CM_ "IMPORT _hyundai_canfd_ccnc_common.dbc";

BO_ 53 ACCELERATOR: 32 XXX
 SG_ CHECKSUM : 0|16@1+ (1,0) [0|65535] "" XXX
 SG_ COUNTER : 16|8@1+ (1,0) [0|255] "" XXX
 SG_ ACCELERATOR_PEDAL : 40|8@1+ (1,0) [0|255] "" XXX
 SG_ GEAR : 192|3@1+ (1,0) [0|7] "" XXX

BO_ 64 GEAR_ALT: 32 XXX
 SG_ CHECKSUM : 0|16@1+ (1,0) [0|65535] "" XXX
 SG_ COUNTER : 16|8@1+ (1,0) [0|255] "" XXX
 SG_ GEAR : 32|3@1+ (1,0) [0|7] "" XXX

BO_ 69 GEAR: 24 XXX
 SG_ CHECKSUM : 0|16@1+ (1,0) [0|65535] "" XXX
 SG_ COUNTER : 16|8@1+ (1,0) [0|255] "" XXX
 SG_ GEAR : 44|3@1+ (1,0) [0|7] "" XXX

BO_ 74 IMU_01_10ms: 32 CGW_CCU
 SG_ IMU_Crc1Val : 0|16@1+ (1,0) [0|0] ""  ECS,ESC,FCU_C,GW_RGW,ICSC,MDPS,RCU,RWS,SFA,VPC_C
 SG_ IMU_AlvCnt1Val : 16|8@1+ (1,0) [0|0] ""  ECS,ESC,FCU_C,GW_RGW,ICSC,MDPS,RCU,RWS,SFA,VPC_C
 SG_ IMU_YawSigSta : 24|4@1+ (1,0) [0|15] ""  CLU,ADAS_PRK,FR_CMR,RR_C_RDR
 SG_ IMU_LatAccelSigSta : 28|4@1+ (1,0) [0|15] ""  CLU,ADAS_PRK,FR_CMR,RR_C_RDR
 SG_ IMU_LongAccelSigSta : 32|4@1+ (1,0) [0|15] ""  CLU,ADAS_PRK,FR_CMR,RR_C_RDR
 SG_ IMU_VerAccelSigSta : 36|4@1+ (1,0) [0|15] "" XXX
 SG_ IMU_McuVoltSta : 40|4@1+ (1,0) [0|15] "" XXX
 SG_ IMU_AcuRstSta : 44|4@1+ (1,0) [0|15] "" XXX
 SG_ IMU_SnsrTyp : 48|8@1+ (1,0) [0|255] "" XXX
 SG_ IMU_RollSigSta : 56|8@1+ (1,0) [0|255] "" XXX
 SG_ IMU_YawRtVal : 64|16@1+ (0.005,-163.84) [-163.84|163.835] "Deg/s"  CLU,ADAS_PRK,FR_CMR,RR_C_RDR
 SG_ IMU_LatAccelVal : 80|16@1+ (0.000127465,-4.17677312) [-4.17677312|4.176645655] "g"  CLU,ADAS_PRK,FR_CMR,RR_C_RDR
 SG_ IMU_LongAccelVal : 96|16@1+ (0.000127465,-4.17677312) [-4.17677312|4.176645655] "g"  CLU,ADAS_PRK,FR_CMR,RR_C_RDR
 SG_ IMU_SnsrTempVal : 112|16@1+ (1,0) [0|65535] "" XXX
 SG_ IMU_SeralNumVal : 128|64@1+ (1,0) [0|1.84467440737096e+19] "" XXX
 SG_ IMU_RollRtVal : 192|16@1+ (0.005,-163.84) [0|0] "º/s" XXX
 SG_ IMU_VerAccelVal : 208|8@1+ (1,0) [0|255] "" XXX

BO_ 96 ESP_STATUS: 32 XXX
 SG_ CHECKSUM : 0|16@1+ (1,0) [0|65535] "" XXX
 SG_ COUNTER : 16|8@1+ (1,0) [0|255] "" XXX
 SG_ TRACTION_AND_STABILITY_CONTROL : 42|3@1+ (1,0) [0|63] "" XXX
 SG_ BRAKE_PRESSURE : 128|10@1+ (1,0) [0|65535] "" XXX
 SG_ BRAKE_PRESSED : 148|1@1+ (1,0) [0|3] "" XXX

BO_ 101 BRAKE: 32 XXX
 SG_ CHECKSUM : 0|16@1+ (1,0) [0|65535] "" XXX
 SG_ COUNTER : 16|8@1+ (1,0) [0|255] "" XXX
 SG_ BRAKE_POSITION : 40|16@1- (1,0) [0|65535] "" XXX
 SG_ BRAKE_PRESSED : 57|1@1+ (1,0) [0|3] "" XXX

BO_ 112 GEAR_ALT_2: 32 XXX
 SG_ CHECKSUM : 0|16@1+ (1,0) [0|65535] "" XXX
 SG_ COUNTER : 16|8@1+ (1,0) [0|255] "" XXX
 SG_ GEAR : 60|3@1+ (1,0) [0|7] "" XXX

BO_ 160 WHEEL_SPEEDS: 24 XXX
 SG_ CHECKSUM : 0|16@1+ (1,0) [0|65535] "" XXX
 SG_ COUNTER : 16|8@1+ (1,0) [0|255] "" XXX
 SG_ MOVING_FORWARD : 56|1@0+ (1,0) [0|1] "" XXX
 SG_ MOVING_BACKWARD : 57|1@0+ (1,0) [0|1] "" XXX
 SG_ MOVING_FORWARD2 : 58|1@0+ (1,0) [0|1] "" XXX
 SG_ MOVING_BACKWARD2 : 59|1@0+ (1,0) [0|1] "" XXX
 SG_ WHL_SpdFLVal : 64|14@1+ (0.03125,0) [0|0] "km^h" XXX
 SG_ WHL_SpdFRVal : 80|14@1+ (0.03125,0) [0|0] "km^h" XXX
 SG_ WHL_SpdRLVal : 96|14@1+ (0.03125,0) [0|0] "km^h" XXX
 SG_ WHL_SpdRRVal : 112|14@1+ (0.03125,0) [0|0] "km^h" XXX

BO_ 203 LFA_ALT: 24 CGW_CCU
 SG_ CHECKSUM : 0|16@1+ (1,0) [0|0] "0" FCU_C,GW_RGW,MDPS,SFA
 SG_ COUNTER : 16|8@1+ (1,0) [0|0] "0" FCU_C,GW_RGW,MDPS,SFA
 SG_ ADAS_ActvACISta : 24|4@1+ (1,0) [0|0] "" GW_RGW,MDPS,SFA
 SG_ ADAS_ActvACILvl2Sta : 28|4@1+ (1,0) [0|0] "" ESC,FCU_C,GW_RGW,MDPS,SFA,VPC_C
 SG_ ADAS_StrAnglReqVal : 32|14@1- (0.1,0) [0|119.9] "Deg" GW_RGW,MDPS,SFA
 SG_ ADAS_ACIAnglTqRedcGainVal : 48|8@1+ (0.004,0) [0|1] "" GW_RGW,MDPS,SFA
 SG_ FCA_ESA_ActvSta : 56|2@1+ (1,0) [0|0] "" GW_RGW,MDPS,SFA
 SG_ FCA_ESA_TqBstGainVal : 64|8@1+ (0.004,0) [0|0] "" GW_RGW,MDPS,SFA

BO_ 229 ESC_02_10ms: 32 CGW
 SG_ ESC_YawSigSta : 24|4@1+ (1,0) [0|15] ""  CLU,ADAS_PRK,FR_CMR,RR_C_RDR
 SG_ ESC_LatAccelSigSta : 28|4@1+ (1,0) [0|15] ""  CLU,ADAS_PRK,FR_CMR,RR_C_RDR
 SG_ ESC_LongAccelSigSta : 32|4@1+ (1,0) [0|15] ""  CLU,ADAS_PRK,FR_CMR,RR_C_RDR
 SG_ ESC_YawRtVal : 64|16@1+ (0.005,-163.84) [-163.84|163.835] "Deg/s"  CLU,ADAS_PRK,FR_CMR,RR_C_RDR
 SG_ ESC_LatAccelVal : 80|16@1+ (0.000127465,-4.17677312) [-4.17677312|4.176645655] "g"  CLU,ADAS_PRK,FR_CMR,RR_C_RDR
 SG_ ESC_LongAccelVal : 96|16@1+ (0.000127465,-4.17677312) [-4.17677312|4.176645655] "g"  CLU,ADAS_PRK,FR_CMR,RR_C_RDR

BO_ 234 MDPS: 24 SFA
 SG_ CHECKSUM : 0|16@1+ (1,0) [0|0] "" CGW_CCU,ESC,ICSC,RCU,RWA,RWS,VPC_C
 SG_ COUNTER : 16|8@1+ (1,0) [0|0] "" CGW_CCU,ESC,ICSC,RCU,RWA,RWS,VPC_C
 SG_ MDPS_WrngLmpSta : 24|3@1+ (1,0) [0|0] "" CGW_CCU,ESC,ICSC,RCU,RWA,RWS
 SG_ MDPS_Typ : 27|3@1+ (1,0) [0|0] "" CGW_CCU,ICSC,RWA
 SG_ MDPS_EngIdleRpmReq : 30|2@1+ (1,0) [0|0] "" CGW_CCU,RWA
 SG_ MDPS_VsmPlgInSta : 32|2@1+ (1,0) [0|0] "flag" ESC,ICSC,RCU,RWA
 SG_ MDPS_VsmDfctvSta : 34|2@1+ (1,0) [0|0] "" ESC,ICSC,RCU,RWA
 SG_ MDPS_VsmSigErrSta : 36|2@1+ (1,0) [0|0] "" ESC,RCU,RWA
 SG_ MDPS_PaPlugInSta : 38|2@1+ (1,0) [0|0] "" CGW_CCU,ESC,RCU,RWA
 SG_ MDPS_PaModeSta : 40|4@1+ (1,0) [0|0] "" CGW_CCU,RWA
 SG_ MDPS_PaCanfltSta : 44|2@1+ (1,0) [0|0] "" CGW_CCU,RWA
 SG_ MDPS_LkaPlgInSta : 46|2@1+ (1,0) [0|0] "" CGW_CCU,ICSC,RWA
 SG_ MDPS_LkaToiActvSta : 48|2@1+ (1,0) [0|0] "" CGW_CCU,RWA
 SG_ MDPS_LkaToiUnblSta : 50|2@1+ (1,0) [0|0] "" CGW_CCU,RWA
 SG_ MDPS_LkaToiFltSta : 52|2@1+ (1,0) [0|0] "" CGW_CCU,RWA
 SG_ MDPS_LkaFailSta : 54|2@1+ (1,0) [0|0] "" CGW_CCU,RWA
 SG_ MDPS_ResetOpSta : 59|2@1+ (1,0) [0|0] "" Vector__XXX
 SG_ MDPS_CurrModVal : 61|3@1+ (1,0) [0|0] "" CGW_CCU,RWA
 SG_ MDPS_OutTqVal : 64|12@1+ (0.1,-204.8) [0|0] "Nm" CGW_CCU,ESC,ICSC,RCU,RWA
 SG_ MDPS_VsmActResp : 76|2@1+ (1,0) [0|0] "" ESC,RCU,RWA
 SG_ Reprogram_State_MDPS : 78|2@1+ (1,0) [0|0] "" CGW_CCU
 SG_ MDPS_StrTqSnsrVal : 80|13@1+ (1,-4095) [0|4095] "" CGW_CCU,ESC,ICSC,RCU,RWA,VPC_C
 SG_ MDPS_PaStrAnglVal : 96|16@1- (0.1,0) [0|0] "Deg" CGW_CCU,RWA
 SG_ MDPS_LoamModSta : 112|2@1+ (1,0) [0|0] "" CGW_CCU,RWA
 SG_ MDPS_HDPSpprtSWVer : 114|5@1+ (1,0) [0|0] "" CGW_CCU,RWA
 SG_ MDPS_ADASAciActvSta : 120|4@1+ (1,0) [0|0] "" CGW_CCU,ESC,RWA,RWS
 SG_ MDPS_ADASAciPluginSta : 124|2@1+ (1,0) [0|0] "" RWA
 SG_ MDPS_ADAS_AciFltSig : 126|2@1+ (1,0) [0|0] "" CGW_CCU,ESC,RWA
 SG_ MDPS_EstStrAnglVal : 128|16@1- (0.1,0) [0|0] "Deg" CGW_CCU,RWA,RWS
 SG_ MDPS_ADASAciActvSta_Lv2 : 144|4@1+ (1,0) [0|0] "" CGW_CCU,RWA
 SG_ MDPS_ADAS_AciFltSig_Lv2 : 148|3@1+ (1,0) [0|0] "" CGW_CCU,RWA
 SG_ MDPS_TpaPlugInSta : 152|2@1+ (1,0) [0|0] "" RWA,VPC_C
 SG_ MDPS_TpaCanfltSta : 154|2@1+ (1,0) [0|0] "" RWA,VPC_C
 SG_ MDPS_TpaModeSta : 156|4@1+ (1,0) [0|0] "" RWA,VPC_C
 SG_ MDPS_TpaStrAnglVal : 160|16@1- (0.1,0) [0|0] "Deg" RWA,VPC_C

BO_ 256 ACCELERATOR_BRAKE_ALT: 32 XXX
 SG_ CHECKSUM : 0|16@1+ (1,0) [0|65535] "" XXX
 SG_ COUNTER : 16|8@1+ (1,0) [0|255] "" XXX
 SG_ BRAKE_PRESSED : 32|1@1+ (1,0) [0|1] "" XXX
 SG_ ACCELERATOR_PEDAL_PRESSED : 176|1@1+ (1,0) [0|1] "" XXX

BO_ 261 ACCELERATOR_ALT: 32 XXX
 SG_ CHECKSUM : 0|16@1+ (1,0) [0|65535] "" XXX
 SG_ COUNTER : 16|8@1+ (1,0) [0|255] "" XXX
 SG_ ACCELERATOR_PEDAL : 103|10@1+ (0.25,0) [0|1022] "" XXX

BO_ 272 LKAS_ALT: 32 XXX
 SG_ CHECKSUM : 0|16@1+ (1,0) [0|65535] "" XXX
 SG_ COUNTER : 16|8@1+ (1,0) [0|255] "" XXX
 SG_ LKA_OptUsmSta : 24|3@1+ (1,0) [0|7] "" ADAS_DRV
 SG_ LKA_RcgSta : 27|3@1+ (1,0) [0|7] "" ADAS_DRV
 SG_ LKA_LHLnWrnSta : 30|2@1+ (1,0) [0|3] "" ADAS_DRV
 SG_ LKA_RHLnWrnSta : 32|2@1+ (1,0) [0|3] "" ADAS_DRV
 SG_ LKA_HndsoffSnd : 34|2@1+ (1,0) [0|3] "" ADAS_DRV
 SG_ LKA_StrSnd : 36|2@1+ (1,0) [0|3] "" ADAS_DRV
 SG_ LKA_SysIndReq : 38|3@1+ (1,0) [0|7] "" ADAS_DRV
 SG_ StrTqReqVal : 41|11@1+ (1,-1024) [0|4095] "" XXX
 SG_ ActToiSta : 52|2@1+ (1,0) [0|3] "" ADAS_DRV
 SG_ ToiFltSta : 54|2@1+ (1,0) [0|3] "" ADAS_DRV
 SG_ LFA_BUTTON : 56|1@1+ (1,0) [0|255] "" XXX
 SG_ LKA_SysWrn : 60|4@1+ (1,0) [0|15] "" ADAS_DRV
 SG_ Damping_Gain : 64|8@1+ (1,0) [0|255] "" CGW
 SG_ LKAS_ANGLE_ACTIVE : 77|2@0+ (1,0) [0|3] "" XXX
 SG_ LKA_UsmMod : 80|2@1+ (1,0) [0|3] "" ADAS_DRV
 SG_ ADAS_StrAnglReqVal : 82|14@1- (0.1,0) [0|176.7] "Deg" GW_RGW,MDPS,SFA
 SG_ ADAS_ACIAnglTqRedcGainVal : 96|8@1+ (0.004,0) [0|1] "" GW_RGW,MDPS,SFA
 SG_ FCA_ESA_CtrlSta : 107|1@0+ (1,0) [0|1] "" XXX
 SG_ NEW_SIGNAL_1 : 72|2@1+ (1,0) [0|3] "" XXX
 SG_ NEW_SIGNAL_2 : 74|2@1+ (1,0) [0|3] "" XXX
 SG_ NEW_SIGNAL_3 : 104|1@1+ (1,0) [0|1] "" XXX
 SG_ NEW_SIGNAL_4 : 105|1@1+ (1,0) [0|1] "" XXX
 SG_ NEW_SIGNAL_5 : 106|1@1+ (1,0) [0|1] "" XXX
 SG_ NEW_SIGNAL_6 : 109|1@1+ (1,0) [0|1] "" XXX
 SG_ NEW_SIGNAL_7 : 225|1@1+ (1,0) [0|1] "" XXX
 SG_ NEW_SIGNAL_8 : 228|1@1+ (1,0) [0|1] "" XXX
 SG_ NEW_SIGNAL_9 : 231|1@1+ (1,0) [0|1] "" XXX
 SG_ NEW_SIGNAL_10 : 232|1@1+ (1,0) [0|1] "" XXX
 SG_ NEW_SIGNAL_11 : 240|16@1+ (1,0) [0|65535] "" XXX

BO_ 282 FR_CMR_01_10ms: 16 FR_CMR
 SG_ FR_CMR_Crc1Val : 0|16@1+ (1,0) [0|0] "" Dummy,IBU_HS,vBDM
 SG_ FR_CMR_AlvCnt1Val : 16|8@1+ (1,0) [0|0] "" CLU,IBU_HS,vBDM
 SG_ HBA_SysOptSta : 24|2@1+ (1,0) [0|3] "" CLU,IBU_HS,vBDM
 SG_ HBA_SysSta : 26|3@1+ (1,0) [0|7] "" CLU,IBU_HS,vBDM
 SG_ HBA_IndLmpReq : 29|2@1+ (1,0) [0|3] "" CLU,vBDM
 SG_ iHBAref_VehLftSta : 31|2@1+ (1,0) [0|3] "" IBU_HS,ICU,vBDM
 SG_ iHBAref_VehCtrSta : 33|2@1+ (1,0) [0|3] "" IBU_HS,ICU,vBDM
 SG_ iHBAref_VehRtSta : 35|2@1+ (1,0) [0|3] "" IBU_HS,ICU,vBDM
 SG_ iHBAref_ILLAmbtSta : 37|2@1+ (1,0) [0|3] "" IBU_HS,ICU,vBDM
 SG_ FCA_Equip_MFC : 39|3@1+ (1,0) [0|0] "" ADAS_DRV,RR_C_RDR,vBDM
 SG_ HBA_OptUsmSta : 42|2@1+ (1,0) [0|3] "" CLU,H_U_MM
 SG_ FCAref_FusSta : 45|3@1+ (1,0) [0|0] "" vBDM
 SG_ DAW_LVDA_PUDis : 48|2@1+ (1,0) [0|0] "" CLU,vBDM
 SG_ DAW_LVDA_OptUsmSta : 50|2@1+ (1,0) [0|3] "" CLU,H_U_MM,vBDM
 SG_ DAW_OptUsmSta : 52|3@1+ (1,0) [0|0] "" CLU,H_U_MM
 SG_ DAW_SysSta : 55|4@1+ (1,0) [0|0] "" CLU
 SG_ DAW_WrnMsgSta : 59|3@1+ (1,0) [0|0] "" CLU
 SG_ DAW_TimeRstReq : 62|2@1+ (1,0) [0|0] "" CLU
 SG_ DAW_SnstvtyModRetVal : 64|3@1+ (1,0) [0|0] "" CLU,H_U_MMz
 SG_ FR_CMR_SCCEquipSta : 85|2@1+ (1,0) [0|3] "" CGW
 SG_ FR_CMR_ReqADASMapMsgVal : 96|16@1+ (1,0) [0|65535] "" CGW
 SG_ FR_CMR_SwVer1Val : 112|4@1+ (1,0) [0|15] "" CGW
 SG_ FR_CMR_SwVer2Val : 120|8@1+ (1,0) [0|255] "" CGW
 SG_ NEW_SIGNAL_1 : 69|2@1+ (1,0) [0|3] "" XXX
 SG_ NEW_SIGNAL_2 : 72|1@1+ (1,0) [0|1] "" XXX
 SG_ NEW_SIGNAL_3 : 74|1@1+ (1,0) [0|1] "" XXX

BO_ 293 STEERING_SENSORS: 16 XXX
 SG_ CHECKSUM : 0|16@1+ (1,0) [0|65535] "" XXX
 SG_ COUNTER : 16|8@1+ (1,0) [0|255] "" XXX
 SG_ STEERING_ANGLE : 24|16@1- (0.1,0) [0|255] "deg" XXX
 SG_ STEERING_RATE : 40|8@1+ (4,0) [0|1016] "deg/s" XXX

BO_ 298 LFA: 16 ADRV
 SG_ CHECKSUM : 0|16@1+ (1,0) [0|65535] "" CLU,CGW
 SG_ COUNTER : 16|8@1+ (1,0) [0|255] "" CLU,CGW
 SG_ LKA_OptUsmSta : 24|3@1+ (1,0) [0|7] "" CLU,CGW
 SG_ LKA_RcgSta : 27|3@1+ (1,0) [0|7] "" CLU,CGW
 SG_ LKA_LHLnWrnSta : 30|2@1+ (1,0) [0|3] "" CLU,CGW
 SG_ LKA_RHLnWrnSta : 32|2@1+ (1,0) [0|3] "" CLU,CGW
 SG_ LKA_HndsoffSnd : 34|2@1+ (1,0) [0|3] "" CLU,CGW
 SG_ LKA_StrSnd : 36|2@1+ (1,0) [0|3] "" CLU,CGW
 SG_ LKA_SysIndReq : 38|3@1+ (1,0) [0|7] "" CLU,RR_C_RDR,CGW
 SG_ StrTqReqVal : 41|11@1+ (1,-1024) [0|4095] "" XXX
 SG_ ActToiSta : 52|2@1+ (1,0) [0|3] "" CLU,CGW
 SG_ ToiFltSta : 54|2@1+ (1,0) [0|3] "" CGW
 SG_ LFA_BUTTON : 56|1@0+ (1,0) [0|255] "" XXX
 SG_ BCA_Rear_WrnSta : 57|3@1+ (1,0) [0|255] "" ADRV
 SG_ LKA_SysWrn : 60|4@1+ (1,0) [0|15] "" CLU,CGW
 SG_ FCA_LO_WrnSta : 64|1@1+ (1,0) [0|1] "" ADRV
 SG_ FCA_LS_WrnSta : 68|1@1+ (1,0) [0|1] "" ADRV
 SG_ LKA_OnOffEquip2Sta : 72|2@1+ (1,0) [0|255] "" ADRV
 SG_ LKA_UsmMod : 80|2@1+ (1,0) [0|3] "" CLU,CGW
 SG_ Info_PedtrnDst : 84|3@0+ (1,0) [0|7] "" ADAS_DRV
 SG_ ELK_SysFlrSta : 85|5@1+ (1,0) [0|31] "" ADRV
 SG_ ELK_SymbDisp : 90|3@1+ (1,0) [0|7] "" ADRV
 SG_ FCA_ESA_WrnSta : 93|1@1+ (1,0) [0|7] "" ADRV
 SG_ FCA_ESA_CtrlSta : 101|1@1+ (1,0) [0|7] "" ADRV
 SG_ Damping_Gain : 104|8@1+ (1,0) [0|255] "" CGW
 SG_ NEW_SIGNAL_1 : 74|2@1+ (1,0) [0|3] "" XXX
 SG_ NEW_SIGNAL_2 : 78|2@1+ (1,0) [0|3] "" XXX
 SG_ NEW_SIGNAL_3 : 98|3@1+ (1,0) [0|7] "" XXX

BO_ 304 GEAR_SHIFTER: 16 XXX
 SG_ CHECKSUM : 0|16@1+ (1,0) [0|65535] "" XXX
 SG_ COUNTER : 16|8@1+ (1,0) [0|255] "" XXX
 SG_ PARK_BUTTON : 32|2@1+ (1,0) [0|3] "" XXX
 SG_ KNOB_POSITION : 40|3@1+ (1,0) [0|3] "" XXX
 SG_ GEAR : 64|3@1+ (1,0) [0|7] "" XXX

BO_ 352 ADRV_0x160: 16 ADRV
 SG_ CHECKSUM : 0|16@1+ (1,0) [0|65535] "" XXX
 SG_ COUNTER : 16|8@1+ (1,0) [0|255] "" XXX
 SG_ AEB_SETTING : 24|2@1+ (1,0) [0|255] "" XXX
 SG_ SET_ME_2 : 56|8@1+ (1,0) [0|1] "" XXX
 SG_ SET_ME_FF : 64|8@1+ (1,0) [0|255] "" XXX
 SG_ SET_ME_FC : 72|8@1+ (1,0) [0|255] "" XXX
 SG_ SET_ME_9 : 80|8@1+ (1,0) [0|255] "" XXX
 SG_ NEW_SIGNAL_1 : 30|1@1+ (1,0) [0|1] "" XXX
 SG_ NEW_SIGNAL_2 : 48|1@1+ (1,0) [0|1] "" XXX
 SG_ NEW_SIGNAL_3 : 55|1@1+ (1,0) [0|1] "" XXX
 SG_ NEW_SIGNAL_4 : 88|1@1+ (1,0) [0|1] "" XXX
 SG_ NEW_SIGNAL_5 : 90|1@1+ (1,0) [0|1] "" XXX
 SG_ NEW_SIGNAL_6 : 99|1@1+ (1,0) [0|1] "" XXX
 SG_ NEW_SIGNAL_7 : 115|2@1+ (1,0) [0|3] "" XXX

BO_ 353 CCNC_0x161: 32 CCNC
 SG_ CHECKSUM : 0|16@1+ (1,0) [0|65535] "" XXX
 SG_ COUNTER : 16|8@1+ (1,0) [0|255] "" XXX
 SG_ FCA_ICON : 24|3@1+ (1,0) [0|7] "" XXX
 SG_ FCA_ALT_ICON : 27|3@1+ (1,0) [0|7] "" XXX
 SG_ LKA_ICON : 30|3@1+ (1,0) [0|3] "" XXX
 SG_ HBA_ICON : 33|3@1+ (1,0) [0|7] "" XXX
 SG_ ZEROS_1 : 36|4@1+ (1,0) [0|15] "" XXX
 SG_ ZEROS_2 : 40|2@1+ (1,0) [0|3] "" XXX
 SG_ FCA_IMAGE : 42|3@1+ (1,0) [0|7] "" XXX
 SG_ ZEROS_3 : 45|3@1+ (1,0) [0|7] "" XXX
 SG_ ZEROS_4 : 48|3@1+ (1,0) [0|7] "" XXX
 SG_ BCA_LEFT : 51|3@1+ (1,0) [0|7] "" XXX
 SG_ BCA_RIGHT : 54|3@1+ (1,0) [0|7] "" XXX
 SG_ LCA_LEFT_ARROW : 57|3@1+ (1,0) [0|7] "" XXX
 SG_ LCA_RIGHT_ARROW : 60|3@1+ (1,0) [0|7] "" XXX
 SG_ ZEROS_5 : 63|1@0+ (1,0) [0|1] "" XXX
 SG_ CENTERLINE : 64|2@1+ (1,0) [0|3] "" XXX
 SG_ TARGET : 66|3@1+ (1,0) [0|7] "" XXX
 SG_ TARGET_DISTANCE : 69|11@1+ (0.1,0) [0|204.7] "m" XXX
 SG_ LANELINE_LEFT : 80|4@1+ (1,0) [0|15] "" XXX
 SG_ LANELINE_LEFT_POSITION : 84|6@1+ (1,0) [0|15] "" XXX
 SG_ LANELINE_RIGHT : 90|4@1+ (1,0) [0|15] "" XXX
 SG_ LANELINE_RIGHT_POSITION : 94|6@1+ (1,0) [0|3] "" XXX
 SG_ LANELINE_CURVATURE : 100|5@1- (1,15) [0|31] "" XXX
 SG_ LANE_HIGHLIGHT : 105|4@1+ (1,0) [0|15] "" XXX
 SG_ LANE_HIGHLIGHT_DISTANCE : 109|11@1+ (0.1,0) [0|204.7] "m" XXX
 SG_ LANE_LEFT : 120|3@1+ (1,0) [0|7] "" XXX
 SG_ LANE_RIGHT : 123|3@1+ (1,0) [0|7] "" XXX
 SG_ LANE_ZOOM : 126|2@1+ (1,0) [0|3] "" XXX
 SG_ ALERTS_1 : 128|6@1+ (1,0) [0|63] "" XXX
 SG_ ALERTS_2 : 134|5@1+ (1,0) [0|3] "" XXX
 SG_ ALERTS_3 : 139|5@1+ (1,0) [0|15] "" XXX
 SG_ ALERTS_4 : 144|8@1+ (1,0) [0|511] "" XXX
 SG_ ALERTS_5 : 152|5@1+ (1,0) [0|7] "" XXX
 SG_ MUTE : 157|3@1+ (1,0) [0|7] "" XXX
 SG_ SOUNDS_1 : 160|4@1+ (1,0) [0|3] "" XXX
 SG_ SOUNDS_2 : 164|4@1+ (1,0) [0|3] "" XXX
 SG_ SOUNDS_3 : 168|4@1+ (1,0) [0|15] "" XXX
 SG_ SOUNDS_4 : 172|3@1+ (1,0) [0|7] "" XXX
 SG_ ZEROS_6 : 175|1@0+ (1,0) [0|1] "" XXX
 SG_ ZEROS_7 : 176|5@1+ (1,0) [0|31] "" XXX
 SG_ SETSPEED_HUD : 181|3@1+ (1,0) [0|3] "" XXX
 SG_ DISTANCE_LEAD : 184|5@1+ (1,0) [0|31] "" XXX
 SG_ DISTANCE_CAR : 189|3@1+ (1,0) [0|7] "" XXX
 SG_ DISTANCE_SPACING : 192|4@1+ (1,0) [0|15] "" XXX
 SG_ DISTANCE : 196|4@1+ (1,0) [0|7] "" XXX
 SG_ SETSPEED_SPEED : 200|8@1+ (1,0) [0|255] "" XXX
 SG_ SETSPEED : 208|4@1+ (1,0) [0|3] "" XXX
 SG_ HDA_ICON : 212|4@1+ (1,0) [0|3] "" XXX
 SG_ SLA_ICON : 216|4@1+ (1,0) [0|15] "" XXX
 SG_ NAV_ICON : 220|4@1+ (1,0) [0|3] "" XXX
 SG_ LFA_ICON : 224|4@1+ (1,0) [0|3] "" XXX
 SG_ LCA_LEFT_ICON : 228|4@1+ (1,0) [0|15] "" XXX
 SG_ LCA_RIGHT_ICON : 232|4@1+ (1,0) [0|15] "" XXX
 SG_ BACKGROUND : 236|4@1+ (1,0) [0|15] "" XXX
 SG_ DAW_ICON : 240|3@1+ (1,0) [0|7] "" XXX
 SG_ CAR_CIRCLE : 243|3@1+ (1,0) [0|7] "" XXX
 SG_ ZEROS_8 : 246|2@1+ (1,0) [0|3] "" XXX
 SG_ ZEROS_9 : 248|8@1+ (1,0) [0|255] "" XXX

BO_ 354 CCNC_0x162: 32 CCNC
 SG_ CHECKSUM : 0|16@1+ (1,0) [0|65535] "" XXX
 SG_ COUNTER : 16|8@1+ (1,0) [0|255] "" XXX
 SG_ COUNTRY : 24|4@1+ (1,0) [0|7] "" XXX
 SG_ SPEEDLIMIT_FLASH : 28|4@1+ (1,0) [0|15] "" XXX
 SG_ SPEEDLIMIT : 32|8@1+ (1,0) [0|255] "" XXX
 SG_ SIGNS : 40|8@1+ (1,0) [0|15] "" XXX
 SG_ SPEEDLIMIT_WEATHER : 48|4@1+ (1,0) [0|15] "" XXX
 SG_ VIBRATE : 52|3@1+ (1,0) [0|7] "" XXX
 SG_ ZEROS_1 : 55|1@0+ (1,0) [0|1] "" XXX
 SG_ ZEROS_2 : 56|8@1+ (1,0) [0|255] "" XXX
 SG_ LEAD : 64|5@1+ (1,0) [0|31] "" XXX
 SG_ LEAD_DISTANCE : 69|11@1+ (0.1,0) [0|204.7] "m" XXX
 SG_ LEAD_LATERAL : 80|7@1+ (0.1,0) [0|127] "m" XXX
 SG_ ZEROS_3 : 87|1@0+ (1,0) [0|1] "" XXX
 SG_ LEAD_ALT : 88|5@1+ (1,0) [0|31] "" XXX
 SG_ LEAD_ALT_DISTANCE : 93|11@1+ (0.1,0) [0|204.7] "m" XXX
 SG_ LEAD_ALT_LATERAL : 104|7@1+ (0.1,0) [0|127] "m" XXX
 SG_ ZEROS_4 : 111|1@0+ (1,0) [0|1] "" XXX
 SG_ LEAD_LEFT : 112|5@1+ (1,0) [0|31] "" XXX
 SG_ LEAD_LEFT_DISTANCE : 117|11@1+ (0.1,0) [0|204.7] "m" XXX
 SG_ LEAD_LEFT_LATERAL : 128|7@1+ (0.1,0) [0|127] "m" XXX
 SG_ ZEROS_5 : 135|1@0+ (1,0) [0|1] "" XXX
 SG_ LEAD_RIGHT : 136|5@1+ (1,0) [0|31] "" XXX
 SG_ LEAD_RIGHT_DISTANCE : 141|11@1+ (0.1,0) [0|204.7] "m" XXX
 SG_ LEAD_RIGHT_LATERAL : 152|7@1+ (0.1,0) [0|127] "m" XXX
 SG_ ZEROS_6 : 159|1@0+ (1,0) [0|1] "" XXX
 SG_ ZEROS_7 : 162|3@0+ (1,0) [0|7] "" XXX
 SG_ LEAD_LEFT_REAR_STATUS : 167|5@0+ (1,0) [0|31] "" XXX
 SG_ LEAD_LEFT_REAR_DISTANCE : 175|8@0+ (0.1,0) [0|255] "m" XXX
 SG_ LEAD_LEFT_REAR_LATERAL : 182|7@0+ (0.1,0) [0|127] "m" XXX
 SG_ ZEROS_8 : 183|1@0+ (1,0) [0|1] "" XXX
 SG_ ZEROS_9 : 191|8@0+ (1,0) [0|255] "" XXX
 SG_ LEAD_RIGHT_REAR_STATUS : 196|5@0+ (1,0) [0|31] "" XXX
 SG_ LEAD_RIGHT_REAR_DISTANCE : 197|8@1+ (0.1,0) [0|255] "m" XXX
 SG_ LEAD_RIGHT_REAR_LATERAL : 205|7@1+ (0.1,0) [0|127] "m" XXX
 SG_ ZEROS_10 : 212|1@0+ (1,0) [0|1] "" XXX
 SG_ FAULT_FSS : 213|3@1+ (1,0) [0|7] "" XXX
 SG_ FAULT_FCA : 216|3@1+ (1,0) [0|7] "" XXX
 SG_ FAULT_LSS : 219|3@1+ (1,0) [0|7] "" XXX
 SG_ FAULT_SLA : 222|3@1+ (1,0) [0|7] "" XXX
 SG_ FAULT_DAW : 225|3@1+ (1,0) [0|7] "" XXX
 SG_ FAULT_HBA : 228|3@1+ (1,0) [0|7] "" XXX
 SG_ FAULT_SCC : 231|3@1+ (1,0) [0|7] "" XXX
 SG_ FAULT_LFA : 234|3@1+ (1,0) [0|7] "" XXX
 SG_ FAULT_HDA : 237|3@1+ (1,0) [0|7] "" XXX
 SG_ FAULT_LCA : 240|3@1+ (1,0) [0|7] "" XXX
 SG_ FAULT_HDP : 243|3@1+ (1,0) [0|7] "" XXX
 SG_ FAULT_DAS : 246|3@1+ (1,0) [0|7] "" XXX
 SG_ FAULT_ESS : 249|3@1+ (1,0) [0|7] "" XXX
 SG_ ZEROS_11 : 252|4@1+ (1,0) [0|15] "" XXX

BO_ 357 SPAS1: 24 APRK
 SG_ CHECKSUM : 0|16@1+ (1,0) [0|65535] "" XXX
 SG_ COUNTER : 16|8@1+ (1,0) [0|0] "" XXX
 SG_ NEW_SIGNAL_2 : 90|3@1+ (1,0) [0|0] "" XXX
 SG_ NEW_SIGNAL_1 : 96|16@1- (0.1,0) [0|0] "" XXX

BO_ 362 SPAS2: 32 APRK
 SG_ CHECKSUM : 0|16@1+ (1,0) [0|65535] "" XXX
 SG_ COUNTER : 16|8@1+ (1,0) [0|0] "" XXX
 SG_ BLINKER_CONTROL : 133|3@1+ (1,0) [0|0] "" XXX

BO_ 373 TCS: 24 XXX
 SG_ CHECKSUM : 0|16@1+ (1,0) [0|65535] "" XXX
 SG_ COUNTER : 16|8@1+ (1,0) [0|255] "" XXX
 SG_ NEW_SIGNAL_4 : 24|7@1+ (1,0) [0|127] "" XXX
 SG_ aBasis : 32|11@1+ (0.01,-10.23) [0|7] "m/s^2" XXX
 SG_ ACCEL_REF_ACC : 48|11@1- (1,0) [0|1023] "" XXX
 SG_ EQUIP_MAYBE : 64|1@0+ (1,0) [0|1] "" XXX
 SG_ ACCEnable : 67|2@0+ (1,0) [0|3] "" XXX
 SG_ ACC_REQ : 68|1@0+ (1,0) [0|1] "" XXX
 SG_ NEW_SIGNAL_5 : 72|1@0+ (1,0) [0|1] "" XXX
 SG_ NEW_SIGNAL_2 : 74|1@0+ (1,0) [0|1] "" XXX
 SG_ NEW_SIGNAL_3 : 76|1@0+ (1,0) [0|1] "" XXX
 SG_ NEW_SIGNAL_1 : 80|1@0+ (1,0) [0|1] "" XXX
 SG_ DriverBraking : 81|1@0+ (1,0) [0|1] "" XXX
 SG_ DriverBrakingLowSens : 84|1@1+ (1,0) [0|1] "" XXX
 SG_ AEB_EQUIP_MAYBE : 96|1@0+ (1,0) [0|1] "" XXX
 SG_ NEW_SIGNAL_6 : 128|4@1+ (1,0) [0|15] "" XXX
 SG_ NEW_SIGNAL_7 : 135|2@0+ (1,0) [0|3] "" XXX
 SG_ PROBABLY_EQUIP : 136|2@1+ (1,0) [0|3] "" XXX

BO_ 416 SCC_CONTROL: 32 ADRV
 SG_ CHECKSUM : 0|16@1+ (1,0) [0|65535] "" XXX
 SG_ COUNTER : 16|8@1+ (1,0) [0|255] "" XXX
 SG_ ACC_ObjDist : 24|11@1+ (0.1,0) [0|204.7] "m" XXX
 SG_ ACC_ObjRelSpd : 35|9@1+ (0.1,-16.4) [-16.4|34.7] "m/s" XXX
 SG_ SET_ME_3 : 45|2@0+ (1,0) [0|3] "" XXX
 SG_ ObjValid : 46|1@0+ (1,0) [0|3] "" XXX
 SG_ SET_ME_TMP_64 : 55|8@0+ (1,0) [0|63] "" XXX
 SG_ ZEROS_7 : 63|8@0+ (1,0) [0|255] "" XXX
 SG_ NEW_SIGNAL_1 : 64|2@1+ (1,0) [0|3] "" XXX
 SG_ MainMode_ACC : 66|1@1+ (1,0) [0|1] "" XXX
 SG_ ACCMode : 68|3@1+ (1,0) [0|7] "" XXX
 SG_ ZEROS_9 : 71|5@1+ (1,0) [0|15] "" XXX
 SG_ CRUISE_STANDSTILL : 76|1@1+ (1,0) [0|1] "" XXX
 SG_ ZEROS_5 : 77|11@1+ (1,0) [0|2047] "" XXX
 SG_ DISTANCE_SETTING : 88|3@1+ (1,0) [0|3] "" XXX
 SG_ ZEROS_8 : 95|5@0+ (1,0) [0|31] "" XXX
 SG_ VSetDis : 103|8@0+ (1,0) [0|255] "km/h or mph" XXX
 SG_ NEW_SIGNAL_6 : 104|1@0+ (1,0) [0|1] "" XXX
 SG_ SET_ME_2 : 105|3@1+ (1,0) [0|7] "" XXX
 SG_ SCC_ObjSta : 108|3@1+ (1,0) [0|7] ""  CLU,CGW
 SG_ ZEROS_10 : 111|1@0+ (1,0) [0|1] "" XXX
 SG_ ZEROS_6 : 119|16@0+ (1,0) [0|65535] "" XXX
 SG_ aReqValue : 128|11@1+ (0.01,-10.23) [-10.23|10.24] "m/s^2" XXX
 SG_ aReqRaw : 140|11@1+ (0.01,-10.23) [-10.23|10.24] "m/s^2" XXX
 SG_ JerkUpperLimit : 158|7@0+ (0.1,0) [0|0] "" XXX
 SG_ JerkLowerLimit : 166|7@0+ (0.1,0) [0|12.7] "m/s^3" XXX
 SG_ NEW_SIGNAL_2 : 168|2@1+ (1,0) [0|3] "" XXX
 SG_ NEW_SIGNAL_8 : 170|4@1+ (1,0) [0|15] "" XXX
 SG_ OBJ_STATUS : 176|3@1+ (1,0) [0|7] "" XXX
 SG_ ZEROS_4 : 183|4@0+ (1,0) [0|63] "" XXX
 SG_ StopReq : 184|1@0+ (1,0) [0|1] "" XXX
 SG_ ZEROS_3 : 191|7@0+ (1,0) [0|127] "" XXX
 SG_ NEW_SIGNAL_15 : 192|11@1+ (0.1,0) [0|204.7] "m" XXX
 SG_ ZEROS_2 : 207|5@0+ (1,0) [0|63] "" XXX
 SG_ ZEROS : 215|48@0+ (1,0) [0|281474976710655] "" XXX

BO_ 426 CRUISE_BUTTONS_ALT: 16 XXX
 SG_ CHECKSUM : 0|16@1+ (1,0) [0|65535] "" XXX
 SG_ COUNTER : 16|8@1+ (1,0) [0|255] "" XXX
 SG_ NEW_SIGNAL_1 : 24|4@1+ (1,0) [0|15] "" XXX
 SG_ SET_ME_1 : 28|2@1+ (1,0) [0|3] "" XXX
 SG_ DISTANCE_UNIT : 30|1@1+ (1,0) [0|1] "" XXX
 SG_ NEW_SIGNAL_2 : 31|3@1+ (1,0) [0|7] "" XXX
 SG_ ADAPTIVE_CRUISE_MAIN_BTN : 34|1@1+ (1,0) [0|1] "" XXX
 SG_ NEW_SIGNAL_3 : 35|1@1+ (1,0) [0|1] "" XXX
 SG_ CRUISE_BUTTONS : 36|3@1+ (1,0) [0|4] "" XXX
 SG_ LDA_BTN : 39|1@1+ (1,0) [0|1] "" XXX
 SG_ NEW_SIGNAL_4 : 40|1@1+ (1,0) [0|1] "" XXX
 SG_ NORMAL_CRUISE_MAIN_BTN : 41|1@1+ (1,0) [0|1] "" XXX
 SG_ NEW_SIGNAL_5 : 42|2@1+ (1,0) [0|3] "" XXX
 SG_ SET_ME_2 : 44|3@1+ (1,0) [0|7] "" XXX
 SG_ NEW_SIGNAL_6 : 47|1@1+ (1,0) [0|1] "" XXX
 SG_ BYTE6 : 48|8@1+ (1,0) [0|255] "" XXX
 SG_ BYTE7 : 56|8@1+ (1,0) [0|255] "" XXX
 SG_ BYTE8 : 64|8@1+ (1,0) [0|255] "" XXX
 SG_ BYTE9 : 72|8@1+ (1,0) [0|255] "" XXX
 SG_ BYTE10 : 80|8@1+ (1,0) [0|255] "" XXX
 SG_ BYTE11 : 88|8@1+ (1,0) [0|255] "" XXX
 SG_ BYTE12 : 96|8@1+ (1,0) [0|255] "" XXX
 SG_ BYTE13 : 104|8@1+ (1,0) [0|255] "" XXX
 SG_ BYTE14 : 112|8@1+ (1,0) [0|255] "" XXX
 SG_ BYTE15 : 120|8@1+ (1,0) [0|255] "" XXX

BO_ 437 FR_CMR_03_50ms: 32 FR_CMR
 SG_ FR_CMR_Crc3Val : 0|16@1+ (1,0) [0|65535] "" RR_C_RDR,CGW
 SG_ FR_CMR_AlvCnt3Val : 16|8@1+ (1,0) [0|255] "" RR_C_RDR,CGW
 SG_ Info_LftLnQualSta : 24|3@1+ (1,0) [0|7] "" RR_C_RDR,CGW
 SG_ Info_LftLnDptSta : 27|2@1+ (1,0) [0|3] "" RR_C_RDR,CGW
 SG_ Info_LftLnPosVal : 29|14@1- (0.0039625,0) [-32.4608|32.4568375] "m" RR_C_RDR,CGW
 SG_ Info_LftLnHdingAnglVal : 43|10@1- (0.000976563,0) [-0.500000256|0.499023693] "rad" RR_C_RDR,CGW
 SG_ Info_LftLnCvtrVal : 64|16@1- (1e-06,0) [-0.032768|0.032767] "1/m" CGW
 SG_ Info_LftLnCrvtrDrvtvVal : 80|16@1- (4e-09,0) [-0.000131072|0.000131068] "1/m2" CGW
 SG_ Info_RtLnQualSta : 96|3@1+ (1,0) [0|7] "" RR_C_RDR,CGW
 SG_ Info_RtLnDptSta : 99|2@1+ (1,0) [0|3] "" RR_C_RDR,CGW
 SG_ Info_RtLnPosVal : 101|14@1- (0.0039625,0) [-32.4608|32.4568375] "m" RR_C_RDR,CGW
 SG_ Info_RtLnHdingAnglVal : 115|10@1- (0.000976563,0) [-0.500000256|0.499023693] "rad" RR_C_RDR,CGW
 SG_ Info_RtLnCvtrVal : 128|16@1- (1e-06,0) [-0.032768|0.032767] "1/m" CGW
 SG_ Info_RtLnCrvtrDrvtvVal : 144|16@1- (4e-09,0) [-0.000131072|0.000131068] "1/m2" CGW
 SG_ ID_CIPV : 192|8@1+ (1,0) [0|255] "" XXX
 SG_ Relative_Velocity : 200|12@1+ (0.05,-100) [-100|104.75] "m/s" XXX
 SG_ Longitudinal_Distance : 212|12@1+ (0.05,0) [0|204.75] "m" XXX

BO_ 442 ADAS_CMD_50_50ms: 24 XXX
 SG_ ADAS_CMD_Crc50Val : 0|16@1+ (1,0) [0|65535] "" XXX
 SG_ ADAS_CMD_AlvCnt50Val : 16|8@1+ (1,0) [0|255] "" XXX
 SG_ BCW_Sta : 24|1@0+ (1,0) [0|1] "" XXX
 SG_ BCW_OnOffEquipSta : 28|2@1+ (1,0) [0|3] "" XXX
 SG_ BCW_LtIndSta : 31|2@0+ (1,0) [0|3] "" XXX
 SG_ BCW_RtIndSta : 32|2@1+ (1,0) [0|3] "" XXX
 SG_ BCW_LtSndWrngSta : 34|2@1+ (1,0) [0|3] "" XXX
 SG_ BCW_RtSndWrngSta : 36|10@1+ (1,0) [0|1023] "" XXX
 SG_ BCW_SnstvtyModRetVal : 56|3@1+ (1,0) [0|7] "" XXX
 SG_ BCW_IndSta : 59|3@1+ (1,0) [0|7] "" XXX
 SG_ BCA_OnOffEquip2Sta : 62|2@1+ (1,0) [0|3] "" XXX
 SG_ BCA_Sta : 64|1@0+ (1,0) [0|1] "" XXX
 SG_ BCA_OnOffEquipSta : 68|1@0+ (1,0) [0|1] "" XXX
 SG_ BCA_DRV_WarnSta : 76|4@1+ (1,0) [0|15] "" XXX
 SG_ BCA_Plus_Deccel_Req : 80|4@1+ (1,0) [0|15] "" XXX
 SG_ BCA_Plus_BrkCmdSta : 84|2@1+ (1,0) [0|3] "" XXX
 SG_ BCA_Plus_LtWrngSta : 86|2@1+ (1,0) [0|3] "" XXX
 SG_ BCA_Plus_RtWrngSta : 88|5@1+ (1,0) [0|31] "" XXX
 SG_ BCA_Plus_FuncStat : 93|3@1+ (1,0) [0|7] "" XXX
 SG_ BCA_Plus_Sta : 96|1@0+ (1,0) [0|1] "" XXX
 SG_ Brake_Control_RL : 110|2@1+ (1,0) [0|3] "" XXX
 SG_ Brake_Control_RR : 118|2@1+ (1,0) [0|3] "" XXX
 SG_ OSMrrLamp_LtIndSta : 128|2@1+ (1,0) [0|3] "" XXX
 SG_ OSMrrLamp_RtIndSta : 130|6@1+ (1,0) [0|63] "" XXX

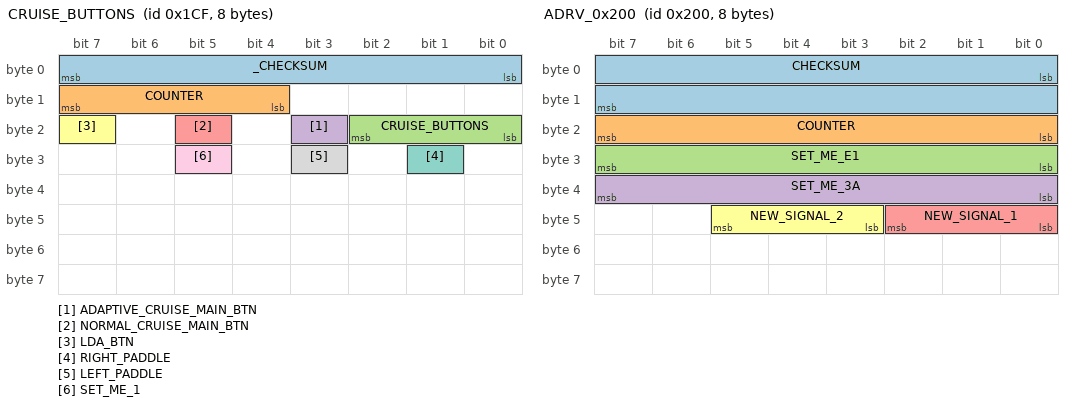
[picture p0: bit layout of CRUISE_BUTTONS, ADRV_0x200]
BO_ 463 CRUISE_BUTTONS: 8 XXX
 SG_ _CHECKSUM : 0|8@1+ (1,0) [0|65535] "" XXX
 SG_ COUNTER : 12|4@1+ (1,0) [0|255] "" XXX
 SG_ CRUISE_BUTTONS : 16|3@1+ (1,0) [0|3] "" XXX
 SG_ ADAPTIVE_CRUISE_MAIN_BTN : 19|1@1+ (1,0) [0|1] "" XXX
 SG_ NORMAL_CRUISE_MAIN_BTN : 21|1@1+ (1,0) [0|1] "" XXX
 SG_ LDA_BTN : 23|1@1+ (1,0) [0|1] "" XXX
 SG_ RIGHT_PADDLE : 25|1@1+ (1,0) [0|1] "" XXX
 SG_ LEFT_PADDLE : 27|1@1+ (1,0) [0|1] "" XXX
 SG_ SET_ME_1 : 29|1@1+ (1,0) [0|1] "" XXX

BO_ 474 ADRV_0x1da: 32 ADRV
 SG_ CHECKSUM : 0|16@1+ (1,0) [0|65535] "" XXX
 SG_ COUNTER : 16|8@1+ (1,0) [0|255] "" XXX
 SG_ SET_ME_22 : 31|8@0+ (1,0) [0|255] "" XXX
 SG_ SET_ME_41 : 47|8@0+ (1,0) [0|255] "" XXX

BO_ 480 LFAHDA_CLUSTER: 16 ADRV
 SG_ CHECKSUM : 0|16@1+ (1,0) [0|65535] "" XXX
 SG_ COUNTER : 16|8@1+ (1,0) [0|255] "" XXX
 SG_ NEW_SIGNAL_4 : 24|1@0+ (1,0) [0|1] "" XXX
 SG_ NEW_SIGNAL_5 : 25|1@0+ (1,0) [0|1] "" XXX
 SG_ NEW_SIGNAL_2 : 30|1@0+ (1,0) [0|1] "" XXX
 SG_ HDA_ICON : 31|1@1+ (1,0) [0|1] "" XXX
 SG_ NEW_SIGNAL_1 : 32|3@1+ (1,0) [0|7] "" XXX
 SG_ LFA_ICON : 47|2@1+ (1,0) [0|3] "" XXX
 SG_ NEW_SIGNAL_3 : 49|1@0+ (1,0) [0|1] "" XXX
 SG_ CAM_FAULT : 26|1@1+ (1,0) [0|1] "" XXX
 SG_ LFA_HANDSOFF_CANCEL : 51|1@1+ (1,0) [0|1] "" XXX

BO_ 485 BLINDSPOTS_FRONT_CORNER_1: 16 XXX
 SG_ CHECKSUM : 0|16@1+ (1,0) [0|65535] "" XXX
 SG_ COUNTER : 16|8@1+ (1,0) [0|255] "" XXX
 SG_ REVERSING : 24|1@0+ (1,0) [0|1] "" XXX
 SG_ NEW_SIGNAL_5 : 31|2@0+ (1,0) [0|3] "" XXX
 SG_ NEW_SIGNAL_7 : 32|2@1+ (1,0) [0|3] "" XXX
 SG_ NEW_SIGNAL_8 : 47|8@0+ (1,0) [0|255] "" XXX
 SG_ NEW_SIGNAL_9 : 55|8@0+ (1,0) [0|255] "" XXX
 SG_ NEW_SIGNAL_4 : 80|1@0+ (1,0) [0|1] "" XXX
 SG_ NEW_SIGNAL_3 : 88|1@0+ (1,0) [0|1] "" XXX
 SG_ NEW_SIGNAL_2 : 96|1@0+ (1,0) [0|1] "" XXX
 SG_ NEW_SIGNAL_1 : 108|2@0+ (1,0) [0|3] "" XXX

BO_ 490 ADRV_0x1ea: 32 ADRV
 SG_ CHECKSUM : 0|16@1+ (1,0) [0|65535] "" XXX
 SG_ COUNTER : 16|8@1+ (1,0) [0|255] "" XXX
 SG_ SET_ME_1C : 31|8@0+ (1,0) [0|255] "" XXX
 SG_ NEW_SIGNAL_1 : 32|2@1+ (1,0) [0|3] "" XXX
 SG_ NEW_SIGNAL_2 : 47|2@0+ (1,0) [0|3] "" XXX
 SG_ NEW_SIGNAL_3 : 55|8@0+ (1,0) [0|255] "" XXX
 SG_ NEW_SIGNAL_4 : 64|6@1+ (1,0) [0|31] "" XXX
 SG_ NEW_SIGNAL_5 : 72|2@1+ (1,0) [0|3] "" XXX
 SG_ NEW_SIGNAL_6 : 75|5@1+ (1,0) [0|31] "" XXX
 SG_ NEW_SIGNAL_7 : 80|5@1+ (1,0) [0|31] "" XXX
 SG_ NEW_SIGNAL_8 : 88|7@1+ (1,0) [0|127] "" XXX
 SG_ NEW_SIGNAL_9 : 96|1@0+ (1,0) [0|1] "" XXX
 SG_ SET_ME_FF : 120|8@1+ (1,0) [0|255] "" XXX
 SG_ NEW_SIGNAL_10 : 143|5@0+ (1,0) [0|31] "" XXX
 SG_ NEW_SIGNAL_11 : 144|3@1+ (1,0) [0|7] "" XXX
 SG_ NEW_SIGNAL_12 : 152|6@1+ (1,0) [0|63] "" XXX
 SG_ NEW_SIGNAL_13 : 160|1@0+ (1,0) [0|1] "" XXX
 SG_ NEW_SIGNAL_14 : 163|5@1+ (1,0) [0|31] "" XXX
 SG_ NEW_SIGNAL_16 : 168|3@1+ (1,0) [0|7] "" XXX
 SG_ NEW_SIGNAL_15 : 175|4@0+ (1,0) [0|63] "" XXX
 SG_ NEW_SIGNAL_17 : 176|2@1+ (1,0) [0|3] "" XXX
 SG_ NEW_SIGNAL_18 : 184|1@0+ (1,0) [0|1] "" XXX
 SG_ NEW_SIGNAL_19 : 208|3@1+ (1,0) [0|7] "" XXX
 SG_ NEW_SIGNAL_20 : 212|1@0+ (1,0) [0|1] "" XXX
 SG_ SET_ME_TMP_F : 232|5@1+ (1,0) [0|31] "" XXX
 SG_ SET_ME_TMP_F_2 : 240|5@1+ (1,0) [0|31] "" XXX

BO_ 506 FR_CMR_02_100ms: 32 FR_CMR
 SG_ FR_CMR_Crc2Val : 0|16@1+ (1,0) [0|65535] "" CGW
 SG_ FR_CMR_AlvCnt2Val : 16|8@1+ (1,0) [0|255] "" CGW
 SG_ ISLW_OptUsmSta : 24|2@1+ (1,0) [0|3] "" CLU,CGW
 SG_ ISLW_SysSta : 26|2@1+ (1,0) [0|3] "" CLU,CGW
 SG_ ISLW_NoPassingInfoDis : 28|3@1+ (1,0) [0|7] "" CLU,CGW
 SG_ ISLW_OvrlpSignDis : 31|2@1+ (1,0) [0|3] "" CLU,CGW
 SG_ ISLW_SpdCluMainDis : 33|8@1+ (1,0) [0|255] "" CLU,CGW
 SG_ ISLW_SpdNaviMainDis : 41|8@1+ (1,0) [0|255] "" CGW
 SG_ ISLW_SubCondinfoSta1 : 49|4@1+ (1,0) [0|15] "" CLU,CGW
 SG_ ISLW_SubCondinfoSta2 : 53|4@1+ (1,0) [0|15] "" CLU,CGW
 SG_ ISLW_SpdCluSubMainDis : 64|8@1+ (1,0) [0|255] "" CLU
 SG_ ISLW_SpdCluDisSubCond1 : 72|8@1+ (1,0) [0|255] "" CLU,CGW
 SG_ ISLW_SpdCluDisSubCond2 : 80|8@1+ (1,0) [0|255] "" CLU,CGW
 SG_ ISLW_SpdNaviSubMainDis : 88|8@1+ (1,0) [0|255] "" CLU
 SG_ ISLW_SpdNaviDisSubCond1 : 96|8@1+ (1,0) [0|255] "" CLU,CGW
 SG_ ISLW_SpdNaviDisSubCond2 : 104|8@1+ (1,0) [0|255] "" CLU,CGW
 SG_ ISLA_SpdwOffst : 112|8@1+ (1,0) [0|255] "" CLU,CGW
 SG_ ISLA_SwIgnoreReq : 120|2@1+ (1,0) [0|3] "" CGW
 SG_ ISLA_SpdChgReq : 122|2@1+ (1,0) [0|3] "" CGW
 SG_ ISLA_SpdWrn : 124|2@1+ (1,0) [0|3] "" CLU,CGW
 SG_ ISLA_IcyWrn : 126|2@1+ (1,0) [0|3] "" CLU,CGW
 SG_ ISLA_SymFlashMod : 128|3@1+ (1,0) [0|7] "" CLU,CGW
 SG_ ISLA_Popup : 131|3@1+ (1,0) [0|7] "" CLU
 SG_ ISLA_OptUsmSta : 136|3@1+ (1,0) [0|7] "" CLU,CGW
 SG_ ISLA_OffstUsmSta : 139|3@1+ (1,0) [0|7] "" CLU,CGW
 SG_ ISLA_AutoUsmSta : 142|2@1+ (1,0) [0|3] "" CLU,CGW
 SG_ ISLA_Cntry : 144|4@1+ (1,0) [0|15] "" CLU,CGW
 SG_ ISLA_AddtnlSign : 149|5@1+ (1,0) [0|31] "" CLU,CGW
 SG_ ISLA_SchoolZone : 154|2@1+ (1,0) [0|3] "" CLU,CGW
 SG_ NEW_SIGNAL_1 : 156|1@1+ (1,0) [0|1] "" XXX
 SG_ NEW_SIGNAL_2 : 164|4@1+ (1,0) [0|15] "" XXX
 SG_ NEW_SIGNAL_3 : 168|1@1+ (1,0) [0|1] "" XXX
 SG_ NEW_SIGNAL_4 : 169|1@1+ (1,0) [0|1] "" XXX
 SG_ NEW_SIGNAL_5 : 171|2@1+ (1,0) [0|3] "" XXX
 SG_ NEW_SIGNAL_6 : 173|1@1+ (1,0) [0|1] "" XXX
 SG_ NEW_SIGNAL_7 : 196|2@1+ (1,0) [0|3] "" XXX
 SG_ NEW_SIGNAL_8 : 204|1@1+ (1,0) [0|1] "" XXX
 SG_ NEW_SIGNAL_9 : 209|5@1+ (1,0) [0|31] "" XXX
 SG_ NEW_SIGNAL_10 : 214|1@1+ (1,0) [0|1] "" XXX
 SG_ NEW_SIGNAL_11 : 216|1@1+ (1,0) [0|1] "" XXX
 SG_ NEW_SIGNAL_12 : 218|2@1+ (1,0) [0|3] "" XXX

BO_ 507 CAM_0x1fb: 32 CAMERA
 SG_ CHECKSUM : 0|16@1+ (1,0) [0|65535] "" XXX
 SG_ COUNTER : 16|8@1+ (1,0) [0|255] "" XXX

BO_ 512 ADRV_0x200: 8 ADRV
 SG_ CHECKSUM : 0|16@1+ (1,0) [0|65535] "" XXX
 SG_ COUNTER : 16|8@1+ (1,0) [0|255] "" XXX
 SG_ SET_ME_E1 : 24|8@1+ (1,0) [0|255] "" XXX
 SG_ SET_ME_3A : 32|8@1+ (1,0) [0|255] "" XXX
 SG_ NEW_SIGNAL_1 : 40|3@1+ (1,0) [0|7] "" XXX
 SG_ NEW_SIGNAL_2 : 43|3@1+ (1,0) [0|7] "" XXX

BO_ 593 RADAR_0x251: 16 FRONT_RADAR
 SG_ CHECKSUM : 0|16@1+ (1,0) [0|65535] "" XXX
 SG_ COUNTER : 16|8@1+ (1,0) [0|255] "" XXX

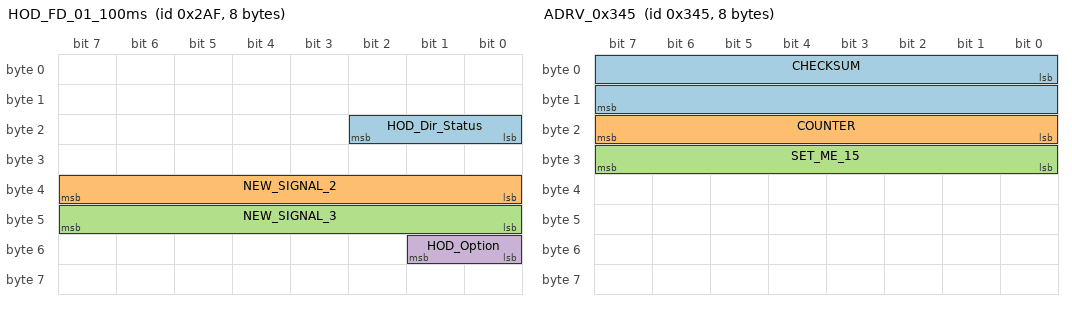
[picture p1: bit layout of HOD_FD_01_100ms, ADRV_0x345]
BO_ 687 HOD_FD_01_100ms: 8 XXX
 SG_ HOD_Dir_Status : 18|3@0+ (1,0) [0|7] "" XXX
 SG_ NEW_SIGNAL_2 : 32|8@1+ (1,0) [0|255] "" XXX
 SG_ NEW_SIGNAL_3 : 40|8@1+ (1,0) [0|255] "" XXX
 SG_ HOD_Option : 48|2@1+ (1,0) [0|255] "" XXX

BO_ 698 FR_CMR_04_40ms: 32 FR_CMR
 SG_ FR_CMR_Crc4Val : 0|16@1+ (1,0) [0|65535] "" Dummy
 SG_ FR_CMR_AlvCnt4Val : 16|8@1+ (1,0) [0|255] "" Dummy
 SG_ IFSref_FR_CMR_Sta : 24|2@1+ (1,0) [0|3] "" CGW
 SG_ IFSref_VehNumVal : 26|4@1+ (1,0) [0|15] "" CGW
 SG_ IFSref_ILLAmbtSta : 30|2@1+ (0.1,0) [0|0.3] "" CGW
 SG_ IFSref_VehLftAngl1Val : 32|9@1+ (0.1,-25) [-25|26.1] "Deg" CGW
 SG_ IFSref_VehRtAngl1Val : 41|9@1+ (0.1,-25) [-25|26.1] "Deg" CGW
 SG_ IFSref_VehLftAngl2Val : 50|9@1+ (0.1,-25) [-25|26.1] "Deg" CGW
 SG_ IFSref_VehDst1Val : 59|4@1+ (1,0) [0|15] "" CGW
 SG_ IFSref_VehRtAngl2Val : 64|9@1+ (0.1,-25) [-25|26.1] "Deg" CGW
 SG_ IFSref_VehLftAngl3Val : 73|9@1+ (0.1,-25) [-25|26.1] "Deg" CGW
 SG_ IFSref_VehRtAngl3Val : 82|9@1+ (0.1,-25) [-25|26.1] "Deg" CGW
 SG_ IFSref_VehLftAngl4Val : 91|9@1+ (0.1,-25) [-25|26.1] "Deg" CGW
 SG_ IFSref_VehRtAngl4Val : 100|9@1+ (0.1,-25) [-25|26.1] "Deg" CGW
 SG_ IFSref_VehLftAngl5Val : 109|9@1+ (0.1,-25) [-25|26.1] "Deg" CGW
 SG_ IFSref_VehRtAngl5Val : 118|9@1+ (0.1,-25) [-25|26.1] "Deg" CGW
 SG_ IFSref_VehLftAngl6Val : 128|9@1+ (0.1,-25) [-25|26.1] "Deg" CGW
 SG_ IFSref_VehRtAngl6Val : 137|9@1+ (0.1,-25) [-25|26.1] "Deg" CGW
 SG_ IFSref_VehLftAngl7Val : 146|9@1+ (0.1,-25) [-25|26.1] "Deg" CGW
 SG_ IFSref_VehRtAngl7Val : 155|9@1+ (0.1,-25) [-25|26.1] "Deg" CGW
 SG_ IFSref_VehLftAngl8Val : 164|9@1+ (0.1,-25) [-25|26.1] "Deg" CGW
 SG_ IFSref_VehRtAngl8Val : 173|9@1+ (0.1,-25) [-25|26.1] "Deg" CGW
 SG_ IFSref_VehLftAngl9Val : 182|9@1+ (0.1,-25) [-25|26.1] "Deg" CGW
 SG_ IFSref_VehRtAngl9Val : 192|9@1+ (0.1,-25) [-25|26.1] "Deg" CGW
 SG_ IFSref_VehLftAngl10Val : 201|9@1+ (0.1,-25) [-25|26.1] "Deg" CGW
 SG_ IFSref_VehRtAngl10Val : 210|9@1+ (0.1,-25) [-25|26.1] "Deg" CGW
 SG_ IFSref_VehDst2Val : 219|4@1+ (1,0) [0|15] "" CGW
 SG_ IFSref_VehDst3Val : 223|4@1+ (1,0) [0|15] "" CGW
 SG_ IFSref_VehDst4Val : 227|4@1+ (1,0) [0|15] "" CGW
 SG_ IFSref_VehDst5Val : 231|4@1+ (1,0) [0|15] "" CGW
 SG_ IFSref_VehDst6Val : 235|4@1+ (1,0) [0|15] "" CGW
 SG_ IFSref_VehDst7Val : 239|4@1+ (1,0) [0|15] "" CGW
 SG_ IFSref_VehDst8Val : 243|4@1+ (1,0) [0|15] "" CGW
 SG_ IFSref_VehDst9Val : 247|4@1+ (1,0) [0|15] "" CGW
 SG_ IFSref_VehDst10Val : 251|4@1+ (1,0) [0|15] "" CGW

BO_ 736 MANUAL_SPEED_LIMIT_ASSIST: 32 XXX
 SG_ CHECKSUM : 0|16@1+ (1,0) [0|65535] "" XXX
 SG_ COUNTER : 16|8@1+ (1,0) [0|255] "" XXX
 SG_ MSLA_STATUS : 26|2@1+ (1,0) [0|3] "" XXX
 SG_ MSLA_ENABLED : 38|1@1+ (1,0) [0|1] "" XXX
 SG_ MAX_SPEED : 55|8@0+ (1,0) [0|255] "" XXX
 SG_ MAX_SPEED_COPY : 144|8@1+ (1,0) [0|255] "" XXX

BO_ 837 ADRV_0x345: 8 ADRV
 SG_ CHECKSUM : 0|16@1+ (1,0) [0|65535] "" XXX
 SG_ COUNTER : 16|8@1+ (1,0) [0|255] "" XXX
 SG_ SET_ME_15 : 24|8@1+ (1,0) [0|255] "" XXX

BO_ 866 CAM_0x362: 32 CAMERA
 SG_ CHECKSUM : 0|16@1+ (1,0) [0|65535] "" XXX
 SG_ COUNTER : 16|8@1+ (1,0) [0|255] "" XXX
 SG_ BYTE3 : 24|8@1+ (1,0) [0|255] "" XXX
 SG_ BYTE4 : 32|8@1+ (1,0) [0|255] "" XXX
 SG_ BYTE5 : 40|8@1+ (1,0) [0|255] "" XXX
 SG_ BYTE6 : 48|8@1+ (1,0) [0|255] "" XXX
 SG_ LEFT_LANE_LINE : 56|2@1+ (1,0) [0|3] "" XXX
 SG_ SET_ME_0 : 58|2@1+ (1,0) [0|3] "" XXX
 SG_ RIGHT_LANE_LINE : 60|2@1+ (1,0) [0|3] "" XXX
 SG_ SET_ME_0_2 : 62|2@1+ (1,0) [0|3] "" XXX
 SG_ BYTE8 : 64|8@1+ (1,0) [0|255] "" XXX
 SG_ BYTE9 : 72|8@1+ (1,0) [0|255] "" XXX
 SG_ BYTE10 : 80|8@1+ (1,0) [0|255] "" XXX
 SG_ BYTE11 : 88|8@1+ (1,0) [0|255] "" XXX
 SG_ BYTE12 : 96|8@1+ (1,0) [0|255] "" XXX
 SG_ BYTE13 : 104|8@1+ (1,0) [0|255] "" XXX
 SG_ BYTE14 : 112|8@1+ (1,0) [0|255] "" XXX
 SG_ BYTE15 : 120|8@1+ (1,0) [0|255] "" XXX
 SG_ BYTE16 : 128|8@1+ (1,0) [0|255] "" XXX
 SG_ BYTE17 : 136|8@1+ (1,0) [0|255] "" XXX
 SG_ BYTE18 : 144|8@1+ (1,0) [0|255] "" XXX
 SG_ BYTE19 : 152|8@1+ (1,0) [0|255] "" XXX
 SG_ BYTE20 : 160|8@1+ (1,0) [0|255] "" XXX
 SG_ BYTE21 : 168|8@1+ (1,0) [0|255] "" XXX
 SG_ BYTE22 : 176|8@1+ (1,0) [0|255] "" XXX
 SG_ BYTE23 : 184|8@1+ (1,0) [0|255] "" XXX
 SG_ BYTE24 : 192|8@1+ (1,0) [0|255] "" XXX
 SG_ BYTE25 : 200|8@1+ (1,0) [0|255] "" XXX
 SG_ BYTE26 : 208|8@1+ (1,0) [0|255] "" XXX
 SG_ BYTE27 : 216|8@1+ (1,0) [0|255] "" XXX
 SG_ BYTE28 : 224|8@1+ (1,0) [0|255] "" XXX
 SG_ BYTE29 : 232|8@1+ (1,0) [0|255] "" XXX
 SG_ BYTE30 : 240|8@1+ (1,0) [0|255] "" XXX
 SG_ BYTE31 : 248|8@1+ (1,0) [0|255] "" XXX

BO_ 874 BLINDSPOTS_FRONT_CORNER_2: 16 XXX
 SG_ CHECKSUM : 0|16@1+ (1,0) [0|65535] "" XXX
 SG_ COUNTER : 16|8@1+ (1,0) [0|255] "" XXX

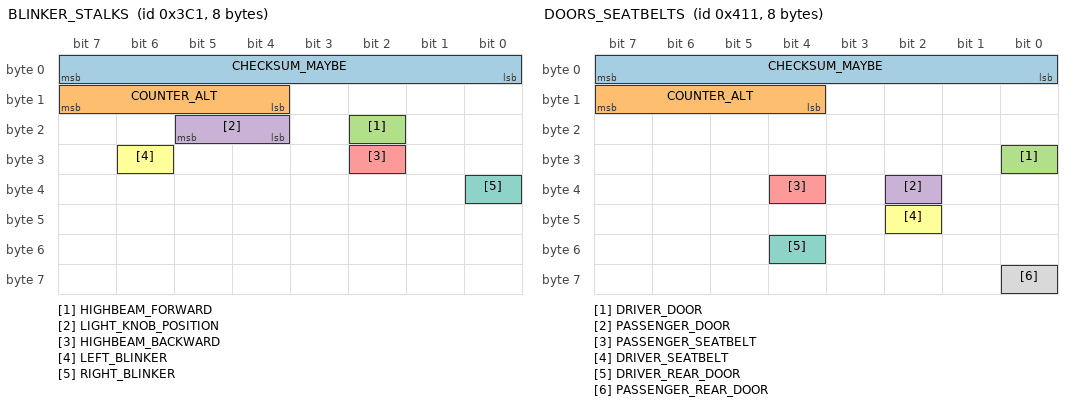
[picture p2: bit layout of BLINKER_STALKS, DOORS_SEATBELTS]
BO_ 961 BLINKER_STALKS: 8 XXX
 SG_ CHECKSUM_MAYBE : 7|8@0+ (1,0) [0|255] "" XXX
 SG_ COUNTER_ALT : 15|4@0+ (1,0) [0|15] "" XXX
 SG_ HIGHBEAM_FORWARD : 18|1@0+ (1,0) [0|1] "" XXX
 SG_ LIGHT_KNOB_POSITION : 21|2@0+ (1,0) [0|3] "" XXX
 SG_ HIGHBEAM_BACKWARD : 26|1@0+ (1,0) [0|1] "" XXX
 SG_ LEFT_BLINKER : 30|1@0+ (1,0) [0|1] "" XXX
 SG_ RIGHT_BLINKER : 32|1@0+ (1,0) [0|1] "" XXX

BO_ 1041 DOORS_SEATBELTS: 8 XXX
 SG_ CHECKSUM_MAYBE : 7|8@0+ (1,0) [0|65535] "" XXX
 SG_ COUNTER_ALT : 15|4@0+ (1,0) [0|15] "" XXX
 SG_ DRIVER_DOOR : 24|1@1+ (1,0) [0|1] "" XXX
 SG_ PASSENGER_DOOR : 34|1@0+ (1,0) [0|1] "" XXX
 SG_ PASSENGER_SEATBELT : 36|1@0+ (1,0) [0|1] "" XXX
 SG_ DRIVER_SEATBELT : 42|1@0+ (1,0) [0|1] "" XXX
 SG_ DRIVER_REAR_DOOR : 52|1@0+ (1,0) [0|1] "" XXX
 SG_ PASSENGER_REAR_DOOR : 56|1@0+ (1,0) [0|1] "" XXX

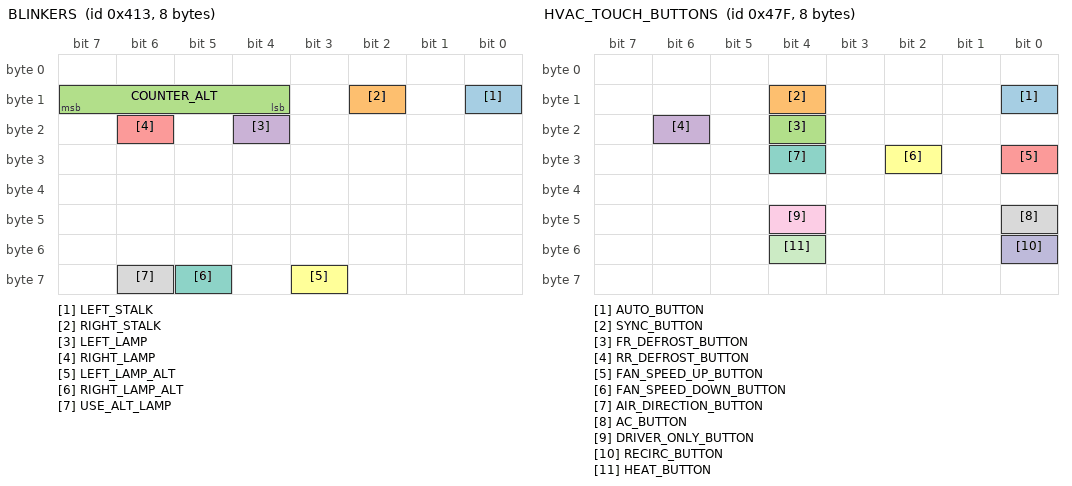
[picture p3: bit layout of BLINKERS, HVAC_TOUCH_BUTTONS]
BO_ 1043 BLINKERS: 8 XXX
 SG_ LEFT_STALK : 8|1@0+ (1,0) [0|1] "" XXX
 SG_ RIGHT_STALK : 10|1@0+ (1,0) [0|1] "" XXX
 SG_ COUNTER_ALT : 15|4@0+ (1,0) [0|15] "" XXX
 SG_ LEFT_LAMP : 20|1@0+ (1,0) [0|1] "" XXX
 SG_ RIGHT_LAMP : 22|1@0+ (1,0) [0|1] "" XXX
 SG_ LEFT_LAMP_ALT : 59|1@0+ (1,0) [0|1] "" XXX
 SG_ RIGHT_LAMP_ALT : 61|1@0+ (1,0) [0|1] "" XXX
 SG_ USE_ALT_LAMP : 62|1@0+ (1,0) [0|1] "" XXX

BO_ 1144 DRIVE_MODE: 8 XXX
 SG_ DRIVE_MODE : 0|16@1+ (1,-61611) [0|61611] "" XXX
 SG_ DRIVE_MODE2 : 28|3@1+ (1,0) [1|3] "" XXX

BO_ 1151 HVAC_TOUCH_BUTTONS: 8 XXX
 SG_ AUTO_BUTTON : 8|1@0+ (1,0) [0|1] "" XXX
 SG_ SYNC_BUTTON : 12|1@0+ (1,0) [0|1] "" XXX
 SG_ FR_DEFROST_BUTTON : 20|1@0+ (1,0) [0|1] "" XXX
 SG_ RR_DEFROST_BUTTON : 22|1@0+ (1,0) [0|1] "" XXX
 SG_ FAN_SPEED_UP_BUTTON : 24|1@0+ (1,0) [0|1] "" XXX
 SG_ FAN_SPEED_DOWN_BUTTON : 26|1@0+ (1,0) [0|1] "" XXX
 SG_ AIR_DIRECTION_BUTTON : 28|1@0+ (1,0) [0|1] "" XXX
 SG_ AC_BUTTON : 40|1@0+ (1,0) [0|1] "" XXX
 SG_ DRIVER_ONLY_BUTTON : 44|1@0+ (1,0) [0|1] "" XXX
 SG_ RECIRC_BUTTON : 48|1@0+ (1,0) [0|1] "" XXX
 SG_ HEAT_BUTTON : 52|1@0+ (1,0) [0|1] "" XXX

BO_ 1240 CLUSTER_INFO: 8 XXX
 SG_ DISTANCE_UNIT : 0|1@1+ (1,0) [0|1] "" XXX

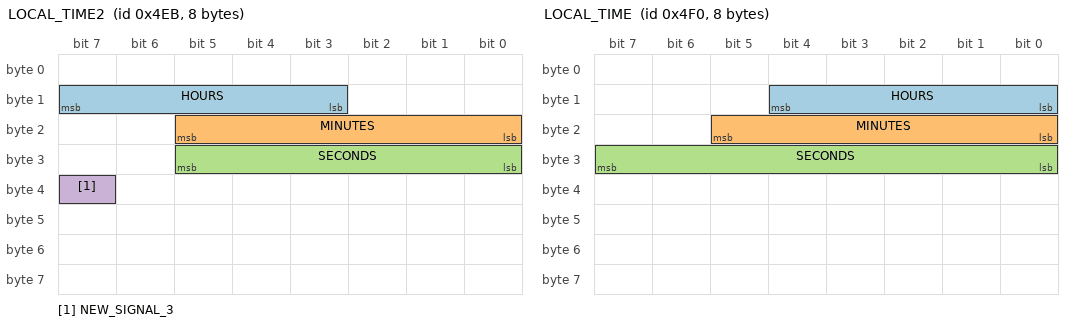
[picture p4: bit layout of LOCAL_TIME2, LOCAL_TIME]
BO_ 1259 LOCAL_TIME2: 8 XXX
 SG_ HOURS : 15|5@0+ (1,0) [0|31] "" XXX
 SG_ MINUTES : 21|6@0+ (1,0) [0|63] "" XXX
 SG_ SECONDS : 24|6@1+ (1,0) [0|63] "" XXX
 SG_ NEW_SIGNAL_3 : 39|1@0+ (1,0) [0|1] "" XXX

BO_ 1264 LOCAL_TIME: 8 XXX
 SG_ HOURS : 12|5@0+ (1,0) [0|31] "" XXX
 SG_ MINUTES : 21|6@0+ (1,0) [0|63] "" XXX
 SG_ SECONDS : 31|8@0+ (1,0) [0|59] "" XXX

BO_ 908 CAM_0x38c: 32 FR_CMR
 SG_ CHECKSUM : 0|16@1+ (1,0) [0|65535] "" XXX
 SG_ COUNTER : 16|8@1+ (1,0) [0|255] "" XXX
 SG_ NEW_SIGNAL_1 : 24|8@1+ (1,0) [0|255] "" XXX
 SG_ NEW_SIGNAL_2 : 32|8@1+ (1,0) [0|255] "" XXX

BO_ 560 CAM_0x230: 16 FR_CMR
 SG_ CHECKSUM : 0|16@1+ (1,0) [0|65535] "" XXX
 SG_ COUNTER : 16|8@1+ (1,0) [0|255] "" XXX
 SG_ NEW_SIGNAL_1 : 24|5@1+ (1,0) [0|31] "" XXX
 SG_ NEW_SIGNAL_2 : 32|3@1+ (1,0) [0|7] "" XXX
 SG_ NEW_SIGNAL_3 : 41|1@1+ (1,0) [0|1] "" XXX
 SG_ NEW_SIGNAL_4 : 45|1@1+ (1,0) [0|1] "" XXX
 SG_ NEW_SIGNAL_5 : 48|4@1+ (1,0) [0|15] "" XXX
 SG_ NEW_SIGNAL_6 : 55|1@1+ (1,0) [0|1] "" XXX
 SG_ NEW_SIGNAL_7 : 56|1@1+ (1,0) [0|1] "" XXX
 SG_ NEW_SIGNAL_8 : 112|2@1+ (1,0) [0|3] "" XXX
 SG_ NEW_SIGNAL_9 : 123|1@1+ (1,0) [0|1] "" XXX

BO_ 565 CAM_0x235: 32 FR_CMR
 SG_ CHECKSUM : 0|16@1+ (1,0) [0|65535] "" XXX
 SG_ COUNTER : 16|8@1+ (1,0) [0|255] "" XXX
 SG_ NEW_SIGNAL_1 : 24|5@1+ (1,0) [0|31] "" XXX
 SG_ NEW_SIGNAL_2 : 29|1@1+ (1,0) [0|1] "" XXX
 SG_ NEW_SIGNAL_3 : 32|19@1+ (1,0) [0|524287] "" XXX
 SG_ NEW_SIGNAL_4 : 52|2@1+ (1,0) [0|3] "" XXX
 SG_ NEW_SIGNAL_5 : 54|1@1+ (1,0) [0|1] "" XXX
 SG_ NEW_SIGNAL_6 : 56|6@1+ (1,0) [0|63] "" XXX
 SG_ NEW_SIGNAL_7 : 62|13@1+ (1,0) [0|8191] "" XXX
 SG_ NEW_SIGNAL_8 : 75|1@1+ (1,0) [0|1] "" XXX
 SG_ NEW_SIGNAL_9 : 76|1@1+ (1,0) [0|1] "" XXX
 SG_ NEW_SIGNAL_10 : 78|12@1+ (1,0) [0|4095] "" XXX
 SG_ NEW_SIGNAL_11 : 91|12@1+ (1,0) [0|4095] "" XXX
 SG_ NEW_SIGNAL_12 : 104|9@1+ (1,0) [0|511] "" XXX
 SG_ NEW_SIGNAL_13 : 113|1@1+ (1,0) [0|1] "" XXX
 SG_ NEW_SIGNAL_14 : 115|9@1+ (1,0) [0|511] "" XXX
 SG_ NEW_SIGNAL_15 : 125|12@1+ (1,0) [0|4095] "" XXX
 SG_ NEW_SIGNAL_16 : 138|12@1+ (1,0) [0|4095] "" XXX
 SG_ NEW_SIGNAL_17 : 151|8@1+ (1,0) [0|255] "" XXX
 SG_ NEW_SIGNAL_18 : 159|9@1+ (1,0) [0|511] "" XXX
 SG_ NEW_SIGNAL_19 : 168|8@1+ (1,0) [0|255] "" XXX
 SG_ NEW_SIGNAL_20 : 176|14@1+ (1,0) [0|16383] "" XXX

BO_ 566 CAM_0x236: 32 FR_CMR
 SG_ CHECKSUM : 0|16@1+ (1,0) [0|65535] "" XXX
 SG_ COUNTER : 16|8@1+ (1,0) [0|255] "" XXX
 SG_ NEW_SIGNAL_1 : 24|5@1+ (1,0) [0|31] "" XXX
 SG_ NEW_SIGNAL_2 : 29|1@1+ (1,0) [0|1] "" XXX
 SG_ NEW_SIGNAL_3 : 32|19@1+ (1,0) [0|524287] "" XXX
 SG_ NEW_SIGNAL_4 : 52|2@1+ (1,0) [0|3] "" XXX
 SG_ NEW_SIGNAL_5 : 54|1@1+ (1,0) [0|1] "" XXX
 SG_ NEW_SIGNAL_6 : 56|6@1+ (1,0) [0|63] "" XXX
 SG_ NEW_SIGNAL_7 : 62|13@1+ (1,0) [0|8191] "" XXX
 SG_ NEW_SIGNAL_8 : 75|1@1+ (1,0) [0|1] "" XXX
 SG_ NEW_SIGNAL_9 : 76|1@1+ (1,0) [0|1] "" XXX
 SG_ NEW_SIGNAL_10 : 78|12@1+ (1,0) [0|4095] "" XXX
 SG_ NEW_SIGNAL_11 : 91|12@1+ (1,0) [0|4095] "" XXX
 SG_ NEW_SIGNAL_12 : 104|9@1+ (1,0) [0|511] "" XXX
 SG_ NEW_SIGNAL_13 : 113|1@1+ (1,0) [0|1] "" XXX
 SG_ NEW_SIGNAL_14 : 115|9@1+ (1,0) [0|511] "" XXX
 SG_ NEW_SIGNAL_15 : 125|12@1+ (1,0) [0|4095] "" XXX
 SG_ NEW_SIGNAL_16 : 138|12@1+ (1,0) [0|4095] "" XXX
 SG_ NEW_SIGNAL_17 : 151|8@1+ (1,0) [0|255] "" XXX
 SG_ NEW_SIGNAL_18 : 159|9@1+ (1,0) [0|511] "" XXX
 SG_ NEW_SIGNAL_19 : 168|8@1+ (1,0) [0|255] "" XXX
 SG_ NEW_SIGNAL_20 : 176|14@1+ (1,0) [0|16383] "" XXX

BO_ 567 CAM_0x237: 32 FR_CMR
 SG_ CHECKSUM : 0|16@1+ (1,0) [0|65535] "" XXX
 SG_ COUNTER : 16|8@1+ (1,0) [0|255] "" XXX
 SG_ NEW_SIGNAL_1 : 24|5@1+ (1,0) [0|31] "" XXX
 SG_ NEW_SIGNAL_2 : 29|1@1+ (1,0) [0|1] "" XXX
 SG_ NEW_SIGNAL_3 : 32|19@1+ (1,0) [0|524287] "" XXX
 SG_ NEW_SIGNAL_4 : 52|2@1+ (1,0) [0|3] "" XXX
 SG_ NEW_SIGNAL_5 : 54|1@1+ (1,0) [0|1] "" XXX
 SG_ NEW_SIGNAL_6 : 56|6@1+ (1,0) [0|63] "" XXX
 SG_ NEW_SIGNAL_7 : 62|13@1+ (1,0) [0|8191] "" XXX
 SG_ NEW_SIGNAL_8 : 75|1@1+ (1,0) [0|1] "" XXX
 SG_ NEW_SIGNAL_9 : 76|1@1+ (1,0) [0|1] "" XXX
 SG_ NEW_SIGNAL_10 : 78|12@1+ (1,0) [0|4095] "" XXX
 SG_ NEW_SIGNAL_11 : 91|12@1+ (1,0) [0|4095] "" XXX
 SG_ NEW_SIGNAL_12 : 104|9@1+ (1,0) [0|511] "" XXX
 SG_ NEW_SIGNAL_13 : 113|1@1+ (1,0) [0|1] "" XXX
 SG_ NEW_SIGNAL_14 : 115|9@1+ (1,0) [0|511] "" XXX
 SG_ NEW_SIGNAL_15 : 125|12@1+ (1,0) [0|4095] "" XXX
 SG_ NEW_SIGNAL_16 : 138|12@1+ (1,0) [0|4095] "" XXX
 SG_ NEW_SIGNAL_17 : 151|8@1+ (1,0) [0|255] "" XXX
 SG_ NEW_SIGNAL_18 : 159|9@1+ (1,0) [0|511] "" XXX
 SG_ NEW_SIGNAL_19 : 168|8@1+ (1,0) [0|255] "" XXX
 SG_ NEW_SIGNAL_20 : 176|14@1+ (1,0) [0|16383] "" XXX

BO_ 568 CAM_0x238: 32 FR_CMR
 SG_ CHECKSUM : 0|16@1+ (1,0) [0|65535] "" XXX
 SG_ COUNTER : 16|8@1+ (1,0) [0|255] "" XXX
 SG_ NEW_SIGNAL_1 : 24|5@1+ (1,0) [0|31] "" XXX
 SG_ NEW_SIGNAL_2 : 29|1@1+ (1,0) [0|1] "" XXX
 SG_ NEW_SIGNAL_3 : 32|19@1+ (1,0) [0|524287] "" XXX
 SG_ NEW_SIGNAL_4 : 52|2@1+ (1,0) [0|3] "" XXX
 SG_ NEW_SIGNAL_5 : 54|1@1+ (1,0) [0|1] "" XXX
 SG_ NEW_SIGNAL_6 : 56|6@1+ (1,0) [0|63] "" XXX
 SG_ NEW_SIGNAL_7 : 62|13@1+ (1,0) [0|8191] "" XXX
 SG_ NEW_SIGNAL_8 : 75|1@1+ (1,0) [0|1] "" XXX
 SG_ NEW_SIGNAL_9 : 76|1@1+ (1,0) [0|1] "" XXX
 SG_ NEW_SIGNAL_10 : 78|12@1+ (1,0) [0|4095] "" XXX
 SG_ NEW_SIGNAL_11 : 91|12@1+ (1,0) [0|4095] "" XXX
 SG_ NEW_SIGNAL_12 : 104|9@1+ (1,0) [0|511] "" XXX
 SG_ NEW_SIGNAL_13 : 113|1@1+ (1,0) [0|1] "" XXX
 SG_ NEW_SIGNAL_14 : 115|9@1+ (1,0) [0|511] "" XXX
 SG_ NEW_SIGNAL_15 : 125|12@1+ (1,0) [0|4095] "" XXX
 SG_ NEW_SIGNAL_16 : 138|12@1+ (1,0) [0|4095] "" XXX
 SG_ NEW_SIGNAL_17 : 151|8@1+ (1,0) [0|255] "" XXX
 SG_ NEW_SIGNAL_18 : 159|9@1+ (1,0) [0|511] "" XXX
 SG_ NEW_SIGNAL_19 : 168|8@1+ (1,0) [0|255] "" XXX
 SG_ NEW_SIGNAL_20 : 176|14@1+ (1,0) [0|16383] "" XXX

BO_ 569 CAM_0x239: 32 FR_CMR
 SG_ CHECKSUM : 0|16@1+ (1,0) [0|65535] "" XXX
 SG_ COUNTER : 16|8@1+ (1,0) [0|255] "" XXX
 SG_ NEW_SIGNAL_1 : 24|5@1+ (1,0) [0|31] "" XXX
 SG_ NEW_SIGNAL_2 : 29|1@1+ (1,0) [0|1] "" XXX
 SG_ NEW_SIGNAL_3 : 32|19@1+ (1,0) [0|524287] "" XXX
 SG_ NEW_SIGNAL_4 : 52|2@1+ (1,0) [0|3] "" XXX
 SG_ NEW_SIGNAL_5 : 54|1@1+ (1,0) [0|1] "" XXX
 SG_ NEW_SIGNAL_6 : 56|6@1+ (1,0) [0|63] "" XXX
 SG_ NEW_SIGNAL_7 : 62|13@1+ (1,0) [0|8191] "" XXX
 SG_ NEW_SIGNAL_8 : 75|1@1+ (1,0) [0|1] "" XXX
 SG_ NEW_SIGNAL_9 : 76|1@1+ (1,0) [0|1] "" XXX
 SG_ NEW_SIGNAL_10 : 78|12@1+ (1,0) [0|4095] "" XXX
 SG_ NEW_SIGNAL_11 : 91|12@1+ (1,0) [0|4095] "" XXX
 SG_ NEW_SIGNAL_12 : 104|9@1+ (1,0) [0|511] "" XXX
 SG_ NEW_SIGNAL_13 : 113|1@1+ (1,0) [0|1] "" XXX
 SG_ NEW_SIGNAL_14 : 115|9@1+ (1,0) [0|511] "" XXX
 SG_ NEW_SIGNAL_15 : 125|12@1+ (1,0) [0|4095] "" XXX
 SG_ NEW_SIGNAL_16 : 138|12@1+ (1,0) [0|4095] "" XXX
 SG_ NEW_SIGNAL_17 : 151|8@1+ (1,0) [0|255] "" XXX
 SG_ NEW_SIGNAL_18 : 159|9@1+ (1,0) [0|511] "" XXX
 SG_ NEW_SIGNAL_19 : 168|8@1+ (1,0) [0|255] "" XXX
 SG_ NEW_SIGNAL_20 : 176|14@1+ (1,0) [0|16383] "" XXX

BO_ 570 CAM_0x23a: 32 FR_CMR
 SG_ CHECKSUM : 0|16@1+ (1,0) [0|65535] "" XXX
 SG_ COUNTER : 16|8@1+ (1,0) [0|255] "" XXX
 SG_ NEW_SIGNAL_1 : 24|5@1+ (1,0) [0|31] "" XXX
 SG_ NEW_SIGNAL_2 : 29|1@1+ (1,0) [0|1] "" XXX
 SG_ NEW_SIGNAL_3 : 32|19@1+ (1,0) [0|524287] "" XXX
 SG_ NEW_SIGNAL_4 : 52|2@1+ (1,0) [0|3] "" XXX
 SG_ NEW_SIGNAL_5 : 54|1@1+ (1,0) [0|1] "" XXX
 SG_ NEW_SIGNAL_6 : 56|6@1+ (1,0) [0|63] "" XXX
 SG_ NEW_SIGNAL_7 : 62|13@1+ (1,0) [0|8191] "" XXX
 SG_ NEW_SIGNAL_8 : 75|1@1+ (1,0) [0|1] "" XXX
 SG_ NEW_SIGNAL_9 : 76|1@1+ (1,0) [0|1] "" XXX
 SG_ NEW_SIGNAL_10 : 78|12@1+ (1,0) [0|4095] "" XXX
 SG_ NEW_SIGNAL_11 : 91|12@1+ (1,0) [0|4095] "" XXX
 SG_ NEW_SIGNAL_12 : 104|9@1+ (1,0) [0|511] "" XXX
 SG_ NEW_SIGNAL_13 : 113|1@1+ (1,0) [0|1] "" XXX
 SG_ NEW_SIGNAL_14 : 115|9@1+ (1,0) [0|511] "" XXX
 SG_ NEW_SIGNAL_15 : 125|12@1+ (1,0) [0|4095] "" XXX
 SG_ NEW_SIGNAL_16 : 138|12@1+ (1,0) [0|4095] "" XXX
 SG_ NEW_SIGNAL_17 : 151|8@1+ (1,0) [0|255] "" XXX
 SG_ NEW_SIGNAL_18 : 159|9@1+ (1,0) [0|511] "" XXX
 SG_ NEW_SIGNAL_19 : 168|8@1+ (1,0) [0|255] "" XXX
 SG_ NEW_SIGNAL_20 : 176|14@1+ (1,0) [0|16383] "" XXX

BO_ 571 CAM_0x23b: 32 FR_CMR
 SG_ CHECKSUM : 0|16@1+ (1,0) [0|65535] "" XXX
 SG_ COUNTER : 16|8@1+ (1,0) [0|255] "" XXX
 SG_ NEW_SIGNAL_1 : 24|5@1+ (1,0) [0|31] "" XXX
 SG_ NEW_SIGNAL_2 : 29|1@1+ (1,0) [0|1] "" XXX
 SG_ NEW_SIGNAL_3 : 32|19@1+ (1,0) [0|524287] "" XXX
 SG_ NEW_SIGNAL_4 : 52|2@1+ (1,0) [0|3] "" XXX
 SG_ NEW_SIGNAL_5 : 54|1@1+ (1,0) [0|1] "" XXX
 SG_ NEW_SIGNAL_6 : 56|6@1+ (1,0) [0|63] "" XXX
 SG_ NEW_SIGNAL_7 : 62|13@1+ (1,0) [0|8191] "" XXX
 SG_ NEW_SIGNAL_8 : 75|1@1+ (1,0) [0|1] "" XXX
 SG_ NEW_SIGNAL_9 : 76|1@1+ (1,0) [0|1] "" XXX
 SG_ NEW_SIGNAL_10 : 78|12@1+ (1,0) [0|4095] "" XXX
 SG_ NEW_SIGNAL_11 : 91|12@1+ (1,0) [0|4095] "" XXX
 SG_ NEW_SIGNAL_12 : 104|9@1+ (1,0) [0|511] "" XXX
 SG_ NEW_SIGNAL_13 : 113|1@1+ (1,0) [0|1] "" XXX
 SG_ NEW_SIGNAL_14 : 115|9@1+ (1,0) [0|511] "" XXX
 SG_ NEW_SIGNAL_15 : 125|12@1+ (1,0) [0|4095] "" XXX
 SG_ NEW_SIGNAL_16 : 138|12@1+ (1,0) [0|4095] "" XXX
 SG_ NEW_SIGNAL_17 : 151|8@1+ (1,0) [0|255] "" XXX
 SG_ NEW_SIGNAL_18 : 159|9@1+ (1,0) [0|511] "" XXX
 SG_ NEW_SIGNAL_19 : 168|8@1+ (1,0) [0|255] "" XXX
 SG_ NEW_SIGNAL_20 : 176|14@1+ (1,0) [0|16383] "" XXX

BO_ 572 CAM_0x23c: 32 FR_CMR
 SG_ CHECKSUM : 0|16@1+ (1,0) [0|65535] "" XXX
 SG_ COUNTER : 16|8@1+ (1,0) [0|255] "" XXX
 SG_ NEW_SIGNAL_1 : 24|5@1+ (1,0) [0|31] "" XXX
 SG_ NEW_SIGNAL_2 : 29|1@1+ (1,0) [0|1] "" XXX
 SG_ NEW_SIGNAL_3 : 32|19@1+ (1,0) [0|524287] "" XXX
 SG_ NEW_SIGNAL_4 : 52|2@1+ (1,0) [0|3] "" XXX
 SG_ NEW_SIGNAL_5 : 54|1@1+ (1,0) [0|1] "" XXX
 SG_ NEW_SIGNAL_6 : 56|6@1+ (1,0) [0|63] "" XXX
 SG_ NEW_SIGNAL_7 : 62|13@1+ (1,0) [0|8191] "" XXX
 SG_ NEW_SIGNAL_8 : 75|1@1+ (1,0) [0|1] "" XXX
 SG_ NEW_SIGNAL_9 : 76|1@1+ (1,0) [0|1] "" XXX
 SG_ NEW_SIGNAL_10 : 78|12@1+ (1,0) [0|4095] "" XXX
 SG_ NEW_SIGNAL_11 : 91|12@1+ (1,0) [0|4095] "" XXX
 SG_ NEW_SIGNAL_12 : 104|9@1+ (1,0) [0|511] "" XXX
 SG_ NEW_SIGNAL_13 : 113|1@1+ (1,0) [0|1] "" XXX
 SG_ NEW_SIGNAL_14 : 115|9@1+ (1,0) [0|511] "" XXX
 SG_ NEW_SIGNAL_15 : 125|12@1+ (1,0) [0|4095] "" XXX
 SG_ NEW_SIGNAL_16 : 138|12@1+ (1,0) [0|4095] "" XXX
 SG_ NEW_SIGNAL_17 : 151|8@1+ (1,0) [0|255] "" XXX
 SG_ NEW_SIGNAL_18 : 159|9@1+ (1,0) [0|511] "" XXX
 SG_ NEW_SIGNAL_19 : 168|8@1+ (1,0) [0|255] "" XXX
 SG_ NEW_SIGNAL_20 : 176|14@1+ (1,0) [0|16383] "" XXX

BO_ 573 CAM_0x23d: 32 FR_CMR
 SG_ CHECKSUM : 0|16@1+ (1,0) [0|65535] "" XXX
 SG_ COUNTER : 16|8@1+ (1,0) [0|255] "" XXX
 SG_ NEW_SIGNAL_1 : 24|5@1+ (1,0) [0|31] "" XXX
 SG_ NEW_SIGNAL_2 : 29|1@1+ (1,0) [0|1] "" XXX
 SG_ NEW_SIGNAL_3 : 32|19@1+ (1,0) [0|524287] "" XXX
 SG_ NEW_SIGNAL_4 : 52|2@1+ (1,0) [0|3] "" XXX
 SG_ NEW_SIGNAL_5 : 54|1@1+ (1,0) [0|1] "" XXX
 SG_ NEW_SIGNAL_6 : 56|6@1+ (1,0) [0|63] "" XXX
 SG_ NEW_SIGNAL_7 : 62|13@1+ (1,0) [0|8191] "" XXX
 SG_ NEW_SIGNAL_8 : 75|1@1+ (1,0) [0|1] "" XXX
 SG_ NEW_SIGNAL_9 : 76|1@1+ (1,0) [0|1] "" XXX
 SG_ NEW_SIGNAL_10 : 78|12@1+ (1,0) [0|4095] "" XXX
 SG_ NEW_SIGNAL_11 : 91|12@1+ (1,0) [0|4095] "" XXX
 SG_ NEW_SIGNAL_12 : 104|9@1+ (1,0) [0|511] "" XXX
 SG_ NEW_SIGNAL_13 : 113|1@1+ (1,0) [0|1] "" XXX
 SG_ NEW_SIGNAL_14 : 115|9@1+ (1,0) [0|511] "" XXX
 SG_ NEW_SIGNAL_15 : 125|12@1+ (1,0) [0|4095] "" XXX
 SG_ NEW_SIGNAL_16 : 138|12@1+ (1,0) [0|4095] "" XXX
 SG_ NEW_SIGNAL_17 : 151|8@1+ (1,0) [0|255] "" XXX
 SG_ NEW_SIGNAL_18 : 159|9@1+ (1,0) [0|511] "" XXX
 SG_ NEW_SIGNAL_19 : 168|8@1+ (1,0) [0|255] "" XXX
 SG_ NEW_SIGNAL_20 : 176|14@1+ (1,0) [0|16383] "" XXX

BO_ 574 CAM_0x23e: 32 FR_CMR
 SG_ CHECKSUM : 0|16@1+ (1,0) [0|65535] "" XXX
 SG_ COUNTER : 16|8@1+ (1,0) [0|255] "" XXX
 SG_ NEW_SIGNAL_1 : 24|5@1+ (1,0) [0|31] "" XXX
 SG_ NEW_SIGNAL_2 : 29|1@1+ (1,0) [0|1] "" XXX
 SG_ NEW_SIGNAL_3 : 32|19@1+ (1,0) [0|524287] "" XXX
 SG_ NEW_SIGNAL_4 : 52|2@1+ (1,0) [0|3] "" XXX
 SG_ NEW_SIGNAL_5 : 54|1@1+ (1,0) [0|1] "" XXX
 SG_ NEW_SIGNAL_6 : 56|6@1+ (1,0) [0|63] "" XXX
 SG_ NEW_SIGNAL_7 : 62|13@1+ (1,0) [0|8191] "" XXX
 SG_ NEW_SIGNAL_8 : 75|1@1+ (1,0) [0|1] "" XXX
 SG_ NEW_SIGNAL_9 : 76|1@1+ (1,0) [0|1] "" XXX
 SG_ NEW_SIGNAL_10 : 78|12@1+ (1,0) [0|4095] "" XXX
 SG_ NEW_SIGNAL_11 : 91|12@1+ (1,0) [0|4095] "" XXX
 SG_ NEW_SIGNAL_12 : 104|9@1+ (1,0) [0|511] "" XXX
 SG_ NEW_SIGNAL_13 : 113|1@1+ (1,0) [0|1] "" XXX
 SG_ NEW_SIGNAL_14 : 115|9@1+ (1,0) [0|511] "" XXX
 SG_ NEW_SIGNAL_15 : 125|12@1+ (1,0) [0|4095] "" XXX
 SG_ NEW_SIGNAL_16 : 138|12@1+ (1,0) [0|4095] "" XXX
 SG_ NEW_SIGNAL_17 : 151|8@1+ (1,0) [0|255] "" XXX
 SG_ NEW_SIGNAL_18 : 159|9@1+ (1,0) [0|511] "" XXX
 SG_ NEW_SIGNAL_19 : 168|8@1+ (1,0) [0|255] "" XXX
 SG_ NEW_SIGNAL_20 : 176|14@1+ (1,0) [0|16383] "" XXX

BO_ 575 CAM_0x23f: 32 FR_CMR
 SG_ CHECKSUM : 0|16@1+ (1,0) [0|65535] "" XXX
 SG_ COUNTER : 16|8@1+ (1,0) [0|255] "" XXX
 SG_ NEW_SIGNAL_1 : 24|5@1+ (1,0) [0|31] "" XXX
 SG_ NEW_SIGNAL_2 : 29|1@1+ (1,0) [0|1] "" XXX
 SG_ NEW_SIGNAL_3 : 32|19@1+ (1,0) [0|524287] "" XXX
 SG_ NEW_SIGNAL_4 : 52|2@1+ (1,0) [0|3] "" XXX
 SG_ NEW_SIGNAL_5 : 54|1@1+ (1,0) [0|1] "" XXX
 SG_ NEW_SIGNAL_6 : 56|6@1+ (1,0) [0|63] "" XXX
 SG_ NEW_SIGNAL_7 : 62|13@1+ (1,0) [0|8191] "" XXX
 SG_ NEW_SIGNAL_8 : 75|1@1+ (1,0) [0|1] "" XXX
 SG_ NEW_SIGNAL_9 : 76|1@1+ (1,0) [0|1] "" XXX
 SG_ NEW_SIGNAL_10 : 78|12@1+ (1,0) [0|4095] "" XXX
 SG_ NEW_SIGNAL_11 : 91|12@1+ (1,0) [0|4095] "" XXX
 SG_ NEW_SIGNAL_12 : 104|9@1+ (1,0) [0|511] "" XXX
 SG_ NEW_SIGNAL_13 : 113|1@1+ (1,0) [0|1] "" XXX
 SG_ NEW_SIGNAL_14 : 115|9@1+ (1,0) [0|511] "" XXX
 SG_ NEW_SIGNAL_15 : 125|12@1+ (1,0) [0|4095] "" XXX
 SG_ NEW_SIGNAL_16 : 138|12@1+ (1,0) [0|4095] "" XXX
 SG_ NEW_SIGNAL_17 : 151|8@1+ (1,0) [0|255] "" XXX
 SG_ NEW_SIGNAL_18 : 159|9@1+ (1,0) [0|511] "" XXX
 SG_ NEW_SIGNAL_19 : 168|8@1+ (1,0) [0|255] "" XXX
 SG_ NEW_SIGNAL_20 : 176|14@1+ (1,0) [0|16383] "" XXX

BO_ 577 CAM_0x241: 32 FR_CMR
 SG_ CHECKSUM : 0|16@1+ (1,0) [0|65535] "" XXX
 SG_ COUNTER : 16|8@1+ (1,0) [0|255] "" XXX
 SG_ NEW_SIGNAL_1 : 24|5@1+ (1,0) [0|31] "" XXX
 SG_ NEW_SIGNAL_2 : 29|1@1+ (1,0) [0|1] "" XXX
 SG_ NEW_SIGNAL_3 : 32|19@1+ (1,0) [0|524287] "" XXX
 SG_ NEW_SIGNAL_4 : 52|2@1+ (1,0) [0|3] "" XXX
 SG_ NEW_SIGNAL_5 : 54|1@1+ (1,0) [0|1] "" XXX
 SG_ NEW_SIGNAL_6 : 56|6@1+ (1,0) [0|63] "" XXX
 SG_ NEW_SIGNAL_7 : 62|13@1+ (1,0) [0|8191] "" XXX
 SG_ NEW_SIGNAL_8 : 75|1@1+ (1,0) [0|1] "" XXX
 SG_ NEW_SIGNAL_9 : 76|1@1+ (1,0) [0|1] "" XXX
 SG_ NEW_SIGNAL_10 : 78|12@1+ (1,0) [0|4095] "" XXX
 SG_ NEW_SIGNAL_11 : 91|12@1+ (1,0) [0|4095] "" XXX
 SG_ NEW_SIGNAL_12 : 104|9@1+ (1,0) [0|511] "" XXX
 SG_ NEW_SIGNAL_13 : 113|1@1+ (1,0) [0|1] "" XXX
 SG_ NEW_SIGNAL_14 : 115|9@1+ (1,0) [0|511] "" XXX
 SG_ NEW_SIGNAL_15 : 125|12@1+ (1,0) [0|4095] "" XXX
 SG_ NEW_SIGNAL_16 : 138|12@1+ (1,0) [0|4095] "" XXX
 SG_ NEW_SIGNAL_17 : 151|8@1+ (1,0) [0|255] "" XXX
 SG_ NEW_SIGNAL_18 : 159|9@1+ (1,0) [0|511] "" XXX
 SG_ NEW_SIGNAL_19 : 168|8@1+ (1,0) [0|255] "" XXX
 SG_ NEW_SIGNAL_20 : 176|14@1+ (1,0) [0|16383] "" XXX

BO_ 578 CAM_0x242: 32 FR_CMR
 SG_ CHECKSUM : 0|16@1+ (1,0) [0|65535] "" XXX
 SG_ COUNTER : 16|8@1+ (1,0) [0|255] "" XXX
 SG_ NEW_SIGNAL_1 : 24|5@1+ (1,0) [0|31] "" XXX
 SG_ NEW_SIGNAL_2 : 29|1@1+ (1,0) [0|1] "" XXX
 SG_ NEW_SIGNAL_3 : 32|19@1+ (1,0) [0|524287] "" XXX
 SG_ NEW_SIGNAL_4 : 52|2@1+ (1,0) [0|3] "" XXX
 SG_ NEW_SIGNAL_5 : 54|1@1+ (1,0) [0|1] "" XXX
 SG_ NEW_SIGNAL_6 : 56|6@1+ (1,0) [0|63] "" XXX
 SG_ NEW_SIGNAL_7 : 62|13@1+ (1,0) [0|8191] "" XXX
 SG_ NEW_SIGNAL_8 : 75|1@1+ (1,0) [0|1] "" XXX
 SG_ NEW_SIGNAL_9 : 76|1@1+ (1,0) [0|1] "" XXX
 SG_ NEW_SIGNAL_10 : 78|12@1+ (1,0) [0|4095] "" XXX
 SG_ NEW_SIGNAL_11 : 91|12@1+ (1,0) [0|4095] "" XXX
 SG_ NEW_SIGNAL_12 : 104|9@1+ (1,0) [0|511] "" XXX
 SG_ NEW_SIGNAL_13 : 113|1@1+ (1,0) [0|1] "" XXX
 SG_ NEW_SIGNAL_14 : 115|9@1+ (1,0) [0|511] "" XXX
 SG_ NEW_SIGNAL_15 : 125|12@1+ (1,0) [0|4095] "" XXX
 SG_ NEW_SIGNAL_16 : 138|12@1+ (1,0) [0|4095] "" XXX
 SG_ NEW_SIGNAL_17 : 151|8@1+ (1,0) [0|255] "" XXX
 SG_ NEW_SIGNAL_18 : 159|9@1+ (1,0) [0|511] "" XXX
 SG_ NEW_SIGNAL_19 : 168|8@1+ (1,0) [0|255] "" XXX
 SG_ NEW_SIGNAL_20 : 176|14@1+ (1,0) [0|16383] "" XXX

BO_ 579 CAM_0x243: 32 FR_CMR
 SG_ CHECKSUM : 0|16@1+ (1,0) [0|65535] "" XXX
 SG_ COUNTER : 16|8@1+ (1,0) [0|255] "" XXX
 SG_ NEW_SIGNAL_1 : 24|5@1+ (1,0) [0|31] "" XXX
 SG_ NEW_SIGNAL_2 : 29|1@1+ (1,0) [0|1] "" XXX
 SG_ NEW_SIGNAL_3 : 32|19@1+ (1,0) [0|524287] "" XXX
 SG_ NEW_SIGNAL_4 : 52|2@1+ (1,0) [0|3] "" XXX
 SG_ NEW_SIGNAL_5 : 54|1@1+ (1,0) [0|1] "" XXX
 SG_ NEW_SIGNAL_6 : 56|6@1+ (1,0) [0|63] "" XXX
 SG_ NEW_SIGNAL_7 : 62|13@1+ (1,0) [0|8191] "" XXX
 SG_ NEW_SIGNAL_8 : 75|1@1+ (1,0) [0|1] "" XXX
 SG_ NEW_SIGNAL_9 : 76|1@1+ (1,0) [0|1] "" XXX
 SG_ NEW_SIGNAL_10 : 78|12@1+ (1,0) [0|4095] "" XXX
 SG_ NEW_SIGNAL_11 : 91|12@1+ (1,0) [0|4095] "" XXX
 SG_ NEW_SIGNAL_12 : 104|9@1+ (1,0) [0|511] "" XXX
 SG_ NEW_SIGNAL_13 : 113|1@1+ (1,0) [0|1] "" XXX
 SG_ NEW_SIGNAL_14 : 115|9@1+ (1,0) [0|511] "" XXX
 SG_ NEW_SIGNAL_15 : 125|12@1+ (1,0) [0|4095] "" XXX
 SG_ NEW_SIGNAL_16 : 138|12@1+ (1,0) [0|4095] "" XXX
 SG_ NEW_SIGNAL_17 : 151|8@1+ (1,0) [0|255] "" XXX
 SG_ NEW_SIGNAL_18 : 159|9@1+ (1,0) [0|511] "" XXX
 SG_ NEW_SIGNAL_19 : 168|8@1+ (1,0) [0|255] "" XXX
 SG_ NEW_SIGNAL_20 : 176|14@1+ (1,0) [0|16383] "" XXX

BO_ 580 CAM_0x244: 32 FR_CMR
 SG_ CHECKSUM : 0|16@1+ (1,0) [0|65535] "" XXX
 SG_ COUNTER : 16|8@1+ (1,0) [0|255] "" XXX
 SG_ NEW_SIGNAL_1 : 24|5@1+ (1,0) [0|31] "" XXX
 SG_ NEW_SIGNAL_2 : 29|1@1+ (1,0) [0|1] "" XXX
 SG_ NEW_SIGNAL_3 : 32|19@1+ (1,0) [0|524287] "" XXX
 SG_ NEW_SIGNAL_4 : 52|2@1+ (1,0) [0|3] "" XXX
 SG_ NEW_SIGNAL_5 : 54|1@1+ (1,0) [0|1] "" XXX
 SG_ NEW_SIGNAL_6 : 56|6@1+ (1,0) [0|63] "" XXX
 SG_ NEW_SIGNAL_7 : 62|13@1+ (1,0) [0|8191] "" XXX
 SG_ NEW_SIGNAL_8 : 75|1@1+ (1,0) [0|1] "" XXX
 SG_ NEW_SIGNAL_9 : 76|1@1+ (1,0) [0|1] "" XXX
 SG_ NEW_SIGNAL_10 : 78|12@1+ (1,0) [0|4095] "" XXX
 SG_ NEW_SIGNAL_11 : 91|12@1+ (1,0) [0|4095] "" XXX
 SG_ NEW_SIGNAL_12 : 104|9@1+ (1,0) [0|511] "" XXX
 SG_ NEW_SIGNAL_13 : 113|1@1+ (1,0) [0|1] "" XXX
 SG_ NEW_SIGNAL_14 : 115|9@1+ (1,0) [0|511] "" XXX
 SG_ NEW_SIGNAL_15 : 125|12@1+ (1,0) [0|4095] "" XXX
 SG_ NEW_SIGNAL_16 : 138|12@1+ (1,0) [0|4095] "" XXX
 SG_ NEW_SIGNAL_17 : 151|8@1+ (1,0) [0|255] "" XXX
 SG_ NEW_SIGNAL_18 : 159|9@1+ (1,0) [0|511] "" XXX
 SG_ NEW_SIGNAL_19 : 168|8@1+ (1,0) [0|255] "" XXX
 SG_ NEW_SIGNAL_20 : 176|14@1+ (1,0) [0|16383] "" XXX

BO_ 581 CAM_0x245: 32 FR_CMR
 SG_ CHECKSUM : 0|16@1+ (1,0) [0|65535] "" XXX
 SG_ COUNTER : 16|8@1+ (1,0) [0|255] "" XXX
 SG_ NEW_SIGNAL_1 : 24|5@1+ (1,0) [0|31] "" XXX
 SG_ NEW_SIGNAL_2 : 29|1@1+ (1,0) [0|1] "" XXX
 SG_ NEW_SIGNAL_3 : 32|19@1+ (1,0) [0|524287] "" XXX
 SG_ NEW_SIGNAL_4 : 52|2@1+ (1,0) [0|3] "" XXX
 SG_ NEW_SIGNAL_5 : 54|1@1+ (1,0) [0|1] "" XXX
 SG_ NEW_SIGNAL_6 : 56|6@1+ (1,0) [0|63] "" XXX
 SG_ NEW_SIGNAL_7 : 62|13@1+ (1,0) [0|8191] "" XXX
 SG_ NEW_SIGNAL_8 : 75|1@1+ (1,0) [0|1] "" XXX
 SG_ NEW_SIGNAL_9 : 76|1@1+ (1,0) [0|1] "" XXX
 SG_ NEW_SIGNAL_10 : 78|12@1+ (1,0) [0|4095] "" XXX
 SG_ NEW_SIGNAL_11 : 91|12@1+ (1,0) [0|4095] "" XXX
 SG_ NEW_SIGNAL_12 : 104|9@1+ (1,0) [0|511] "" XXX
 SG_ NEW_SIGNAL_13 : 113|1@1+ (1,0) [0|1] "" XXX
 SG_ NEW_SIGNAL_14 : 115|9@1+ (1,0) [0|511] "" XXX
 SG_ NEW_SIGNAL_15 : 125|12@1+ (1,0) [0|4095] "" XXX
 SG_ NEW_SIGNAL_16 : 138|12@1+ (1,0) [0|4095] "" XXX
 SG_ NEW_SIGNAL_17 : 151|8@1+ (1,0) [0|255] "" XXX
 SG_ NEW_SIGNAL_18 : 159|9@1+ (1,0) [0|511] "" XXX
 SG_ NEW_SIGNAL_19 : 168|8@1+ (1,0) [0|255] "" XXX
 SG_ NEW_SIGNAL_20 : 176|14@1+ (1,0) [0|16383] "" XXX

BO_ 582 CAM_0x246: 32 FR_CMR
 SG_ CHECKSUM : 0|16@1+ (1,0) [0|65535] "" XXX
 SG_ COUNTER : 16|8@1+ (1,0) [0|255] "" XXX
 SG_ NEW_SIGNAL_1 : 24|5@1+ (1,0) [0|31] "" XXX
 SG_ NEW_SIGNAL_2 : 29|1@1+ (1,0) [0|1] "" XXX
 SG_ NEW_SIGNAL_3 : 32|19@1+ (1,0) [0|524287] "" XXX
 SG_ NEW_SIGNAL_4 : 52|2@1+ (1,0) [0|3] "" XXX
 SG_ NEW_SIGNAL_5 : 54|1@1+ (1,0) [0|1] "" XXX
 SG_ NEW_SIGNAL_6 : 56|6@1+ (1,0) [0|63] "" XXX
 SG_ NEW_SIGNAL_7 : 62|13@1+ (1,0) [0|8191] "" XXX
 SG_ NEW_SIGNAL_8 : 75|1@1+ (1,0) [0|1] "" XXX
 SG_ NEW_SIGNAL_9 : 76|1@1+ (1,0) [0|1] "" XXX
 SG_ NEW_SIGNAL_10 : 78|12@1+ (1,0) [0|4095] "" XXX
 SG_ NEW_SIGNAL_11 : 91|12@1+ (1,0) [0|4095] "" XXX
 SG_ NEW_SIGNAL_12 : 104|9@1+ (1,0) [0|511] "" XXX
 SG_ NEW_SIGNAL_13 : 113|1@1+ (1,0) [0|1] "" XXX
 SG_ NEW_SIGNAL_14 : 115|9@1+ (1,0) [0|511] "" XXX
 SG_ NEW_SIGNAL_15 : 125|12@1+ (1,0) [0|4095] "" XXX
 SG_ NEW_SIGNAL_16 : 138|12@1+ (1,0) [0|4095] "" XXX
 SG_ NEW_SIGNAL_17 : 151|8@1+ (1,0) [0|255] "" XXX
 SG_ NEW_SIGNAL_18 : 159|9@1+ (1,0) [0|511] "" XXX
 SG_ NEW_SIGNAL_19 : 168|8@1+ (1,0) [0|255] "" XXX
 SG_ NEW_SIGNAL_20 : 176|14@1+ (1,0) [0|16383] "" XXX

BO_ 583 CAM_0x247: 32 FR_CMR
 SG_ CHECKSUM : 0|16@1+ (1,0) [0|65535] "" XXX
 SG_ COUNTER : 16|8@1+ (1,0) [0|255] "" XXX
 SG_ NEW_SIGNAL_1 : 24|5@1+ (1,0) [0|31] "" XXX
 SG_ NEW_SIGNAL_2 : 29|1@1+ (1,0) [0|1] "" XXX
 SG_ NEW_SIGNAL_3 : 32|19@1+ (1,0) [0|524287] "" XXX
 SG_ NEW_SIGNAL_4 : 52|2@1+ (1,0) [0|3] "" XXX
 SG_ NEW_SIGNAL_5 : 54|1@1+ (1,0) [0|1] "" XXX
 SG_ NEW_SIGNAL_6 : 56|6@1+ (1,0) [0|63] "" XXX
 SG_ NEW_SIGNAL_7 : 62|13@1+ (1,0) [0|8191] "" XXX
 SG_ NEW_SIGNAL_8 : 75|1@1+ (1,0) [0|1] "" XXX
 SG_ NEW_SIGNAL_9 : 76|1@1+ (1,0) [0|1] "" XXX
 SG_ NEW_SIGNAL_10 : 78|12@1+ (1,0) [0|4095] "" XXX
 SG_ NEW_SIGNAL_11 : 91|12@1+ (1,0) [0|4095] "" XXX
 SG_ NEW_SIGNAL_12 : 104|9@1+ (1,0) [0|511] "" XXX
 SG_ NEW_SIGNAL_13 : 113|1@1+ (1,0) [0|1] "" XXX
 SG_ NEW_SIGNAL_14 : 115|9@1+ (1,0) [0|511] "" XXX
 SG_ NEW_SIGNAL_15 : 125|12@1+ (1,0) [0|4095] "" XXX
 SG_ NEW_SIGNAL_16 : 138|12@1+ (1,0) [0|4095] "" XXX
 SG_ NEW_SIGNAL_17 : 151|8@1+ (1,0) [0|255] "" XXX
 SG_ NEW_SIGNAL_18 : 159|9@1+ (1,0) [0|511] "" XXX
 SG_ NEW_SIGNAL_19 : 168|8@1+ (1,0) [0|255] "" XXX
 SG_ NEW_SIGNAL_20 : 176|14@1+ (1,0) [0|16383] "" XXX

BO_ 584 CAM_0x248: 32 FR_CMR
 SG_ CHECKSUM : 0|16@1+ (1,0) [0|65535] "" XXX
 SG_ COUNTER : 16|8@1+ (1,0) [0|255] "" XXX
 SG_ NEW_SIGNAL_1 : 24|5@1+ (1,0) [0|31] "" XXX
 SG_ NEW_SIGNAL_2 : 29|1@1+ (1,0) [0|1] "" XXX
 SG_ NEW_SIGNAL_3 : 32|19@1+ (1,0) [0|524287] "" XXX
 SG_ NEW_SIGNAL_4 : 52|2@1+ (1,0) [0|3] "" XXX
 SG_ NEW_SIGNAL_5 : 54|1@1+ (1,0) [0|1] "" XXX
 SG_ NEW_SIGNAL_6 : 56|6@1+ (1,0) [0|63] "" XXX
 SG_ NEW_SIGNAL_7 : 62|13@1+ (1,0) [0|8191] "" XXX
 SG_ NEW_SIGNAL_8 : 75|1@1+ (1,0) [0|1] "" XXX
 SG_ NEW_SIGNAL_9 : 76|1@1+ (1,0) [0|1] "" XXX
 SG_ NEW_SIGNAL_10 : 78|12@1+ (1,0) [0|4095] "" XXX
 SG_ NEW_SIGNAL_11 : 91|12@1+ (1,0) [0|4095] "" XXX
 SG_ NEW_SIGNAL_12 : 104|9@1+ (1,0) [0|511] "" XXX
 SG_ NEW_SIGNAL_13 : 113|1@1+ (1,0) [0|1] "" XXX
 SG_ NEW_SIGNAL_14 : 115|9@1+ (1,0) [0|511] "" XXX
 SG_ NEW_SIGNAL_15 : 125|12@1+ (1,0) [0|4095] "" XXX
 SG_ NEW_SIGNAL_16 : 138|12@1+ (1,0) [0|4095] "" XXX
 SG_ NEW_SIGNAL_17 : 151|8@1+ (1,0) [0|255] "" XXX
 SG_ NEW_SIGNAL_18 : 159|9@1+ (1,0) [0|511] "" XXX
 SG_ NEW_SIGNAL_19 : 168|8@1+ (1,0) [0|255] "" XXX
 SG_ NEW_SIGNAL_20 : 176|14@1+ (1,0) [0|16383] "" XXX

BO_ 864 CAM_0x360: 32 FR_CMR
 SG_ CHECKSUM : 0|16@1+ (1,0) [0|65535] "" XXX
 SG_ COUNTER : 16|8@1+ (1,0) [0|255] "" XXX
 SG_ NEW_SIGNAL_1 : 24|8@1+ (1,0) [0|255] "" XXX
 SG_ NEW_SIGNAL_2 : 32|1@1+ (1,0) [0|1] "" XXX
 SG_ NEW_SIGNAL_3 : 33|7@1+ (1,0) [0|127] "" XXX
 SG_ NEW_SIGNAL_4 : 40|12@1+ (1,0) [0|4095] "" XXX
 SG_ NEW_SIGNAL_5 : 52|2@1+ (1,0) [0|3] "" XXX
 SG_ NEW_SIGNAL_6 : 56|1@1+ (1,0) [0|1] "" XXX
 SG_ NEW_SIGNAL_7 : 57|1@1+ (1,0) [0|1] "" XXX
 SG_ NEW_SIGNAL_8 : 60|3@1+ (1,0) [0|7] "" XXX
 SG_ NEW_SIGNAL_9 : 64|12@1+ (1,0) [0|4095] "" XXX
 SG_ NEW_SIGNAL_10 : 76|2@1+ (1,0) [0|3] "" XXX
 SG_ NEW_SIGNAL_11 : 80|14@1+ (1,0) [0|16383] "" XXX
 SG_ NEW_SIGNAL_12 : 96|15@1+ (1,0) [0|32767] "" XXX
 SG_ NEW_SIGNAL_13 : 112|1@1+ (1,0) [0|1] "" XXX
 SG_ NEW_SIGNAL_14 : 113|14@1+ (1,0) [0|16383] "" XXX
 SG_ NEW_SIGNAL_15 : 128|16@1+ (1,0) [0|65535] "" XXX
 SG_ NEW_SIGNAL_16 : 144|11@1+ (1,0) [0|2047] "" XXX
 SG_ NEW_SIGNAL_17 : 160|25@1+ (1,0) [0|33554431] "" XXX
 SG_ NEW_SIGNAL_18 : 192|20@1+ (1,0) [0|1048575] "" XXX
 SG_ NEW_SIGNAL_19 : 212|2@1+ (1,0) [0|3] "" XXX
 SG_ NEW_SIGNAL_20 : 224|20@1+ (1,0) [0|1048575] "" XXX
 SG_ NEW_SIGNAL_21 : 244|2@1+ (1,0) [0|3] "" XXX

BO_ 865 CAM_0x361: 32 FR_CMR
 SG_ CHECKSUM : 0|16@1+ (1,0) [0|65535] "" XXX
 SG_ COUNTER : 16|8@1+ (1,0) [0|255] "" XXX
 SG_ NEW_SIGNAL_1 : 24|8@1+ (1,0) [0|255] "" XXX
 SG_ NEW_SIGNAL_2 : 32|1@1+ (1,0) [0|1] "" XXX
 SG_ NEW_SIGNAL_3 : 33|7@1+ (1,0) [0|127] "" XXX
 SG_ NEW_SIGNAL_4 : 40|12@1+ (1,0) [0|4095] "" XXX
 SG_ NEW_SIGNAL_5 : 52|2@1+ (1,0) [0|3] "" XXX
 SG_ NEW_SIGNAL_6 : 56|1@1+ (1,0) [0|1] "" XXX
 SG_ NEW_SIGNAL_7 : 57|1@1+ (1,0) [0|1] "" XXX
 SG_ NEW_SIGNAL_8 : 60|3@1+ (1,0) [0|7] "" XXX
 SG_ NEW_SIGNAL_9 : 64|12@1+ (1,0) [0|4095] "" XXX
 SG_ NEW_SIGNAL_10 : 76|2@1+ (1,0) [0|3] "" XXX
 SG_ NEW_SIGNAL_11 : 80|14@1+ (1,0) [0|16383] "" XXX
 SG_ NEW_SIGNAL_12 : 96|15@1+ (1,0) [0|32767] "" XXX
 SG_ NEW_SIGNAL_13 : 112|1@1+ (1,0) [0|1] "" XXX
 SG_ NEW_SIGNAL_14 : 113|14@1+ (1,0) [0|16383] "" XXX
 SG_ NEW_SIGNAL_15 : 128|16@1+ (1,0) [0|65535] "" XXX
 SG_ NEW_SIGNAL_16 : 144|11@1+ (1,0) [0|2047] "" XXX
 SG_ NEW_SIGNAL_17 : 160|25@1+ (1,0) [0|33554431] "" XXX
 SG_ NEW_SIGNAL_18 : 192|20@1+ (1,0) [0|1048575] "" XXX
 SG_ NEW_SIGNAL_19 : 212|2@1+ (1,0) [0|3] "" XXX
 SG_ NEW_SIGNAL_20 : 224|20@1+ (1,0) [0|1048575] "" XXX
 SG_ NEW_SIGNAL_21 : 244|2@1+ (1,0) [0|3] "" XXX

BO_ 867 CAM_0x363: 32 FR_CMR
 SG_ CHECKSUM : 0|16@1+ (1,0) [0|65535] "" XXX
 SG_ COUNTER : 16|8@1+ (1,0) [0|255] "" XXX
 SG_ NEW_SIGNAL_1 : 24|8@1+ (1,0) [0|255] "" XXX
 SG_ NEW_SIGNAL_2 : 32|1@1+ (1,0) [0|1] "" XXX
 SG_ NEW_SIGNAL_3 : 33|7@1+ (1,0) [0|127] "" XXX
 SG_ NEW_SIGNAL_4 : 40|12@1+ (1,0) [0|4095] "" XXX
 SG_ NEW_SIGNAL_5 : 52|2@1+ (1,0) [0|3] "" XXX
 SG_ NEW_SIGNAL_6 : 56|1@1+ (1,0) [0|1] "" XXX
 SG_ NEW_SIGNAL_7 : 57|1@1+ (1,0) [0|1] "" XXX
 SG_ NEW_SIGNAL_8 : 60|3@1+ (1,0) [0|7] "" XXX
 SG_ NEW_SIGNAL_9 : 64|12@1+ (1,0) [0|4095] "" XXX
 SG_ NEW_SIGNAL_10 : 76|2@1+ (1,0) [0|3] "" XXX
 SG_ NEW_SIGNAL_11 : 80|14@1+ (1,0) [0|16383] "" XXX
 SG_ NEW_SIGNAL_12 : 96|15@1+ (1,0) [0|32767] "" XXX
 SG_ NEW_SIGNAL_13 : 112|1@1+ (1,0) [0|1] "" XXX
 SG_ NEW_SIGNAL_14 : 113|14@1+ (1,0) [0|16383] "" XXX
 SG_ NEW_SIGNAL_15 : 128|16@1+ (1,0) [0|65535] "" XXX
 SG_ NEW_SIGNAL_16 : 144|11@1+ (1,0) [0|2047] "" XXX
 SG_ NEW_SIGNAL_17 : 160|25@1+ (1,0) [0|33554431] "" XXX
 SG_ NEW_SIGNAL_18 : 192|20@1+ (1,0) [0|1048575] "" XXX
 SG_ NEW_SIGNAL_19 : 212|2@1+ (1,0) [0|3] "" XXX
 SG_ NEW_SIGNAL_20 : 224|20@1+ (1,0) [0|1048575] "" XXX
 SG_ NEW_SIGNAL_21 : 244|2@1+ (1,0) [0|3] "" XXX

BO_ 868 CAM_0x364: 32 FR_CMR
 SG_ CHECKSUM : 0|16@1+ (1,0) [0|65535] "" XXX
 SG_ COUNTER : 16|8@1+ (1,0) [0|255] "" XXX
 SG_ NEW_SIGNAL_1 : 24|8@1+ (1,0) [0|255] "" XXX
 SG_ NEW_SIGNAL_2 : 32|1@1+ (1,0) [0|1] "" XXX
 SG_ NEW_SIGNAL_3 : 33|7@1+ (1,0) [0|127] "" XXX
 SG_ NEW_SIGNAL_4 : 40|12@1+ (1,0) [0|4095] "" XXX
 SG_ NEW_SIGNAL_5 : 52|2@1+ (1,0) [0|3] "" XXX
 SG_ NEW_SIGNAL_6 : 56|1@1+ (1,0) [0|1] "" XXX
 SG_ NEW_SIGNAL_7 : 57|1@1+ (1,0) [0|1] "" XXX
 SG_ NEW_SIGNAL_8 : 60|3@1+ (1,0) [0|7] "" XXX
 SG_ NEW_SIGNAL_9 : 64|12@1+ (1,0) [0|4095] "" XXX
 SG_ NEW_SIGNAL_10 : 76|2@1+ (1,0) [0|3] "" XXX
 SG_ NEW_SIGNAL_11 : 80|14@1+ (1,0) [0|16383] "" XXX
 SG_ NEW_SIGNAL_12 : 96|15@1+ (1,0) [0|32767] "" XXX
 SG_ NEW_SIGNAL_13 : 112|1@1+ (1,0) [0|1] "" XXX
 SG_ NEW_SIGNAL_14 : 113|14@1+ (1,0) [0|16383] "" XXX
 SG_ NEW_SIGNAL_15 : 128|16@1+ (1,0) [0|65535] "" XXX
 SG_ NEW_SIGNAL_16 : 144|11@1+ (1,0) [0|2047] "" XXX
 SG_ NEW_SIGNAL_17 : 160|25@1+ (1,0) [0|33554431] "" XXX
 SG_ NEW_SIGNAL_18 : 192|20@1+ (1,0) [0|1048575] "" XXX
 SG_ NEW_SIGNAL_19 : 212|2@1+ (1,0) [0|3] "" XXX
 SG_ NEW_SIGNAL_20 : 224|20@1+ (1,0) [0|1048575] "" XXX
 SG_ NEW_SIGNAL_21 : 244|2@1+ (1,0) [0|3] "" XXX

BO_ 869 CAM_0x365: 32 FR_CMR
 SG_ CHECKSUM : 0|16@1+ (1,0) [0|65535] "" XXX
 SG_ COUNTER : 16|8@1+ (1,0) [0|255] "" XXX
 SG_ NEW_SIGNAL_1 : 24|8@1+ (1,0) [0|255] "" XXX
 SG_ NEW_SIGNAL_2 : 32|1@1+ (1,0) [0|1] "" XXX
 SG_ NEW_SIGNAL_3 : 33|7@1+ (1,0) [0|127] "" XXX
 SG_ NEW_SIGNAL_4 : 40|12@1+ (1,0) [0|4095] "" XXX
 SG_ NEW_SIGNAL_5 : 52|2@1+ (1,0) [0|3] "" XXX
 SG_ NEW_SIGNAL_6 : 56|1@1+ (1,0) [0|1] "" XXX
 SG_ NEW_SIGNAL_7 : 57|1@1+ (1,0) [0|1] "" XXX
 SG_ NEW_SIGNAL_8 : 60|3@1+ (1,0) [0|7] "" XXX
 SG_ NEW_SIGNAL_9 : 64|12@1+ (1,0) [0|4095] "" XXX
 SG_ NEW_SIGNAL_10 : 76|2@1+ (1,0) [0|3] "" XXX
 SG_ NEW_SIGNAL_11 : 80|14@1+ (1,0) [0|16383] "" XXX
 SG_ NEW_SIGNAL_12 : 96|15@1+ (1,0) [0|32767] "" XXX
 SG_ NEW_SIGNAL_13 : 112|1@1+ (1,0) [0|1] "" XXX
 SG_ NEW_SIGNAL_14 : 113|14@1+ (1,0) [0|16383] "" XXX
 SG_ NEW_SIGNAL_15 : 128|16@1+ (1,0) [0|65535] "" XXX
 SG_ NEW_SIGNAL_16 : 144|11@1+ (1,0) [0|2047] "" XXX
 SG_ NEW_SIGNAL_17 : 160|25@1+ (1,0) [0|33554431] "" XXX
 SG_ NEW_SIGNAL_18 : 192|20@1+ (1,0) [0|1048575] "" XXX
 SG_ NEW_SIGNAL_19 : 212|2@1+ (1,0) [0|3] "" XXX
 SG_ NEW_SIGNAL_20 : 224|20@1+ (1,0) [0|1048575] "" XXX
 SG_ NEW_SIGNAL_21 : 244|2@1+ (1,0) [0|3] "" XXX

BO_ 870 CAM_0x366: 32 FR_CMR
 SG_ CHECKSUM : 0|16@1+ (1,0) [0|65535] "" XXX
 SG_ COUNTER : 16|8@1+ (1,0) [0|255] "" XXX
 SG_ NEW_SIGNAL_1 : 24|8@1+ (1,0) [0|255] "" XXX
 SG_ NEW_SIGNAL_2 : 32|1@1+ (1,0) [0|1] "" XXX
 SG_ NEW_SIGNAL_3 : 33|7@1+ (1,0) [0|127] "" XXX
 SG_ NEW_SIGNAL_4 : 40|12@1+ (1,0) [0|4095] "" XXX
 SG_ NEW_SIGNAL_5 : 52|2@1+ (1,0) [0|3] "" XXX
 SG_ NEW_SIGNAL_6 : 56|1@1+ (1,0) [0|1] "" XXX
 SG_ NEW_SIGNAL_7 : 57|1@1+ (1,0) [0|1] "" XXX
 SG_ NEW_SIGNAL_8 : 60|3@1+ (1,0) [0|7] "" XXX
 SG_ NEW_SIGNAL_9 : 64|12@1+ (1,0) [0|4095] "" XXX
 SG_ NEW_SIGNAL_10 : 76|2@1+ (1,0) [0|3] "" XXX
 SG_ NEW_SIGNAL_11 : 80|14@1+ (1,0) [0|16383] "" XXX
 SG_ NEW_SIGNAL_12 : 96|15@1+ (1,0) [0|32767] "" XXX
 SG_ NEW_SIGNAL_13 : 112|1@1+ (1,0) [0|1] "" XXX
 SG_ NEW_SIGNAL_14 : 113|14@1+ (1,0) [0|16383] "" XXX
 SG_ NEW_SIGNAL_15 : 128|16@1+ (1,0) [0|65535] "" XXX
 SG_ NEW_SIGNAL_16 : 144|11@1+ (1,0) [0|2047] "" XXX
 SG_ NEW_SIGNAL_17 : 160|25@1+ (1,0) [0|33554431] "" XXX
 SG_ NEW_SIGNAL_18 : 192|20@1+ (1,0) [0|1048575] "" XXX
 SG_ NEW_SIGNAL_19 : 212|2@1+ (1,0) [0|3] "" XXX
 SG_ NEW_SIGNAL_20 : 224|20@1+ (1,0) [0|1048575] "" XXX
 SG_ NEW_SIGNAL_21 : 244|2@1+ (1,0) [0|3] "" XXX

BO_ 896 CAM_0x380: 24 FR_CMR
 SG_ CHECKSUM : 0|16@1+ (1,0) [0|65535] "" XXX
 SG_ COUNTER : 16|8@1+ (1,0) [0|255] "" XXX
 SG_ NEW_SIGNAL_1 : 24|2@1+ (1,0) [0|3] "" XXX
 SG_ NEW_SIGNAL_2 : 30|1@1+ (1,0) [0|1] "" XXX
 SG_ NEW_SIGNAL_3 : 32|1@1+ (1,0) [0|1] "" XXX
 SG_ NEW_SIGNAL_4 : 35|1@1+ (1,0) [0|1] "" XXX
 SG_ NEW_SIGNAL_5 : 37|1@1+ (1,0) [0|1] "" XXX
 SG_ NEW_SIGNAL_6 : 38|3@1+ (1,0) [0|7] "" XXX
 SG_ NEW_SIGNAL_7 : 44|1@1+ (1,0) [0|1] "" XXX
 SG_ NEW_SIGNAL_8 : 48|1@1+ (1,0) [0|1] "" XXX
 SG_ NEW_SIGNAL_9 : 50|1@1+ (1,0) [0|1] "" XXX
 SG_ NEW_SIGNAL_10 : 53|1@1+ (1,0) [0|1] "" XXX
 SG_ NEW_SIGNAL_11 : 57|1@1+ (1,0) [0|1] "" XXX
 SG_ NEW_SIGNAL_12 : 60|3@1+ (1,0) [0|7] "" XXX
 SG_ NEW_SIGNAL_13 : 67|1@1+ (1,0) [0|1] "" XXX
 SG_ NEW_SIGNAL_14 : 69|1@1+ (1,0) [0|1] "" XXX
 SG_ NEW_SIGNAL_15 : 72|2@1+ (1,0) [0|3] "" XXX
 SG_ NEW_SIGNAL_16 : 80|2@1+ (1,0) [0|3] "" XXX
 SG_ NEW_SIGNAL_17 : 83|2@1+ (1,0) [0|3] "" XXX
 SG_ NEW_SIGNAL_18 : 88|1@1+ (1,0) [0|1] "" XXX
 SG_ NEW_SIGNAL_19 : 89|2@1+ (1,0) [0|3] "" XXX
 SG_ NEW_SIGNAL_20 : 92|3@1+ (1,0) [0|7] "" XXX
 SG_ NEW_SIGNAL_21 : 96|1@1+ (1,0) [0|1] "" XXX
 SG_ NEW_SIGNAL_22 : 97|11@1+ (1,0) [0|2047] "" XXX
 SG_ NEW_SIGNAL_23 : 108|3@1+ (1,0) [0|7] "" XXX
 SG_ NEW_SIGNAL_24 : 112|1@1+ (1,0) [0|1] "" XXX
 SG_ NEW_SIGNAL_25 : 116|4@1+ (1,0) [0|15] "" XXX
 SG_ NEW_SIGNAL_26 : 120|2@1+ (1,0) [0|3] "" XXX
 SG_ NEW_SIGNAL_27 : 128|1@1+ (1,0) [0|1] "" XXX
 SG_ NEW_SIGNAL_28 : 131|2@1+ (1,0) [0|3] "" XXX

CM_ BO_ 74 "[P] Periodic";
CM_ SG_ 74 IMU_Crc1Val "The data area for CRC calculation is based on the data length (DLC) of the message DB.The CRC shall be calculated over the entire data block (excluding the CRC bytes) including the user data, alive counter and Data ID- CRC Polynomial (0x1021) , Ini";
CM_ SG_ 74 IMU_AlvCnt1Val "For the first transmission request for a data element the counter shall be initialized with 0 and shall be incremented by 1 for every subsequent send request. When the counter reaches the maximum value(0xFF), then it shall restart with 0 for the next s";
CM_ SG_ 74 IMU_YawSigSta "This signal indicates failure status of yaw rate signal and yaw rate sensing element.0000B : No failure xxx1B : IMU_Yawrate_failurexx1xB : Initialization is runningx1xxB : Reserved1xxxB : ReservedThis signal represents the physica";
CM_ SG_ 74 IMU_LatAccelSigSta "This signal indicates failure status of lateral acceleration signal and sensing element.0000B : No failurexxx1B : IMU_Lateral acceleration failurexx1xB : Initialization is runningx1xxB : Reserved1xxxB : ReservedThis signal represe";
CM_ SG_ 74 IMU_AcuRstSta "This signal indicates the status of IMU.0000B : Normal mode xxx1B : IMU Reset modexx1xB : Reservedx1xxB : Reserved1xxxB : ReservedIf ACU reset is required, ACU will send IMU RESET bit(XXX1B) up to 30 times and perform a reset. If ";
CM_ SG_ 74 IMU_YawRtVal "This signal indicates Information regarding yaw rate.physical range : -163.84..163.83 ˚/s = 0000H..FFFEhConversion : (PH) = ((HEX)-8000H)*0.005[˚/s/digit] = (HEX)*0.005[˚/s/digit] - 163.84[˚/s] ";
CM_ SG_ 74 IMU_LatAccelVal "This signal indicates Information regarding lateral acceleration.physical range : -4.1768g..4.1765g = 0000H..FFFEhConversion : (PH) = ((HEX)-8000H)*0.000127465[g/digit] = (HEX)*0.000127465[g/digit] - 4.17677312[g]";

CM_ SG_ 96 BRAKE_PRESSURE "User applied brake pedal pressure. Ramps from computer applied pressure on falling edge of cruise. Cruise cancels if !=0";
CM_ SG_ 101 BRAKE_POSITION "User applied brake pedal position, max is ~700. Signed on some vehicles";
CM_ BO_ 203 "Known in official DBC as ADAS_CMD_35_10ms";
CM_ SG_ 203 ADAS_ActvACISta "ADAS Active AngleControlInterface State";
CM_ SG_ 203 ADAS_ActvACILvl2Sta "ADAS Active AngleControlInterface Level 2 State";
CM_ SG_ 203 ADAS_StrAnglReqVal "(LFA) ADAS Steering Angle Request Value; Capped at 119.9;";
CM_ SG_ 203 ADAS_ACIAnglTqRedcGainVal "(LFA) ADAS AngleControlInterface Angle Torque Reduction Gain Value";
CM_ SG_ 203 FCA_ESA_ActvSta "FCA_ESA Active State";
CM_ SG_ 203 FCA_ESA_TqBstGainVal "FCA_ESA Torque Boost Gain Value";
CM_ BO_ 234 "Named MDPS_01_10ms on the official DBC.";
CM_ SG_ 234 CHECKSUM "The data area for CRC calculation is based on the data length (DLC) of the message DB. The CRC shall be calculated over the entire data block (excluding the CRC bytes) including the user data, alive counter and Data ID. CRC Polynomial (0x1021).";
CM_ BO_ 229 "[P] Periodic";
CM_ SG_ 229 ESC_YawSigSta "ESC_YawSigSta";
CM_ SG_ 229 ESC_LatAccelSigSta "ESC_LatAccelSigSta";
CM_ SG_ 229 ESC_LongAccelSigSta "ESC_LongAccelSigSta";
CM_ SG_ 229 ESC_YawRtVal "ESC_YawRtVal";
CM_ SG_ 229 ESC_LatAccelVal "ESC_LatAccelVal";
CM_ SG_ 229 ESC_LongAccelVal "ESC_LongAccelVal";
CM_ SG_ 234 COUNTER "For the first transmission request for a data element the counter shall be initialized with 0 and shall be incremented by 1 for every subsequent send request. When the counter reaches the maximum value(0xFF), then it shall restart with 0 for the next send request.";
CM_ SG_ 234 MDPS_WrngLmpSta "The signal indicates the ststus of the MDPS Warning lamp";
CM_ SG_ 234 MDPS_Typ "Information regarding the type of MDPS. (C-MDPS / R-MDPS / SbW)";
CM_ SG_ 234 MDPS_EngIdleRpmReq "This signal indicates the request status for engine idle rpm up according to MDPS fast rotation.";
CM_ SG_ 234 MDPS_VsmPlgInSta "This signal indicates whether the VSM function of MDPS is plugged in or not.";
CM_ SG_ 234 MDPS_VsmDfctvSta "Information regarding the MDPS defective Indication For VSM";
CM_ SG_ 234 MDPS_VsmSigErrSta "Information indicating VSM signal status";
CM_ SG_ 234 MDPS_PaPlugInSta "This signal indicates whether the PA function of MDPS is plugged in or not.";
CM_ SG_ 234 MDPS_PaModeSta "This signal indicates the status of the PA steering function.";
CM_ SG_ 234 MDPS_PaCanfltSta "This Signal should be used by only PA. This signal indicates whether the MDPS is defective in PA cooperation control. This signal is set as '1' only when MDPS Detects CAN Failure(TIMEOUT, Signal Error) of PA CAN Message";
CM_ SG_ 234 MDPS_LkaPlgInSta "This signal indicates whether the LKA function of MDPS is plugged in or not.";
CM_ SG_ 234 MDPS_LkaToiActvSta "This flag is set to 1 in response to the LKA Controller requesting the activation of the torque interface and set back to 0 in response to the LKA Controller requesting the de-activation of the torque interface.";
CM_ SG_ 234 MDPS_LkaToiUnblSta "This is a flag that is set when the MDPS is not faulty, but is temporarily unable to activate the TOI due to steering torque limiting e.g. when the supply voltage is too low.";
CM_ SG_ 234 MDPS_LkaToiFltSta "This fault flag is set when a fault within the MDPS system has been detected such that the LKA TOI can no longer function. CAN failures, internal MDPS failures, and LKA controller logic failures are all reported by this flag. Failures reported by the LKA";
CM_ SG_ 234 MDPS_LkaFailSta "This fault flag is set whilst the MDPS TOI is in a fail state and has not yet recovered from it. This could either be due to an MDPS detected fault (as communicated by the MDPS_LkaToiFltSta' flag) or an LKA detected fault (as communicated by the LKA_";
CM_ SG_ 234 MDPS_ResetOpSta "Information regarding the state of reset";
CM_ SG_ 234 MDPS_CurrModVal "This signal indicates flex steer parameter value in MDPS. For information about flex steer mode set by user, refer to MDPS_FlxStrSta signal.";
CM_ SG_ 234 MDPS_OutTqVal "MDPS column torque. This signal has direction information. '+' Value means Counter clock wise rotation. '-' value means Clock wise rotation.";
CM_ SG_ 234 MDPS_VsmActResp "Information of VSM Tqrque Intervention Act Response";
CM_ SG_ 234 Reprogram_State_MDPS "Information regarding the reprogram state";
CM_ SG_ 234 MDPS_StrTqSnsrVal "Steering torque sensor value. Physical Value > 0: Left Direction (CCW). Physical Value < 0: Right Direction (CW). '+' Value means Counter clock wise rotation. '-' value means Clock wise rotation. (Original definition was (0.005,-20.48) [0|0] but it's different from all OP expects)";
CM_ SG_ 234 MDPS_PaStrAnglVal "This value is used to inform PA of a compensated steering wheel angle by MDPS. The signal is signed 16bits. (PH) = (HEX) * 0.1 (for 0 < HEX <= 32767) or = (HEX - 65536) * 0.1 (for HEX > 32767) [Deg]. This signal has direction information.";
CM_ SG_ 234 MDPS_LoamModSta "The signal represent status of the LOAM(Loss Of Assist Mitigation) Mode";
CM_ SG_ 234 MDPS_HDPSpprtSWVer "This signal indicates HDP-MDPS Control Requirement Spec Version";
CM_ SG_ 234 MDPS_ADASAciActvSta "State for angle control";
CM_ SG_ 234 MDPS_ADASAciPluginSta "This signal indicates whether the ADASAci function of MDPS is plugged in or not.";
CM_ SG_ 234 MDPS_ADAS_AciFltSig "MDPS Fault Status for HDP Function";
CM_ SG_ 234 MDPS_EstStrAnglVal "This value is used to inform of a compensated steering wheel angle by MDPS. The signal is signed 16bits, and made by motor position sensor. (PH) = (HEX) * 0.1 (for 0 < HEX <= 32767) or = (HEX - 65536) * 0.1 (for HEX > 32767) [Deg].";
CM_ SG_ 234 MDPS_ADASAciActvSta_Lv2 "States for angle control (LV2)";
CM_ SG_ 234 MDPS_ADAS_AciFltSig_Lv2 "MDPS Fault Status for LV2 Angle Control Function";
CM_ SG_ 234 MDPS_TpaPlugInSta "This signal indicates whether the TPA function of MDPS is plugged in or not.";
CM_ SG_ 234 MDPS_TpaCanfltSta "This Signal should be used by only TPA. This signal indicates whether the MDPS is defective in TPA cooperation control. This signal is set as '1' only when MDPS Detects CAN Failure(TIMEOUT, Signal Error) of TPA CAN Message";
CM_ SG_ 234 MDPS_TpaModeSta "This signal indicates the status of the TPA steering function.";
CM_ SG_ 234 MDPS_TpaStrAnglVal "This value is used to inform TPA of a compensated steering wheel angle by MDPS. The signal is signed 16bits. (PH) = (HEX) * 0.1 (for 0 < HEX <= 32767) or = (HEX - 65536) * 0.1 (for HEX > 32767) [Deg]";
CM_ BO_ 272 "Alternative LKAS message, used on cars such as 2023 Ioniq 6, 2nd gen Kona. Matches LKAS except size is 32 bytes";
CM_ SG_ 272 ToiFltSta "This fault flag is set when a fault in the LKA system has been detected by the LKA ECU such that LKA can no longer function. CAN failures, internal video ECU failures, hard-wired component (e.g. master switch) failures and other system logic failures are";
CM_ SG_ 272 ADAS_StrAnglReqVal "(LKAS) ADAS Steering Angle Request Value; Capped at 176.7; tracks MDPS->STEERING_ANGLE when not engaged, not STEERING_SENSORS->STEERING_ANGLE";
CM_ SG_ 272 ADAS_ACIAnglTqRedcGainVal "(LKAS) ADAS AngleControlInterface Angle Torque Reduction Gain Value";
CM_ BO_ 282 "Sent by the camera containing DAW (Driver Attention Warning) information and information about HBA (High Beam Assist).";
CM_ SG_ 282 FR_CMR_Crc1Val "The data area for CRC calculation is based on the data length (DLC) of the message DB. The CRC shall be calculated over the entire data block (excluding the CRC bytes) including the user data, alive counter and Data ID - CRC Polynomial (0x1021) , In";
CM_ SG_ 282 FR_CMR_AlvCnt1Val "For the first transmission request for a data element the counter shall be initialized with 0 and shall be incremented by 1 for every subsequent send request. When the counter reaches the maximum value(0xFF), then it shall restart with 0 for the next s";
CM_ SG_ 282 HBA_SysOptSta "HBA System Option Information to Lamp Controller";
CM_ SG_ 282 HBA_SysSta "This signal indicates the status of High Beam Assist system.";
CM_ SG_ 282 HBA_IndLmpReq "HBA System Indicator Lamp Status";
CM_ SG_ 282 FCA_Equip_MFC "FCA Sensor Type";
CM_ SG_ 282 HBA_OptUsmSta "HBA Option USM Status";
CM_ SG_ 282 DAW_LVDA_PUDis "Message for displaying LVDA(Leading Vehicle Departure Alert) Warning";
CM_ SG_ 282 DAW_LVDA_OptUsmSta "LVDA USM state";
CM_ SG_ 282 DAW_OptUsmSta "This signal represents the lastest DAW ON/OFF value of USM.";
CM_ SG_ 282 DAW_SysSta "This signal represents Attention Assist System Status or Attention Level. CCNC camera: counts 5 down to 1 after start, 6 during the rest warning, 15 while the camera is faulted, 14 on K5 2025 while op steers";
CM_ SG_ 282 DAW_WrnMsgSta "0x1 value requests DAW Rest recommend warning message popup at CLU. 0x2 value requests HDA/LFA Hands-Off call at TMS.";
CM_ SG_ 282 DAW_TimeRstReq "This signal requests CLU 'Last Break Time' Reset. DAW send '0x1' when detecting driver's rest.";
CM_ SG_ 282 DAW_SnstvtyModRetVal "This signal represents the feedback value of the current ADAS warning timing.";
CM_ SG_ 282 FR_CMR_SCCEquipSta "This signal indicates equipment for SCC";
CM_ SG_ 282 FR_CMR_ReqADASMapMsgVal "This signal indicates an ADAS map message request from FR_CMR to H_U. Each bit indicates the request messages as follows. - Bit 0 : H_U_NAVI_V2_STUB_E - Bit 1 : HU_NAVI_V2_PROSHORT_E_00 (곡률) - Bit 2 : HU_NAVI_V2_PROSHORT_E_00 (곡률 외 정보)";
CM_ SG_ 282 FR_CMR_SwVer1Val "This signal indicates a major version of FR_CMR software. If FR_CMR software version is A.00, 'A' and '00' mean major and minor version respectively.";
CM_ SG_ 282 FR_CMR_SwVer2Val "This signal indicates a minor version of FR_CMR software. If FR_CMR software version is A.00, 'A' and '00' mean major and minor version respectively.";
CM_ BO_ 298 "This message controls steering and alerts regarding lateral control. Formerly known as LFA. Node is flagged as ADRV, but in reality this signal can be seen from either the FR_CMR (front camera) or the ADRV (adas ecu) for some trims.";
CM_ SG_ 298 LKA_OptUsmSta "LKA_OptionUsmStatus ##2G##LDW_LKA - LKA11 - CF_LKA_Opt_USM";
CM_ SG_ 298 LKA_RcgSta "LKA_RecognitionStatus ##2G##LDW_LKA - LKA11 - CF_LKA_LaneRecogState. CCNC camera: 3 with both lines, 1 when one line is lost, 0 when LFA is not available";
CM_ SG_ 298 LKA_LHLnWrnSta "LKA_LHLaneWarningStatus ##2G##LDW_LKA - LKA11 - CF_LKA_LHWarning. CCNC camera sends 3 (not 1) during a left lane departure warning, blinking with 0x161 LANELINE_LEFT 4/2 and 0x162 VIBRATE";
CM_ SG_ 298 LKA_RHLnWrnSta "LKA_RHLaneWarningStatus ##2G##LDW_LKA - LKA11 - CF_LKA_RHWarning. CCNC camera sends 3 (not 1) during a right lane departure warning, blinking with 0x161 LANELINE_RIGHT 4/2 and 0x162 VIBRATE";
CM_ SG_ 298 LKA_HndsoffSnd "LKA_HandsoffSound ##2G##LDW_LKA - LKA11 - CF_LKA_HandsOff_Snd. CCNC camera sets 1 together with the DAW rest warning (0x11A DAW_WrnMsgSta = 1)";
CM_ SG_ 298 LKA_StrSnd "LKA_SteeringSound ##2G##LDW_LKA - LKA11 - CF_LKA_Steer_Snd";
CM_ SG_ 298 LKA_SysIndReq "LKA_SystemIndicatorRequest ##2G##LDW_LKA - LKA11 - CF_LKA_SymbolState. CCNC camera: 0 in LFA mode; in LKA-only mode 2 while armed and 3 while steering";
CM_ SG_ 298 StrTqReqVal "This is the driver torque overlay demand value. A negative value represents a torque that would accelerate the steering wheel in a clockwise direction. This signal is always zero whilst the TOI is inactive. (the official DBC defines this as SG_ StrTqReqVal : xx|11@1+ (0.0078125,-8) [-8|7.9921875] \"Nm\" XXX but I am not changing it since it has a broader impact on the OP code)";
CM_ SG_ 298 ActToiSta "This is a flag that is set to 1 when requesting the steering to activate the torque overlay interface (TOI).  This must be done before an attempt is made to request non-zero steering torque overlay. CCNC camera drops this to 0 for about 30 ms now and then during LFA without a reason visible in other signals";
CM_ SG_ 298 ToiFltSta "This fault flag is set when a fault in the LKA system has been detected by the LKA ECU such that LKA can no longer function. CAN failures, internal video ECU failures, hard-wired component (e.g. master switch) failures and other system logic failures are";
CM_ SG_ 298 LKA_SysWrn "A signal that provides additional information on the operation of the LKA system for the HMI to display to the driver. This includes additional fault information, reasons for unavailability of the system and additional warnings like the hands-off warning. CCNC camera: 4 and 6 appear during LKA-only interventions (with 0x161 ALERTS_2 = 1 and 2); 15 while the camera is faulted";
CM_ SG_ 298 FCA_LS_WrnSta "(Reverse Engineered) This signal was observed while ELK was taking over to prevent a blind spot collision.";
CM_ SG_ 298 LKA_UsmMod "This signal indicates LKA USM Mode";
CM_ SG_ 298 ELK_SymbDisp "Emergency Lane-Keeping";
CM_ SG_ 298 Damping_Gain "ADAS Damping Gain for MDPS. Camera sets this from vehicle speed while steering: floor(interp(kph, [0, 30, 40, 50, 60, 100], [10, 10, 25, 35, 40, 80])) on Sonata HEV 2024 (92.8% exact, within 1 always); 100 when not steering. K4 2025 ADAS ECU uses a different table (about 63-65 at 60-80 kph).";
CM_ SG_ 352 SET_ME_9 "has something to do with AEB settings";
CM_ SG_ 373 ACCEnable "Likely a copy of CAN's TCS13->ACCEnable";
CM_ SG_ 373 DriverBraking "Likely derived from BRAKE->BRAKE_POSITION";
CM_ SG_ 373 DriverBrakingLowSens "Higher threshold version of DriverBraking";
CM_ SG_ 373 PROBABLY_EQUIP "aeb equip?";
CM_ SG_ 416 VSetDis "set speed in display units";
CM_ BO_ 437 "Sent by the camera containing lane and lead information.";
CM_ SG_ 437 FR_CMR_Crc3Val "The data area for CRC calculation is based on the data length (DLC) of the message DB. The CRC shall be calculated over the entire data block (excluding the CRC bytes) including the user data, alive counter and Data ID - CRC Polynomial (0x1021) , In";
CM_ SG_ 437 FR_CMR_AlvCnt3Val "For the first transmission request for a data element the counter shall be initialized with 0 and shall be incremented by 1 for every subsequent send request. When the counter reaches the maximum value(0xFF), then it shall restart with 0 for the next s";
CM_ SG_ 437 Info_LftLnQualSta "This signal indicates the quality of left line.";
CM_ SG_ 437 Info_LftLnDptSta "This signal indicates the lane departure status of left line.";
CM_ SG_ 437 Info_LftLnPosVal "This signal outputs the position of left line from camera center.";
CM_ SG_ 437 Info_LftLnHdingAnglVal "This signal outputs the heading angle of left line.";
CM_ SG_ 437 Info_LftLnCvtrVal "This signal outputs the curvature of left line.";
CM_ SG_ 437 Info_RtLnQualSta "This signal indicates the quality of right line.";
CM_ SG_ 437 Info_RtLnDptSta "This signal indicates the lane departure status of right line.";
CM_ SG_ 437 Info_RtLnPosVal "This signal outputs the position of right line from camera center.";
CM_ SG_ 437 Info_RtLnHdingAnglVal "This signal outputs the heading angle of right line.";
CM_ SG_ 437 Info_RtLnCvtrVal "This signal outputs the curvature of right line.";
CM_ SG_ 437 ID_CIPV "Valid Object = 1 to 255 - ID detected by front camera can vary depending on vehicle environment. - Additional logic would be required to apply this signal for ISG.";
CM_ SG_ 437 Relative_Velocity "+ : Preceding, - : Oncoming - Velocity detected by front camera can vary depending on vehicle environment. - Additional logic would be required to apply this signal for ISG. - Confirmaiton by Autonomous Driving Engineering Team is required to use ID_C";
CM_ SG_ 442 BCW_LtIndSta "Left blind-spot indicator. When a vehicle is detected, the BCW light on the side mirror illuminates. When the blinker is also on, the BCW light flashes on both the dash and the mirror to alert the driver.";
CM_ SG_ 442 BCW_RtIndSta "Right blind-spot indicator. When a vehicle is detected, the BCW light on the side mirror illuminates. When the blinker is also on, the BCW light flashes on both the dash and the mirror to alert the driver.";
CM_ SG_ 416 SCC_ObjSta "state of in-path object and information of controllable state.";
CM_ SG_ 480 NEW_SIGNAL_5 "Constant 1 on Sonata HEV 2024, K5 2025 and Kona EV 2nd gen; 0 on Kona HEV 2nd gen and K4 2025; changes on Tucson HEV 2025";
CM_ BO_ 506 "Sent by the camera containing speed limit information. ISLW stands for Intelligent Speed Limit Warning, and ISLA is Intelligent Speed Limit Assist. it also contains road sign information.";
CM_ SG_ 506 FR_CMR_Crc2Val "The data area for CRC calculation is based on the data length (DLC) of the message DB.The CRC shall be calculated over the entire data block (excluding the CRC bytes) including the user data, alive counter and Data ID - CRC Polynomial (0x1021) , In";
CM_ SG_ 506 FR_CMR_AlvCnt2Val "For the first transmission request for a data element the counter shall be initialized with 0 and shall be incremented by 1 for every subsequent send request. When the counter reaches the maximum value(0xFF), then it shall restart with 0 for the next s";
CM_ SG_ 506 ISLW_OptUsmSta "ISLW option information";
CM_ SG_ 506 ISLW_SysSta "Validity of ISLW information";
CM_ SG_ 506 ISLW_NoPassingInfoDis "This signal indicates additional information of ISLW. For example no passing.";
CM_ SG_ 506 ISLW_OvrlpSignDis "indicates presence of Overlap sign";
CM_ SG_ 506 ISLW_SpdCluMainDis "Main Speed Information for cluster display in main page(0x1~0xFCH: 1*(HEX VALUE) [KPH or MPH :Reference signal is  CF_Clu_SPEED_UNIT of CLU])";
CM_ SG_ 506 ISLW_SpdNaviMainDis "Main Speed information for navigation display in main page(0x1~0xFCH: 1*(HEX VALUE) [KPH or MPH :Reference signal is  Navi_ISLW_SpdUnit of Navigation)";
CM_ SG_ 506 ISLW_SubCondinfoSta1 "Indicates 1st conditional traffic sign status";
CM_ SG_ 506 ISLW_SubCondinfoSta2 "Indicates 2nd conditional traffic sign status";
CM_ SG_ 506 ISLW_SpdCluSubMainDis "Main Speed Information for cluster display in ISLW detail page";
CM_ SG_ 506 ISLW_SpdCluDisSubCond1 "Indicates conditional speed limit/no passing of 1st conditional traffic sign for Cluster in ISLW Detail page";
CM_ SG_ 506 ISLW_SpdCluDisSubCond2 "Indicates conditional speed limit/no passing of 2nd conditional traffic sign for Cluster in ISLW Detail page";
CM_ SG_ 506 ISLW_SpdNaviSubMainDis "Main Speed Information for NAVI display in ISLW detail page";
CM_ SG_ 506 ISLW_SpdNaviDisSubCond1 "Indicates conditional speed limit/no passing of 1st conditional traffic sign for NAVI in ISLW Detail page";
CM_ SG_ 506 ISLW_SpdNaviDisSubCond2 "Indicates conditional speed limit/no passing of 2nd conditional traffic sign for NAVI in ISLW Detail page";
CM_ SG_ 506 ISLA_SpdwOffst "This is a ISLA speed with offset to change the set speed of MSLA/CC/SCC.Unit (kph or mph) refers to cluster signal: CLU_SpdUnitTyp@CLU_01_20ms";
CM_ SG_ 506 ISLA_SwIgnoreReq "This is a signal requesting to ignore the -(SET) or +(SET) switch input of the driver.";
CM_ SG_ 506 ISLA_SpdChgReq "This is a signal requesting to change the set speed of MSLA/CC/SCC to the ISLA speed.";
CM_ SG_ 506 ISLA_SpdWrn "This is a warning signal when VANZ exceeds the speed limit.";
CM_ SG_ 506 ISLA_IcyWrn "This is a warning signal when the snow or ice sign is recognized when it is less than 4 'C.";
CM_ SG_ 506 ISLA_SymFlashMod "This is a signal for the flashing mode of the symbol.";
CM_ SG_ 506 ISLA_Popup "This is a signal for ISLA pop-up.";
CM_ SG_ 506 ISLA_OptUsmSta "This is a ISLA option USM signal set by the driver.";
CM_ SG_ 506 ISLA_OffstUsmSta "This is a signal for offset speed set by the driver. Unit (kph or mph) refers to cluster signal: CLU_SpdUnitTyp@CLU_01_20ms";
CM_ SG_ 506 ISLA_AutoUsmSta "This is a signal for ISLA AUTO USM set by the driver.";
CM_ SG_ 506 ISLA_Cntry "This is a signal for categorizing countries";
CM_ SG_ 506 ISLA_AddtnlSign "This is a signal for additional sign";
CM_ SG_ 506 ISLA_SchoolZone "This is a signal for School Zone";
CM_ SG_ 687 HOD_Dir_Status "This signal indicates the status of hands on/off";
CM_ BO_ 698 "Sent by the camera containing information about vehicles in front of us. IFS stands for Intelligent Front-lighting System, and this signal provides the information necessary for it to operate.";
CM_ SG_ 698 FR_CMR_Crc4Val "The data area for CRC calculation is based on the data length (DLC) of the message DB. The CRC shall be calculated over the entire data block (excluding the CRC bytes) including the user data, alive counter and Data ID - CRC Polynomial (0x1021) , In";
CM_ SG_ 698 FR_CMR_AlvCnt4Val "For the first transmission request for a data element the counter shall be initialized with 0 and shall be incremented by 1 for every subsequent send request. When the counter reaches the maximum value(0xFF), then it shall restart with 0 for the next s";
CM_ SG_ 698 IFSref_FR_CMR_Sta "This is IFS system status needed for operate the IFS function of headlamp highbeam";
CM_ SG_ 698 IFSref_VehNumVal "This is number of vehicles detected from camera";
CM_ SG_ 698 IFSref_ILLAmbtSta "This signal is status of the ambient brightness 0x0 is bright condition (HighBeam off), 0x1 is dark condition (None)";
CM_ SG_ 698 IFSref_VehLftAngl1Val "This is left angle of vehicle 1 Deg = (HEX)*0.1-25";
CM_ SG_ 698 IFSref_VehRtAngl1Val "This is right angle of vehicle 1 Deg = (HEX)*0.1-25";
CM_ SG_ 698 IFSref_VehLftAngl2Val "This is left angle of vehicle 2 Deg = (HEX)*0.1-25";
CM_ SG_ 698 IFSref_VehDst1Val "IFSref_VehicleDistance1Value";
CM_ SG_ 698 IFSref_VehRtAngl2Val "This is right angle of vehicle 2 Deg = (HEX)*0.1-25";
CM_ SG_ 698 IFSref_VehLftAngl3Val "This is left angle of vehicle 3 Deg = (HEX)*0.1-25";
CM_ SG_ 698 IFSref_VehRtAngl3Val "This is right angle of vehicle 3 Deg = (HEX)*0.1-25";
CM_ SG_ 698 IFSref_VehLftAngl4Val "This is left angle of vehicle 4 Deg = (HEX)*0.1-25";
CM_ SG_ 698 IFSref_VehRtAngl4Val "This is right angle of vehicle 4 Deg = (HEX)*0.1-25";
CM_ SG_ 698 IFSref_VehLftAngl5Val "This is left angle of vehicle 5 Deg = (HEX)*0.1-25";
CM_ SG_ 698 IFSref_VehRtAngl5Val "This is right angle of vehicle 5 Deg = (HEX)*0.1-25";
CM_ SG_ 698 IFSref_VehLftAngl6Val "This is left angle of vehicle 6 Deg = (HEX)*0.1-25";
CM_ SG_ 698 IFSref_VehRtAngl6Val "This is right angle of vehicle 6 Deg = (HEX)*0.1-25";
CM_ SG_ 698 IFSref_VehLftAngl7Val "This is left angle of vehicle 7 Deg = (HEX)*0.1-25";
CM_ SG_ 698 IFSref_VehRtAngl7Val "This is right angle of vehicle 7 Deg = (HEX)*0.1-25";
CM_ SG_ 698 IFSref_VehLftAngl8Val "This is left angle of vehicle 8 Deg = (HEX)*0.1-25";
CM_ SG_ 698 IFSref_VehRtAngl8Val "This is right angle of vehicle 8 Deg = (HEX)*0.1-25";
CM_ SG_ 698 IFSref_VehLftAngl9Val "This is left angle of vehicle 9 Deg = (HEX)*0.1-25";
CM_ SG_ 698 IFSref_VehRtAngl9Val "This is right angle of vehicle 9 Deg = (HEX)*0.1-25";
CM_ SG_ 698 IFSref_VehLftAngl10Val "This is left angle of vehicle 10 Deg = (HEX)*0.1-25";
CM_ SG_ 698 IFSref_VehRtAngl10Val "This is right angle of vehicle 10 Deg = (HEX)*0.1-25";
CM_ SG_ 698 IFSref_VehDst2Val "IFSref_VehicleDistance2Value";
CM_ SG_ 698 IFSref_VehDst3Val "IFSref_VehicleDistance3Value";
CM_ SG_ 698 IFSref_VehDst4Val "IFSref_VehicleDistance4Value";
CM_ SG_ 698 IFSref_VehDst5Val "IFSref_VehicleDistance5Value";
CM_ SG_ 698 IFSref_VehDst6Val "IFSref_VehicleDistance6Value";
CM_ SG_ 698 IFSref_VehDst7Val "IFSref_VehicleDistance7Value";
CM_ SG_ 698 IFSref_VehDst8Val "IFSref_VehicleDistance8Value";
CM_ SG_ 698 IFSref_VehDst9Val "IFSref_VehicleDistance9Value";
CM_ SG_ 698 IFSref_VehDst10Val "IFSref_VehicleDistance10Value";
CM_ SG_ 736 MAX_SPEED "Display units. Restricts car from driving above this speed unless accelerator pedal is depressed beyond pressure point";
CM_ BO_ 866 "Contains signals with detailed lane line information. Used by ADAS ECU on HDA 2 vehicles to operate LFA. Used on cars that use message 272.";
CM_ SG_ 866 LEFT_LANE_LINE "Left lane line confidence";
CM_ SG_ 866 RIGHT_LANE_LINE "Right lane line confidence";
CM_ SG_ 961 COUNTER_ALT "only increments on change";
CM_ SG_ 1041 COUNTER_ALT "only increments on change";
CM_ BO_ 1043 "Lamp signals do not seem universal on cars that use LKAS_ALT, but stalk signals do.";
CM_ SG_ 1043 COUNTER_ALT "only increments on change";
CM_ SG_ 1043 USE_ALT_LAMP "likely 1 on cars that use alt lamp signals";
CM_ BO_ 908 "Sent by the front camera at 5 Hz on CCNC cars. Only CHECKSUM and COUNTER change; the payload is constant per model.";
CM_ SG_ 908 NEW_SIGNAL_1 "0xF3 on Sonata HEV 2024, K5 2025, Kona EV/HEV 2nd gen, K4 2025; bit 31 toggles on Tucson HEV 2025.";
CM_ SG_ 908 NEW_SIGNAL_2 "0x0F on Sonata HEV 2024, K5 2025, Kona EV 2nd gen; 0x05 on Kona HEV 2nd gen and K4 2025; bits 33, 35, 39 toggle on Tucson HEV 2025.";
CM_ SG_ 282 NEW_SIGNAL_1 "Only changes on Tucson HEV 2025; 0 on other CCNC cars.";
CM_ SG_ 282 NEW_SIGNAL_2 "Constant 1 on CCNC cars except Tucson HEV 2025 (0).";
CM_ SG_ 282 NEW_SIGNAL_3 "Constant 1 on CCNC cars except Tucson HEV 2025 (0).";
CM_ SG_ 298 LKA_OnOffEquip2Sta "From the CCNC camera: 1 = LFA mode, 2 = LKA-only mode, 3 = camera faulted. Together with NEW_SIGNAL_1 it forms the low nibble of byte 9.";
CM_ SG_ 298 NEW_SIGNAL_1 "Upper half of byte 9 low nibble. Sonata HEV 2024: 2 healthy, 3 faulted. K5 2025: 3. Kona HEV 2nd gen: 1. K4 2025: 0. Model-specific; copy from the camera rather than hardcoding.";
CM_ SG_ 298 NEW_SIGNAL_2 "0 on camera-LFA CCNC cars; 1 or 3 on K4 2025.";
CM_ SG_ 298 NEW_SIGNAL_3 "0 on Sonata HEV 2024 and Kona; 1, 2 or 4 on Tucson HEV 2025, K5 2025 and K4 2025.";
CM_ SG_ 352 NEW_SIGNAL_1 "Only changes on Tucson HEV 2025 and K4 2025.";
CM_ SG_ 352 NEW_SIGNAL_2 "Only changes on Tucson HEV 2025 and K4 2025.";
CM_ SG_ 352 NEW_SIGNAL_3 "Only changes on Tucson HEV 2025 and K4 2025.";
CM_ SG_ 352 NEW_SIGNAL_4 "Only changes on Tucson HEV 2025 and K4 2025.";
CM_ SG_ 352 NEW_SIGNAL_5 "Only changes on Tucson HEV 2025 and K4 2025.";
CM_ SG_ 352 NEW_SIGNAL_6 "Constant 1 on all CCNC cars seen.";
CM_ SG_ 352 NEW_SIGNAL_7 "2 on most CCNC cars; 1 or 2 on K5 2025 and Tucson HEV 2025.";
CM_ SG_ 480 CAM_FAULT "1 while the front camera is faulted (LKA_SysWrn = 15 in 0x12A).";
CM_ SG_ 480 LFA_HANDSOFF_CANCEL "5 s pulse when LFA cancels after the hands-off escalation (ALERTS_2 = 3, SOUNDS_2 = 6 in 0x161).";
CM_ SG_ 480 NEW_SIGNAL_1 "Hands-off warning level: 5 = first warning, 6 = second warning with chime, 0 otherwise.";
CM_ SG_ 506 NEW_SIGNAL_2 "15 on Kona HEV 2nd gen and Tucson HEV 2025; 0 on other CCNC cars.";
CM_ SG_ 506 NEW_SIGNAL_5 "3 on Kona EV 2nd gen, K5 2025, K4 2025; 0 or 1 on Sonata HEV 2024; 0 on Kona HEV and Tucson HEV.";
CM_ SG_ 506 NEW_SIGNAL_9 "Changes only on Sonata HEV 2024 with a faulted camera.";
CM_ SG_ 506 NEW_SIGNAL_12 "2 or 3 on K5 2025 and Tucson HEV 2025, 3 on Kona HEV 2nd gen, 0 elsewhere.";
CM_ SG_ 512 SET_ME_E1 "openpilot sends 0xE1 here when it replaces the ADAS ECU. The CCNC camera sends 0x0C (bits 26 and 27 set).";
CM_ SG_ 512 NEW_SIGNAL_1 "Slowly changing 3-bit value from the camera (1 to 4). Together with NEW_SIGNAL_2 mostly 0x1A on Sonata HEV 2024.";
CM_ SG_ 512 NEW_SIGNAL_2 "Slowly changing 3-bit value from the camera (2 to 5).";

CM_ SG_ 353 LFA_ICON "CCNC camera: 1 standby, 2 active; on disengage 3 blinks with 0 for about 1.5 s then 1";
CM_ SG_ 353 LANELINE_LEFT "CCNC camera: 2 while LFA is active and the line is seen, 0 when LFA is off, blinks 4/2 during a departure warning";
CM_ SG_ 353 LANELINE_RIGHT "CCNC camera: 2 while LFA is active and the line is seen, 0 when LFA is off, blinks 4/2 during a departure warning";
CM_ SG_ 353 LKA_ICON "CCNC camera: 4 in LKA-only mode, blinking 4/0 while LKA steers; 1 while the camera is faulted";
CM_ SG_ 353 CENTERLINE "CCNC camera: 1 only while LFA is actively steering";
CM_ SG_ 353 ALERTS_2 "CCNC camera: 1, 2, 3 are the hands-off escalation (about 15 s, 25 s, then LFA cancel); 5 is the DAW rest warning; 1 and 2 also show during LKA-only interventions";
CM_ SG_ 353 SOUNDS_2 "CCNC camera: 2 with LKA-only interventions, 3 with the second hands-off warning and the DAW rest warning, 6 when LFA cancels for hands-off";
CM_ SG_ 353 DAW_ICON "CCNC camera: blinks 1/0 during the DAW rest warning; 1 steady while the camera is faulted";
CM_ SG_ 354 VIBRATE "CCNC camera: 1 during a lane departure warning";
CM_ SG_ 354 SPEEDLIMIT_FLASH "CCNC camera: 4 while over the speed limit (0x1FA ISLA_SpdWrn = 1), else 2";
CM_ SG_ 480 LFA_ICON "Same meaning as 0x161 LFA_ICON but without the blink: 3 for about 1.5 s on disengage, then 1";
CM_ BO_ 357 "24 bytes on CCNC cars with the LFA camera layout (Sonata HEV 2024, K5 2025, Kona, Tucson HEV 2025). 16 bytes on the camera bus of HDA2-layout CCNC cars (K4 2025, Ioniq 5 N), where this ID is a different message.";
CM_ BO_ 961 "8 bytes on Tucson HEV 2025. 24 bytes on the camera bus of HDA2-layout CCNC cars (K4 2025, Ioniq 5 N), where this ID is a different message.";
CM_ BO_ 256 "32 bytes on K5 2025 and some K4 2025; 24 bytes on Ioniq 5 N and other K4 2025.";
CM_ BO_ 560 "HDA2-layout CCNC camera (K4 2025, Ioniq 5 N), camera bus, about 33 Hz. Standard Hyundai CAN FD checksum and counter.";
CM_ SG_ 560 NEW_SIGNAL_1 "Observed 0..18 (19 values); most common 1, 4, 2, 0.";
CM_ SG_ 560 NEW_SIGNAL_2 "Observed 0..6 (7 values); most common 0, 3, 2, 4.";
CM_ SG_ 560 NEW_SIGNAL_3 "Constant 1 on K4 2025 and Ioniq 5 N.";
CM_ SG_ 560 NEW_SIGNAL_4 "Observed 0..1 (2 values); most common 0, 1.";
CM_ SG_ 560 NEW_SIGNAL_5 "Observed 3..10 (8 values); most common 5, 6, 7, 8.";
CM_ SG_ 560 NEW_SIGNAL_6 "Observed 0..1 (2 values); most common 0, 1.";
CM_ SG_ 560 NEW_SIGNAL_7 "Observed 0..1 (2 values); most common 0, 1.";
CM_ SG_ 560 NEW_SIGNAL_8 "Observed 0..3 (4 values); most common 0, 1, 2, 3.";
CM_ SG_ 560 NEW_SIGNAL_9 "Observed 0..1 (2 values); most common 0, 1.";
CM_ BO_ 565 "HDA2-layout CCNC camera, camera bus, about 33 Hz. Object slot 1 of 20 (0x235 to 0x248). All 20 slots share this layout. Slot 12 (0x240) is not defined here because RADAR_0x240 uses that ID on other cars.";
CM_ SG_ 565 NEW_SIGNAL_1 "Observed 0..26 (14 values); most common 0, 3, 8, 13.";
CM_ SG_ 565 NEW_SIGNAL_2 "Observed 0..1 (2 values); most common 0, 1.";
CM_ SG_ 565 NEW_SIGNAL_3 "Observed 0..393215 (110276 values); most common 0, 226815, 222975, 228351. Its bits always change together; it may be more than one value packed side by side.";
CM_ SG_ 565 NEW_SIGNAL_4 "Observed 0..3 (4 values); most common 2, 0, 1, 3.";
CM_ SG_ 565 NEW_SIGNAL_5 "Observed 0..1 (2 values); most common 1, 0.";
CM_ SG_ 565 NEW_SIGNAL_6 "Observed 0..60 (34 values); most common 0, 11, 12, 39.";
CM_ SG_ 565 NEW_SIGNAL_7 "Observed 0..8190 (5984 values); most common 0, 2, 97, 98.";
CM_ SG_ 565 NEW_SIGNAL_8 "Observed 0..1 (2 values); most common 0, 1.";
CM_ SG_ 565 NEW_SIGNAL_9 "Observed 0..1 (2 values); most common 0, 1.";
CM_ SG_ 565 NEW_SIGNAL_10 "Observed 0..4046 (1637 values); most common 4046, 0, 2050, 1999.";
CM_ SG_ 565 NEW_SIGNAL_11 "Observed 0..3063 (1896 values); most common 0, 2000, 1999, 2001.";
CM_ SG_ 565 NEW_SIGNAL_12 "Observed 0..511 (512 values); most common 488, 0, 500, 501.";
CM_ SG_ 565 NEW_SIGNAL_13 "Observed 0..1 (2 values); most common 1, 0.";
CM_ SG_ 565 NEW_SIGNAL_14 "Observed 0..511 (274 values); most common 256, 0, 492, 511.";
CM_ SG_ 565 NEW_SIGNAL_15 "Observed 0..4000 (935 values); most common 4000, 0, 2000, 2001.";
CM_ SG_ 565 NEW_SIGNAL_16 "Observed 0..4092 (2124 values); most common 4092, 0, 2048, 2049.";
CM_ SG_ 565 NEW_SIGNAL_17 "Observed 0..255 (256 values); most common 116, 0, 58, 57.";
CM_ SG_ 565 NEW_SIGNAL_18 "Observed 0..508 (151 values); most common 2, 0, 141, 133.";
CM_ SG_ 565 NEW_SIGNAL_19 "Observed 0..255 (232 values); most common 24, 0, 86, 56.";
CM_ SG_ 565 NEW_SIGNAL_20 "Observed 0..12692 (8445 values); most common 12692, 0, 9002, 8327.";
CM_ BO_ 566 "HDA2-layout CCNC camera object slot 2 of 20. Same layout as CAM_0x235.";
CM_ BO_ 567 "HDA2-layout CCNC camera object slot 3 of 20. Same layout as CAM_0x235.";
CM_ BO_ 568 "HDA2-layout CCNC camera object slot 4 of 20. Same layout as CAM_0x235.";
CM_ BO_ 569 "HDA2-layout CCNC camera object slot 5 of 20. Same layout as CAM_0x235.";
CM_ BO_ 570 "HDA2-layout CCNC camera object slot 6 of 20. Same layout as CAM_0x235.";
CM_ BO_ 571 "HDA2-layout CCNC camera object slot 7 of 20. Same layout as CAM_0x235.";
CM_ BO_ 572 "HDA2-layout CCNC camera object slot 8 of 20. Same layout as CAM_0x235.";
CM_ BO_ 573 "HDA2-layout CCNC camera object slot 9 of 20. Same layout as CAM_0x235.";
CM_ BO_ 574 "HDA2-layout CCNC camera object slot 10 of 20. Same layout as CAM_0x235.";
CM_ BO_ 575 "HDA2-layout CCNC camera object slot 11 of 20. Same layout as CAM_0x235.";
CM_ BO_ 577 "HDA2-layout CCNC camera object slot 13 of 20. Same layout as CAM_0x235.";
CM_ BO_ 578 "HDA2-layout CCNC camera object slot 14 of 20. Same layout as CAM_0x235.";
CM_ BO_ 579 "HDA2-layout CCNC camera object slot 15 of 20. Same layout as CAM_0x235.";
CM_ BO_ 580 "HDA2-layout CCNC camera object slot 16 of 20. Same layout as CAM_0x235.";
CM_ BO_ 581 "HDA2-layout CCNC camera object slot 17 of 20. Same layout as CAM_0x235.";
CM_ BO_ 582 "HDA2-layout CCNC camera object slot 18 of 20. Same layout as CAM_0x235.";
CM_ BO_ 583 "HDA2-layout CCNC camera object slot 19 of 20. Same layout as CAM_0x235.";
CM_ BO_ 584 "HDA2-layout CCNC camera object slot 20 of 20. Same layout as CAM_0x235.";
CM_ BO_ 864 "HDA2-layout CCNC camera, camera bus, about 20 Hz. One of seven lane messages (0x360 to 0x366) that share this layout. 0x362 keeps its existing CAM_0x362 definition because openpilot copies it.";
CM_ SG_ 864 NEW_SIGNAL_1 "Observed 0..255 (256 values); most common 0, 184, 16, 17.";
CM_ SG_ 864 NEW_SIGNAL_2 "Observed 0..1 (2 values); most common 0, 1.";
CM_ SG_ 864 NEW_SIGNAL_3 "Observed 0..127 (128 values); most common 0, 5, 127, 8.";
CM_ SG_ 864 NEW_SIGNAL_4 "Observed 0..4093 (1254 values); most common 0, 3000, 34, 532.";
CM_ SG_ 864 NEW_SIGNAL_5 "Observed 0..2 (3 values); most common 0, 1, 2.";
CM_ SG_ 864 NEW_SIGNAL_6 "Observed 0..1 (2 values); most common 0, 1.";
CM_ SG_ 864 NEW_SIGNAL_7 "Observed 0..1 (2 values); most common 0, 1.";
CM_ SG_ 864 NEW_SIGNAL_8 "Observed 0..4 (5 values); most common 0, 3, 1, 2.";
CM_ SG_ 864 NEW_SIGNAL_9 "Observed 0..4094 (1280 values); most common 0, 4094, 34, 2047.";
CM_ SG_ 864 NEW_SIGNAL_10 "Observed 0..3 (3 values); most common 0, 3, 1.";
CM_ SG_ 864 NEW_SIGNAL_11 "Observed 0..8528 (2961 values); most common 0, 160, 1436, 215.";
CM_ SG_ 864 NEW_SIGNAL_12 "Observed 0..26622 (8178 values); most common 0, 4094, 2047, 160.";
CM_ SG_ 864 NEW_SIGNAL_13 "Observed 0..1 (2 values); most common 0, 1.";
CM_ SG_ 864 NEW_SIGNAL_14 "Observed 0..13311 (6788 values); most common 0, 36, 1180, 35.";
CM_ SG_ 864 NEW_SIGNAL_15 "Observed 0..65535 (28306 values); most common 47620, 0, 59277, 71.";
CM_ SG_ 864 NEW_SIGNAL_16 "Observed 0..1459 (1174 values); most common 32, 1, 16, 3.";
CM_ SG_ 864 NEW_SIGNAL_17 "Observed 0..27918755 (20896 values); most common 255885, 0, 150, 129022. Its bits always change together; it may be more than one value packed side by side.";
CM_ SG_ 864 NEW_SIGNAL_18 "Observed 0..1048562 (15724 values); most common 4094, 0, 47620, 2047. Its bits always change together; it may be more than one value packed side by side.";
CM_ SG_ 864 NEW_SIGNAL_19 "Observed 0..2 (3 values); most common 0, 1, 2.";
CM_ SG_ 864 NEW_SIGNAL_20 "Observed 0..1048575 (22893 values); most common 3000, 0, 47620, 2047. Its bits always change together; it may be more than one value packed side by side.";
CM_ SG_ 864 NEW_SIGNAL_21 "Observed 0..2 (3 values); most common 0, 1, 2.";
CM_ BO_ 865 "HDA2-layout CCNC camera lane message. Same layout as CAM_0x360.";
CM_ BO_ 867 "HDA2-layout CCNC camera lane message. Same layout as CAM_0x360.";
CM_ BO_ 868 "HDA2-layout CCNC camera lane message. Same layout as CAM_0x360.";
CM_ BO_ 869 "HDA2-layout CCNC camera lane message. Same layout as CAM_0x360.";
CM_ BO_ 870 "HDA2-layout CCNC camera lane message. Same layout as CAM_0x360.";
CM_ BO_ 896 "HDA2-layout CCNC camera, camera bus, about 20 Hz. Mostly status flags.";
CM_ SG_ 896 NEW_SIGNAL_1 "Observed 0..3 (2 values); most common 0, 3.";
CM_ SG_ 896 NEW_SIGNAL_2 "Observed 0..1 (2 values); most common 0, 1.";
CM_ SG_ 896 NEW_SIGNAL_3 "Observed 0..1 (2 values); most common 1, 0.";
CM_ SG_ 896 NEW_SIGNAL_4 "Observed 0..1 (2 values); most common 0, 1.";
CM_ SG_ 896 NEW_SIGNAL_5 "Observed 0..1 (2 values); most common 0, 1.";
CM_ SG_ 896 NEW_SIGNAL_6 "Observed 0..6 (5 values); most common 0, 1, 5, 2.";
CM_ SG_ 896 NEW_SIGNAL_7 "Observed 0..1 (2 values); most common 0, 1.";
CM_ SG_ 896 NEW_SIGNAL_8 "Observed 0..1 (2 values); most common 0, 1.";
CM_ SG_ 896 NEW_SIGNAL_9 "Observed 0..1 (2 values); most common 0, 1.";
CM_ SG_ 896 NEW_SIGNAL_10 "Observed 0..1 (2 values); most common 0, 1.";
CM_ SG_ 896 NEW_SIGNAL_11 "Observed 0..1 (2 values); most common 0, 1.";
CM_ SG_ 896 NEW_SIGNAL_12 "Observed 0..4 (3 values); most common 0, 4, 3.";
CM_ SG_ 896 NEW_SIGNAL_13 "Observed 0..1 (2 values); most common 0, 1.";
CM_ SG_ 896 NEW_SIGNAL_14 "Observed 0..1 (2 values); most common 0, 1.";
CM_ SG_ 896 NEW_SIGNAL_15 "Observed 0..3 (2 values); most common 0, 3.";
CM_ SG_ 896 NEW_SIGNAL_16 "Observed 0..3 (4 values); most common 0, 2, 1, 3.";
CM_ SG_ 896 NEW_SIGNAL_17 "Observed 0..3 (4 values); most common 0, 1, 3, 2.";
CM_ SG_ 896 NEW_SIGNAL_18 "Observed 0..1 (2 values); most common 0, 1.";
CM_ SG_ 896 NEW_SIGNAL_19 "Observed 0..2 (3 values); most common 1, 2, 0.";
CM_ SG_ 896 NEW_SIGNAL_20 "Observed 0..5 (5 values); most common 3, 1, 4, 0.";
CM_ SG_ 896 NEW_SIGNAL_21 "Observed 0..1 (2 values); most common 0, 1.";
CM_ SG_ 896 NEW_SIGNAL_22 "Observed 0..2047 (15 values); most common 0, 25, 32, 22.";
CM_ SG_ 896 NEW_SIGNAL_23 "Constant per model: 1 on Ioniq 5 N, 7 on K4 2025.";
CM_ SG_ 896 NEW_SIGNAL_24 "Constant 1 on K4 2025 and Ioniq 5 N.";
CM_ SG_ 896 NEW_SIGNAL_25 "Constant 15 on K4 2025 and Ioniq 5 N.";
CM_ SG_ 896 NEW_SIGNAL_26 "Observed 0..2 (3 values); most common 0, 1, 2.";
CM_ SG_ 896 NEW_SIGNAL_27 "Observed 0..1 (2 values); most common 0, 1.";
CM_ SG_ 896 NEW_SIGNAL_28 "Observed 0..3 (2 values); most common 0, 3.";
CM_ BO_ 576 "On HDA2-layout CCNC cars (K4 2025, Ioniq 5 N) the camera sends a different 32-byte message on this ID: object slot 12 of 20, same layout as CAM_0x235.";
CM_ SG_ 272 NEW_SIGNAL_1 "From the HDA2-layout CCNC camera. K4 2025: 2, 1, 3; Ioniq 5 N: 1.";
CM_ SG_ 272 NEW_SIGNAL_2 "From the HDA2-layout CCNC camera. K4 2025: 2, 3; Ioniq 5 N: 0.";
CM_ SG_ 272 NEW_SIGNAL_3 "From the HDA2-layout CCNC camera. K4 2025: 1, 0; Ioniq 5 N: 0.";
CM_ SG_ 272 NEW_SIGNAL_4 "From the HDA2-layout CCNC camera. K4 2025: 0; Ioniq 5 N: 0.";
CM_ SG_ 272 NEW_SIGNAL_5 "From the HDA2-layout CCNC camera. K4 2025: 0, 1; Ioniq 5 N: 0.";
CM_ SG_ 272 NEW_SIGNAL_6 "From the HDA2-layout CCNC camera. K4 2025: 0, 1; Ioniq 5 N: 0.";
CM_ SG_ 272 NEW_SIGNAL_7 "From the HDA2-layout CCNC camera. K4 2025: 1; Ioniq 5 N: 1, 0.";
CM_ SG_ 272 NEW_SIGNAL_8 "From the HDA2-layout CCNC camera. K4 2025: 1; Ioniq 5 N: 1.";
CM_ SG_ 272 NEW_SIGNAL_9 "From the HDA2-layout CCNC camera. K4 2025: 1; Ioniq 5 N: 1.";
CM_ SG_ 272 NEW_SIGNAL_10 "From the HDA2-layout CCNC camera. K4 2025: 0, 1; Ioniq 5 N: 1, 0.";
CM_ SG_ 272 NEW_SIGNAL_11 "From the HDA2-layout CCNC camera. K4 2025: 65535; Ioniq 5 N: 65535.";
VAL_ 53 GEAR 0 "P" 4 "S" 5 "D" 6 "N" 7 "R";
VAL_ 64 GEAR 0 "P" 5 "D" 6 "N" 7 "R";
VAL_ 69 GEAR 0 "P" 5 "D" 6 "N" 7 "R";
VAL_ 96 TRACTION_AND_STABILITY_CONTROL 0 "On" 5 "Limited" 1 "Off";
VAL_ 112 GEAR 0 "P" 5 "D" 6 "N" 7 "R";
VAL_ 203 ADAS_ActvACISta 0 "INIT" 1 "INACTIVE" 2 "ACTIVE35(ACTIVE)" 3 "ACTIVE33(Redundancy)" 4 "RESERVED" 5 "RESERVED" 6 "RESERVED" 7 "RESERVED" 8 "RESERVED" 9 "RESERVED" 10 "RESERVED" 11 "RESERVED" 12 "RESERVED" 13 "RESERVED" 14 "RESERVED" 15 "RESERVED";
VAL_ 203 ADAS_ActvACILvl2Sta 0 "INIT" 1 "INACTIVE" 2 "ACTIVE35(ACTIVE)" 3 "RESERVED" 4 "RESERVED" 5 "RESERVED" 6 "RESERVED" 7 "RESERVED" 8 "RESERVED" 9 "RESERVED" 10 "RESERVED" 11 "RESERVED" 12 "RESERVED" 13 "RESERVED" 14 "RESERVED" 15 "RESERVED";
VAL_ 203 ADAS_StrAnglReqVal 0 "0 (0x000~0x3FFF valid range)" 16383 "16383 (0x000~0x3FFF valid range)";
VAL_ 203 ADAS_ACIAnglTqRedcGainVal 0 "0x0x00~0xFA:Real Values" 250 "0x0x00~0xFA:Real Values" 251 "RESERVED" 252 "RESERVED" 253 "RESERVED" 254 "RESERVED" 255 "RESERVED";
VAL_ 203 FCA_ESA_ActvSta 0 "Inactive" 1 "Active" 2 "RESERVED" 3 "RESERVED";
VAL_ 203 FCA_ESA_TqBstGainVal 0 "0x0x00~0xFA:Real Values" 250 "0x0x00~0xFA:Real Values" 251 "RESERVED" 252 "RESERVED" 253 "RESERVED" 254 "RESERVED" 255 "RESERVED";
VAL_ 234 MDPS_WrngLmpSta 0 "MDPS Malfunction Warning lamp OFF" 1 "MDPS Malfunciton Warning lamp BLANKING(2Hz)" 2 "MDPS Malfunction Warning lamp ON" 3 "MDPS Malfunction Warning lamp BLANKING(1Hz)" 4 "RESERVED" 5 "RESERVED" 6 "RESERVED" 7 "Error Indicator";
VAL_ 234 MDPS_Typ 0 "C-MDPS" 1 "R-MDPS(Dual Pinion)" 2 "R-MDPS(Belt)" 3 "SbW" 4 "RESERVED" 5 "RESERVED" 6 "RESERVED" 7 "Error Indicator";
VAL_ 234 MDPS_EngIdleRpmReq 0 "Current Consumption is Low" 1 "Current Consumption is High" 2 ":RESERVED" 3 "Error Indicator";
VAL_ 234 MDPS_VsmPlgInSta 0 "The VSM function of MDPS is not plugged in (unplugged)." 1 "The VSM function of MDPS is plugged in." 2 "RESERVED" 3 "Error Indicator";
VAL_ 234 MDPS_VsmDfctvSta 0 "MDPS is not defective" 1 "MDPS is defective" 2 "RESERVED" 3 "Error Indicator";
VAL_ 234 MDPS_VsmSigErrSta 0 "VSM1 signal is not error" 1 "VSM signal is error" 2 "RESERVED" 3 "Error Indicator";
VAL_ 234 MDPS_PaPlugInSta 0 "The PA function of MDPS is not plugged in (unplugged)." 1 "The PA function of MDPS is plugged in." 2 "RESERVED" 3 "Error Indicator";
VAL_ 234 MDPS_PaModeSta 0 "RESERVED" 1 "Steering still in initialization phase" 2 "Steering ready, waits for PA command" 3 "Steering set in standby by PA" 4 "Steering requested to go to first activation step" 5 "Steering requested to go to final activation step" 6 "Steering went to error internally" 7 "Steering aborted the automatic function" 8 "RESERVED" 9 "RESERVED" 10 "RESERVED" 11 "RESERVED" 12 "RESERVED" 13 "RESERVED" 14 "RESERVED" 15 "Error Indicator";
VAL_ 234 MDPS_PaCanfltSta 0 "No Failure" 1 "Failure about Pa can message" 2 "RESERVED" 3 "Error Indicator";
VAL_ 234 MDPS_LkaPlgInSta 0 "The LKA function of MDPS is not plugged in (unplugged)." 1 "The LKA function of MDPS is plugged in." 2 "RESERVED" 3 "Error Indicator";
VAL_ 234 MDPS_LkaToiActvSta 0 "Deactivated" 1 "Activated" 2 "RESERVED" 3 "Error Indicator";
VAL_ 234 MDPS_LkaToiUnblSta 0 "Available" 1 "Unavailable" 2 "RESERVED" 3 "Error Indicator";
VAL_ 234 MDPS_LkaToiFltSta 0 "No fault" 1 "Faulty" 2 "RESERVED" 3 "Error Indicator";
VAL_ 234 MDPS_LkaFailSta 0 "Not in fail state" 1 "In fail state" 2 "RESERVED" 3 "Error Indicator";
VAL_ 234 MDPS_ResetOpSta 0 "Normal" 1 "Reset Complete" 2 "Reset Fail" 3 "RESERVED";
VAL_ 234 MDPS_CurrModVal 0 "Comfort Mode" 1 "Sport Mode" 2 "Sport+ Mode" 3 "Chauffeur Mode" 4 "Mild Mode" 5 "Drift Mode" 6 "RESERVED" 7 "Error Indicator";
VAL_ 234 MDPS_OutTqVal 0 "0x0x000~0xFFD:real values" 4093 "0x0x000~0xFFD:real values" 4094 "RESERVED" 4095 "Error Indicator";
VAL_ 234 MDPS_VsmActResp 0 "VSM Control inactivated" 1 "VSM Control Activated" 2 "RESERVED" 3 "Invalid";
VAL_ 234 Reprogram_State_MDPS 0 "normal operation" 1 "reprogramming" 2 "RESERVED" 3 "Error Indicator";
VAL_ 234 MDPS_StrTqSnsrVal 0 "0 (0x000~0x7FFD valid range)" 8189 "32765 (0x000~0x1FFD valid range)" 8190 "RESERVED" 8191 "Error Indicator";
VAL_ 234 MDPS_PaStrAnglVal 0 "0 (0x000~0x7FFD valid range)" 32765 "32765 (0x000~0x7FFD valid range)" 32766 "Not Initialized" 32767 "Error Indicator" 32768 "32768 (0x8000~0xFFFF valid range)" 65535 "65535 (0x8000~0xFFFF valid range)";
VAL_ 234 MDPS_LoamModSta 0 "Normal" 1 "Loam Flag Warning Display" 2 "RESERVED" 3 "Error Indicator";
VAL_ 234 MDPS_HDPSpprtSWVer 0 "HDP-MDPS Control Requirement Version" 1 "HDP-MDPS Control Requirement Version" 2 "HDP-MDPS Control Requirement Version" 3 "HDP-MDPS Control Requirement Version" 4 "HDP-MDPS Control Requirement Version" 5 "HDP-MDPS Control Requirement Version" 6 "HDP-MDPS Control Requirement Version" 7 "HDP-MDPS Control Requirement Version" 8 "HDP-MDPS Control Requirement Version" 9 "HDP-MDPS Control Requirement Version" 10 "HDP-MDPS Control Requirement Version" 11 "HDP-MDPS Control Requirement Version" 12 "HDP-MDPS Control Requirement Version" 13 "HDP-MDPS Control Requirement Version" 14 "HDP-MDPS Control Requirement Version" 15 "HDP-MDPS Control Requirement Version" 16 "HDP-MDPS Control Requirement Version" 17 "HDP-MDPS Control Requirement Version" 18 "HDP-MDPS Control Requirement Version" 19 "HDP-MDPS Control Requirement Version" 20 "HDP-MDPS Control Requirement Version" 21 "HDP-MDPS Control Requirement Version" 22 "HDP-MDPS Control Requirement Version" 23 "HDP-MDPS Control Requirement Version" 24 "HDP-MDPS Control Requirement Version" 25 "HDP-MDPS Control Requirement Version" 26 "HDP-MDPS Control Requirement Version" 27 "HDP-MDPS Control Requirement Version" 28 "HDP-MDPS Control Requirement Version" 29 "HDP-MDPS Control Requirement Version" 30 "HDP-MDPS Control Requirement Version" 31 "HDP-MDPS Control Requirement Version";
VAL_ 234 MDPS_ADASAciActvSta 0 "INIT" 1 "INACTIVE" 2 "ACTIVE35(ACTIVE)" 3 "ACTIVE33(Redundancy)" 4 "RESERVED" 5 "RESERVED" 6 "RESERVED" 7 "RESERVED" 8 "RESERVED" 9 "RESERVED" 10 "RESERVED" 11 "RESERVED" 12 "RESERVED" 13 "RESERVED" 14 "RESERVED" 15 "RESERVED";
VAL_ 234 MDPS_ADASAciPluginSta 0 "ADASAciNotPlugged-in" 1 "ADASAciPlugged-in" 2 "RESERVED" 3 "ErrorIndicator";
VAL_ 234 MDPS_ADAS_AciFltSig 0 "No Fault" 1 "MDPS Fault" 2 "Fault Except MDPS" 3 "Both Fault";
VAL_ 234 MDPS_EstStrAnglVal 0 "0 (0x000~0x7FFD valid range)" 32765 "32765 (0x000~0x7FFD valid range)" 32766 "Not Initialized" 32767 "Error Indicator" 32768 "32768 (0x8000~0xFFFF valid range)" 65535 "65535 (0x8000~0xFFFF valid range)";
VAL_ 234 MDPS_ADASAciActvSta_Lv2 0 "Not USED" 1 "INACTIVE" 2 "ACTIVE35(Active)" 3 "Reserved" 4 "Reserved" 5 "Reserved" 6 "Reserved" 7 "Reserved" 8 "Reserved" 9 "Reserved" 10 "Reserved" 11 "Reserved" 12 "Reserved" 13 "Reserved" 14 "Reserved" 15 "Reserved";
VAL_ 234 MDPS_ADAS_AciFltSig_Lv2 0 "No Fault" 1 "MDPS Fault" 2 "Fault Except MDPS" 3 "Both Fault" 4 "Temporarily Unavailable" 5 "Temporarily Unavailable and MDPS Fault" 6 "Temporarily Unavailable and Fault Except MDPS" 7 "Temporarily Unavailable and Both Fault";
VAL_ 234 MDPS_TpaPlugInSta 0 "The TPA function of MDPS is not plugged in (unplugged)" 1 "The TPA function of MDPS is plugged in" 2 "RESERVED" 3 "Error Indicator";
VAL_ 234 MDPS_TpaCanfltSta 0 "No Failure" 1 "Failure about Tpa can message" 2 "RESERVED" 3 "Error Indicator";
VAL_ 234 MDPS_TpaModeSta 0 "RESERVED" 1 "Steering still in initialization phase" 2 "Steering ready, waits for TPA command" 3 "Steering set in standby by TPA" 4 "Steering requested to go to first activation step activation step" 5 "Steering requested to go to final activation step" 6 "Steering went to error internally" 7 "Steering aborted the automatic function" 14 "RESERVED" 15 "Error Indicator";
VAL_ 234 MDPS_TpaStrAnglVal 0 "0 (0x000~0x7FFD valid range)" 32765 "32765 (0x000~0x7FFD valid range)" 32766 "Not Initialized" 32767 "Error Indicator" 32768 "32768 (0x8000~0xFFFF valid range)" 65535 "65535 (0x8000~0xFFFF valid range)";
VAL_ 272 LKA_OptUsmSta 0 "None LKA/LDW Option (Default)" 1 "LDW" 2 "LKA" 3 "Reserved" 4 "LDW Only (None LKA)" 5 "LDW only OFF (None LKA)" 6 "LDW/LKA OFF" 7 "Invalid";
VAL_ 272 LKA_RcgSta 0 "Not Recognized" 1 "Left Lane Recognition" 2 "Right Lane Recognition" 3 "Full Lane Recognition" 4 "Reserved" 5 "Reserved" 6 "Reserved" 7 "Reserved";
VAL_ 272 LKA_LHLnWrnSta 0 "No Warning" 1 "Lane Departure Warning" 2 "Reserved" 3 "Reserved";
VAL_ 272 LKA_RHLnWrnSta 0 "No Warning" 1 "Lane Departure Warning" 2 "Reserved" 3 "Reserved";
VAL_ 272 LKA_HndsoffSnd 0 "Off" 1 "Hands-off Sound Warning" 2 "Reserved" 3 "Reserved";
VAL_ 272 LKA_StrSnd 0 "Off" 1 "Warning" 2 "Reserved" 3 "Reserved";
VAL_ 272 LKA_SysIndReq 0 "Off" 1 "Unavailable_(Grey On)" 2 "Lane Recognized_(Green On)" 3 "Lane Departure_(Green Blink)" 4 "System Fail_(Orange On)" 5 "Not Calibrated_(Orange Blink)" 6 "Regulation_(Orange On)" 7 "Reserved";
VAL_ 272 StrTqReqVal 2046 "Reserved" 2047 "Invalid";
VAL_ 272 ActToiSta 0 "De-activate TOI" 1 "Activate TOI" 2 "Reserved" 3 "Error indicator";
VAL_ 272 ToiFltSta 0 "No Fault" 1 "Fault" 2 "Reserved" 3 "Error indicatorr";
VAL_ 272 LKA_SysWrn 0 "No Info" 1 "Reserved" 2 "Reserved" 3 "Reserved" 4 "Hands-Off Warning 1" 5 "Hands-Off Warning 2" 6 "Hands-Off Warning 3" 7 "Reserved" 8 "Reserved" 9 "System Automatic off" 10 "Reserved" 11 "Reserved" 12 "Reserved" 13 "Reserved" 14 "Reserved" 15 "System Fail";
VAL_ 272 LKA_UsmMod 0 "NONE" 1 "LKA 1 mode" 2 "Reserved" 3 "LDW";
VAL_ 272 ADAS_ACIAnglTqRedcGainVal 0 "0x0x00~0xFA:Real Values" 250 "0x0x00~0xFA:Real Values" 251 "RESERVED" 252 "RESERVED" 253 "RESERVED" 254 "RESERVED" 255 "RESERVED";
VAL_ 282 HBA_SysOptSta 0 "None HBA Option (Default)" 1 "HBA Option" 2 "Reserved" 3 "Error indicator";
VAL_ 282 HBA_SysSta 0 "HBA Disable" 1 "HBA Enable & High Beam Off" 2 "HBA Enable & High Beam On" 3 "Reserved" 4 "Reserved" 5 "Reserved" 6 "Reserved" 7 "System Fail";
VAL_ 282 HBA_IndLmpReq 0 "HBA Indicator Lamp Off" 1 "HBA Indicator Lamp On" 2 "Reserved" 3 "Error indicator";
VAL_ 282 FCA_Equip_MFC 0 "No Coding" 1 "Sensor Fusion FCA" 2 "Camera only FCA" 3 "No FCA Option" 4 "ADAS_DRV Option" 5 "Reserved" 6 "Not used" 7 "Error indicator";
VAL_ 282 HBA_OptUsmSta 0 "None HBA Option (Default)" 1 "HBA Function Off" 2 "HBA Function On" 3 "Invalid (Fail)";
VAL_ 282 DAW_LVDA_PUDis 0 "Default" 1 "Display “Leading vehicle departure alert”" 2 "Reserved" 3 "Error indicator";
VAL_ 282 DAW_LVDA_OptUsmSta 0 "No Option (default)" 1 "Off" 2 "On" 3 "Error Indicator";
VAL_ 282 DAW_OptUsmSta 0 "None DAW Option (Default)" 1 "System Off" 2 "System On" 3 "Reserved" 4 "Reserved" 5 "Reserved" 6 "Reserved" 7 "Invalid (Gray)";
VAL_ 282 DAW_SysSta 0 "System Off" 1 "Attention Level  1" 2 "Attention Level  2" 3 "Attention Level  3" 4 "Attention Level  4" 5 "Attention Level  5" 6 "Reserved" 7 "Reserved" 8 "Reserved" 9 "Reserved" 10 "Reserved" 11 "Reserved" 12 "Reserved" 13 "Reserved" 14 "System Standby" 15 "System Fail";
VAL_ 282 DAW_WrnMsgSta 0 "No Warning" 1 "Rest Recommend Warning" 2 "Hands-Off TMS call request" 3 "Reserved" 4 "Reserved" 5 "Reserved" 6 "Reserved" 7 "Error indicator";
VAL_ 282 DAW_TimeRstReq 0 "No signal" 1 "Time reset" 2 "Reserved" 3 "Error indicator";
VAL_ 282 DAW_SnstvtyModRetVal 0 "Default" 1 "Late" 2 "Normal" 3 "Reserved" 4 "Reserved" 5 "Reserved" 6 "Reserved" 7 "Invalid";
VAL_ 282 FR_CMR_SCCEquipSta 0 "Not Applied" 1 "Applied" 2 "Not used" 3 "Error Indicator";
VAL_ 298 LKA_OptUsmSta 0 "None LKA/LDW Option (Default)" 1 "LDW" 2 "LKA" 3 "Reserved" 4 "LDW Only (None LKA)" 5 "LDW only OFF (None LKA)" 6 "LDW/LKA OFF" 7 "Invalid";
VAL_ 298 LKA_RcgSta 0 "Not Recognized" 1 "Left Lane Recognition" 2 "Right Lane Recognition" 3 "Full Lane Recognition" 4 "Reserved" 5 "Reserved" 6 "Reserved" 7 "Reserved";
VAL_ 298 LKA_LHLnWrnSta 0 "No Warning" 1 "Lane Departure Warning" 2 "Reserved" 3 "Reserved";
VAL_ 298 LKA_RHLnWrnSta 0 "No Warning" 1 "Lane Departure Warning" 2 "Reserved" 3 "Reserved";
VAL_ 298 LKA_HndsoffSnd 0 "Off" 1 "Hands-off Sound Warning" 2 "Reserved" 3 "Reserved";
VAL_ 298 LKA_StrSnd 0 "Off" 1 "Warning" 2 "Reserved" 3 "Reserved";
VAL_ 298 LKA_SysIndReq 0 "Off" 1 "Unavailable_(Grey On)" 2 "Lane Recognized_(Green On)" 3 "Lane Departure_(Green Blink)" 4 "System Fail_(Orange On)" 5 "Not Calibrated_(Orange Blink)" 6 "Regulation_(Orange On)" 7 "Reserved";
VAL_ 298 StrTqReqVal 2046 "Reserved" 2047 "Invalid";
VAL_ 298 ActToiSta 0 "De-activate TOI" 1 "Activate TOI" 2 "Reserved" 3 "Error indicator";
VAL_ 298 ToiFltSta 0 "No Fault" 1 "Fault" 2 "Reserved" 3 "Error indicatorr";
VAL_ 298 LKA_SysWrn 0 "No Info" 1 "Reserved" 2 "Reserved" 3 "Reserved" 4 "Hands-Off Warning 1" 5 "Hands-Off Warning 2" 6 "Hands-Off Warning 3" 7 "Reserved" 8 "Reserved" 9 "System Automatic off" 10 "Reserved" 11 "Reserved" 12 "Reserved" 13 "Reserved" 14 "Reserved" 15 "System Fail";
VAL_ 298 FCA_LS_WrnSta 3 "ELK Steering to the right";
VAL_ 298 LKA_UsmMod 0 "NONE" 1 "LKA 1 mode" 2 "Reserved" 3 "LDW";
VAL_ 298 ELK_SymbDisp 3 "Evasive Action Taking Place";
VAL_ 304 PARK_BUTTON 1 "Pressed" 2 "Not Pressed";
VAL_ 304 KNOB_POSITION 1 "R" 2 "N (on R side)" 3 "Centered" 4 "N (on D side)" 5 "D";
VAL_ 304 GEAR 1 "P" 2 "R" 3 "N" 4 "D";
VAL_ 352 AEB_SETTING 1 "off" 2 "warning only" 3 "active assist";
VAL_ 353 FCA_ICON 0 "HIDDEN" 1 "ORANGE" 2 "RED";
VAL_ 353 FCA_ALT_ICON 0 "HIDDEN" 1 "ORANGE" 3 "RED";
VAL_ 353 LKA_ICON 0 "HIDDEN" 1 "ORANGE" 3 "GRAY" 4 "GREEN";
VAL_ 353 HBA_ICON 0 "HIDDEN" 1 "GRAY" 2 "GREEN";
VAL_ 353 FCA_IMAGE 0 "HIDDEN" 2 "VISIBLE";
VAL_ 353 BCA_LEFT 0 "HIDDEN" 1 "VISIBLE" 2 "VISIBLE+ICON";
VAL_ 353 BCA_RIGHT 0 "HIDDEN" 1 "VISIBLE" 2 "VISIBLE+ICON";
VAL_ 353 LCA_LEFT_ARROW 0 "HIDDEN" 1 "VISIBLE";
VAL_ 353 LCA_RIGHT_ARROW 0 "HIDDEN" 1 "VISIBLE";
VAL_ 353 CENTERLINE 0 "HIDDEN" 1 "GREEN";
VAL_ 353 TARGET 0 "HIDDEN" 1 "BLUE" 3 "WHITE";
VAL_ 353 LANELINE_LEFT 0 "GRAY" 1 "HIDDEN" 2 "WHITE" 4 "ORANGE" 6 "GREEN";
VAL_ 353 LANELINE_RIGHT 0 "GRAY" 1 "HIDDEN" 2 "WHITE" 4 "ORANGE" 6 "GREEN";
VAL_ 353 LANE_HIGHLIGHT 0 "HIDDEN" 1 "GREEN" 2 "WHITE" 3 "BLUE" 4 "ORANGE" 5 "RED";
VAL_ 353 LANE_LEFT 0 "HIDDEN" 1 "GREEN";
VAL_ 353 LANE_RIGHT 0 "HIDDEN" 1 "GREEN";
VAL_ 353 LANE_ZOOM 0 "ZOOM" 1 "HIDDEN";
VAL_ 353 ALERTS_1 0 "HIDDEN" 1 "WARNING_ONLY_CAR_CENTER" 2 "WARNING_ONLY_CAR_LEFT" 3 "WARNING_ONLY_CAR_RIGHT" 4 "WARNING_ONLY_LEFT" 5 "WARNING_ONLY_RIGHT" 11 "EMERGENCY_BRAKING_CAR_CENTER" 12 "EMERGENCY_BRAKING_CAR_LEFT" 13 "EMERGENCY_BRAKING_CAR_RIGHT" 14 "EMERGENCY_BRAKING_LEFT" 15 "EMERGENCY_BRAKING_RIGHT" 21 "EMERGENCY_STEERING_CAR_LEFT" 22 "EMERGENCY_STEERING_CAR_RIGHT" 23 "EMERGENCY_STEERING_CAR_LEFT_AWAY" 24 "EMERGENCY_STEERING_CAR_RIGHT_AWAY" 25 "EMERGENCY_STEERING_REAR_LEFT" 26 "EMERGENCY_STEERING_REAR_RIGHT" 33 "DRIVE_CAREFULLY";
VAL_ 353 ALERTS_2 0 "HIDDEN" 1 "KEEP_HANDS_ON_STEERING_WHEEL" 2 "KEEP_HANDS_ON_STEERING_WHEEL_RED" 3 "LANE_FOLLOWING_ASSIST_DEACTIVATED" 4 "HIGHWAY_DRIVING_ASSIST_DEACTIVATED" 5 "CONSIDER_TAKING_A_BREAK" 6 "PRESS_OK_BUTTON_TO_ENABLE_LANE_CHANGE_ASSIST" 7 "COLLISION_RISK_VEHICLE_TAKING_EMERGENCY_CONTROL" 8 "TAKE_CONTROL_OF_THE_VEHICLE_IMMEDIATELY_VEHICLE_IS_STOPPING" 9 "TAKE_CONTROL_OF_THE_VEHICLE_IMMEDIATELY" 11 "HIGHWAY_DRIVING_PILOT_SYSTEM_DEACTIVATED_AUDIBLE" 12 "KEEP_YOUR_EYES_ON_THE_ROAD" 13 "HIGHWAY_DRIVING_PILOT_CONDITIONS_NOT_MET_AUDIBLE" 14 "COLLISION_RISK_VEHICLE_TAKING_EMERGENCY_CONTROL" 15 "SET_THE_WIPER_AND_LIGHT_CONTROLS_TO_AUTO" 16 "BE_PREPARED_TO_TAKE_CONTROL_OF_THE_VEHICLE_AT_ANY_TIME" 21 "TAKE_CONTROL_OF_THE_VEHICLE_IMMEDIATELY_VEHICLE_IS_STOPPING" 10 "TAKE_CONTROL_OF_THE_VEHICLE_IMMEDIATELY";
VAL_ 353 ALERTS_3 1 "AUTOMATICALLY_ADJUSTING_TO_THE_POSTED_SPEED_LIMIT" 2 "SET_SPEED_CHANGED" 3 "AUTOMATICALLY_ADJUSTING_TO_THE_POSTED_SPEED_LIMIT" 4 "SET_SPEED_CHANGED" 7 "DISTANCE_1" 8 "DISTANCE_2" 9 "DISTANCE_3" 10 "DISTANCE_4" 17 "DRIVE_CAREFULLY" 18 "CHECK_SURROUNDINGS" 19 "CONDITIONS_NOT_MET" 20 "LANES_NOT_DETECTED" 21 "CURVE_TOO_SHARP" 22 "LANE_TOO_NARROW" 23 "ROAD_TYPE_NOT_SUPPORTED" 24 "UNAVAILABLE_WITH_HAZARD_LIGHTS_ON" 25 "VEHICLE_SPEED_IS_TOO_LOW" 26 "KEEP_HANDS_ON_STEERING_WHEEL" 27 "LANE_TYPE_NOT_SUPPORTED" 28 "LANE_ASSIST_CANCELED_STEERING_INPUT_DETECTED" 0 "HIDDEN";
VAL_ 353 ALERTS_4 0 "HIDDEN" 1 "TAKE_FOOT_OFF_THE_ACCELERATOR_PEDAL" 2 "TAKE_FOOT_OFF_THE_BRAKE_PEDAL" 3 "UNAVAILABLE_WHILE_HIGHWAY_DRIVING_PILOT_SYSTEM_IS_ACTIVE" 4 "TO_EXIT_HDP_GRASP_THE_STEERING_WHEEL_THEN_PRESS_AND_HOLD_THE_HDP_BUTTON" 5 "ACCELERATOR_PEDAL_OPERATION_LIMITED_FOR_SAFETY" 6 "TURN_OFF_HAZARD_WARNING_LIGHTS_AND_TURN_SIGNAL" 7 "KEEP_THE_DRIVERS_SEAT_IN_A_SAFE_DRIVING_POSITION" 16 "SET_SPEED_CHANGED" 17 "ACTIVATING_WINDSHIELD_DEFOG_TO_MAINTAIN_THE_DRIVERS_VIEW" 18 "SET_THE_WIPER_AND_LIGHT_CONTROLS_TO_AUTO" 19 "VEHICLE_SPEED_REDUCED_FOR_SAFETY_MERGING_LANES_AHEAD" 20 "SPEED_REDUCED_FOR_SAFETY_CONSTRUCTION_ZONE_DETECTED" 21 "VEHICLE_SPEED_LIMITED_SENSOR_DETECTION_RANGE_LIMITED" 22 "PREPARE_TO_TAKE_CONTROL_UNSUPPORTED_ROAD_TYPE_AHEAD" 23 "PREPARE_TO_TAKE_CONTROL_ENTRANCE_AND_EXIT_RAMPS_AHEAD" 24 "PREPARE_TO_TAKE_CONTROL_TOLLGATE_AHEAD" 25 "PREPARE_TO_TAKE_CONTROL_ROAD_EVENT_AHEAD" 26 "CLEARING_PATH_FOR_EMERGENCY_VEHICLE" 27 "VEHICLE_IS_TOO_SLOW_COMPARED_TO_TRAFFIC_FLOW" 28 "AFTER_SUNSET_HDP_IS_AVAILABLE_IN_AN_INSIDE_LANE_BEHIND_A_LEADING_VEHICLE" 29 "VEHICLE_SPEED_LIMITED_MERGING_LANES_AHEAD" 30 "VEHICLE_SPEED_LIMITED_CONSTRUCTION_ZONE_DETECTED" 31 "VEHICLE_SPEED_TEMPORARILY_LIMITED_FOR_SAFETY" 32 "PRESS_AND_HOLD_THE_BUTTON_TO_ACTIVATE_HIGHWAY_DRIVING_PILOT" 40 "HIGHWAY_DRIVING_PILOT_SYSTEM_IS_AVAILABLE" 64 "RESTART_VEHICLE_AFTER_EMERGENCY_STOP" 65 "CONNECTED_SERVICES_UNAVAILABLE" 66 "AVAILABLE_AFTER_VEHICLE_SOFTWARE_IS_UPDATED" 67 "ROAD_TYPE_NOT_SUPPORTED" 68 "ONLY_AVAILABLE_WHILE_DRIVING_ON_HIGHWAY_LANES" 69 "UNAVAILABLE_WHILE_OTHER_WARNINGS_ARE_ACTIVE" 70 "CANNOT_ACTIVATE_AT_ENTRANCE_EXIT_RAMPS" 71 "LANE_UNSUPPORTED" 72 "NOT_AVAILABLE_IN_THIS_COUNTRY" 79 "CHECKING_THE_DETECTION_RANGE_OF_THE_SENSOR" 80 "SHIFT_TO_D" 81 "ENGINE_STOPPED_BY_AUTO_STOP" 82 "INCREASE_DISTANCE_FROM_VEHICLE_AHEAD" 83 "VEHICLE_SPEED_IS_TOO_HIGH" 84 "CENTER_VEHICLE_IN_THE_LANE" 85 "PARKING_ASSIST_IS_ACTIVE" 86 "ESC_ACTIVIATION_REQUIRED" 87 "UNFOLD_SIDE_VIEW_MIRRORS" 88 "UNAVAILABLE_IN_THE_OUTER_LANE_AFTER_SUNSET" 89 "VEHICLE_SPEED_LIMITED_AFTER_SUNSET_FOR_SAFETY" 90 "LEADING_VEHICLE_NOT_DETECTED" 104 "AGGRESSIVE_BRAKING_OR_STEERING_DETECTED" 110 "SENSOR_AUTO_CALIBRATION_IN_PROGRESS_THIS_MAY_TAKE_SEVERAL_MINUTES" 111 "HIGHWAY_DRIVING_PILOT_WILL_BE_AVAILABLE_SHORTLY" 112 "IF_STEERING_WHEEL_IS_USED_HDP_WILL_BE_DEACTIVATED" 120 "IMPACT_DETECTED" 128 "UNSUITABLE_USE_OF_ACCELERATOR_PEDAL_DETECTED" 129 "GEAR_SHIFTER_USE_DETECTED" 130 "UNSUITABLE_BRAKE_PEDAL_USE_DETECTED" 131 "VEHICLE_START_BUTTON_PRESSED" 132 "VEHICLE_HAS_BEEN_STOPPED_FOR_TOO_LONG" 141 "TRAFFIC_CONGESTION_HAS_CLEARED" 142 "ENTRANCE_AND_EXIT_RAMPS_AHEAD" 143 "UNSUPPORTED_LANE_AHEAD" 144 "UNSUPPORTED_ROAD_TYPE_AHEAD" 145 "LANE_DEPARTURE_DETECTED" 146 "MAXIMUM_SPEED_EXCEEDED" 147 "HIGHWAY_DRIVING_PILOT_LIMITED_ABNORMAL_VEHICLE_CONTROLLER_STATUS" 148 "WIPER_LIGHT_CONTROL_SETTINGS_ARE_UNSUITABLE_FOR_USE_WITH_HDP" 149 "WINDSHIELD_DEFOG_SYSTEM_STATUS_IS_UNSUITABLE_FOR_USE_WITH_HDP" 150 "HAZARD_WARNING_LIGHTS_OR_TURN_SIGNAL_OPERATION_DETECTED" 151 "PERFORMING_EVASIVE_STEERING_OBSTACLES_DETECTED_AHEAD" 152 "HIGHWAY_DRIVING_PILOT_LIMITED_SENSOR_DETECTION_RANGE_LIMITED" 160 "CHECK_HIGHWAY_DRIVING_PILOT_SYSTEM" 161 "SAFETY_FUNCTION_ACTIVATED" 176 "CAMERA_OBSCURED" 177 "RADAR_BLOCKED" 178 "LIDAR_BLOCKED" 179 "AIRBAG_WARNING_LIGHT_IS_ON" 180 "ATTACHED_TRAILED_DETECTED" 181 "HIGH_OUTSIDE_TEMPERATURE" 182 "LOW_OUTSIDE_TEMPERATURE" 190 "UNAVAILABLE_DUE_TO_THE_ROAD_EVENT_INFORMATION_RECEIVED" 191 "UNAVAILABLE_NEAR_TOLLGATES" 192 "DRIVERS_SEAT_IS_NOT_IN_A_SAFE_DRIVING_POSITION" 193 "VEHICLE_DRIVING_THE_WRONG_WAY_DETECTED_AHEAD" 194 "EMERGENCY_VEHICLE_DETECTED" 195 "OBSTACLE_DETECTED_AHEAD" 196 "SENSOR_BLOCKED_DUE_TO_RAIN_SNOW_OR_ROAD_DEBRIS" 197 "SLIPPERY_ROAD_SURFACE_DETECTED" 198 "CONSTRUCTION_ZONE_DETECTED_AHEAD" 199 "PEDESTRIAN_DETECTED_AHEAD" 200 "UNSUITABLE_DRIVERS_SEAT_POSITION_DETECTED" 201 "FOLDED_SIDE_VIEW_MIRRORS_DETECTED" 208 "VEHICLE_POSITION_NOT_DETECTED" 209 "LANE_NOT_DETECTED" 210 "DRIVER_NOT_DETECTED" 211 "KEEP_YOUR_EYES_ON_THE_ROAD" 212 "LEADING_VEHICLE_REQUIRED_AFTER_SUNSET" 213 "TBD" 240 "LOW_FUEL" 241 "LOW_TIRE_PRESSURE" 242 "DOOR_OPEN" 243 "TRUNK_OPEN" 244 "HOOD_OPEN" 245 "SEAT_BELT_NOT_FASTENED" 246 "PARKING_BRAKE_ACTIVATED" 247 "LOW_EV_BATTERY" 248 "HDP_DEACTIVATION_DELAYED_RISK_OF_COLLISION_DETECTED" 249 "LIFTGATE_OPENED";
VAL_ 353 ALERTS_5 0 "HIDDEN" 1 "DRIVERS_GRASP_NOT_DETECTED_DRIVING_SPEED_WILL_BE_LIMITED" 2 "WATCH_FOR_SURROUNDING_VEHICLES" 3 "SMART_CRUISE_CONTROL_DEACTIVATED" 4 "SMART_CRUISE_CONTROL_CONDITIONS_NOT_MET" 5 "USE_SWITCH_OR_PEDAL_TO_ACCELERATE" 6 "DRIVER_ASSISTNCE_SYSTEM_LIMITED_TRAILER_ATTACHED" 7 "DRIVER_ASSISTNCE_SYSTEM_LIMITED_DRIVER_FULL_FACE_NOT_VISIBLE" 11 "LEADING_VEHICLE_IS_DRIVING_AWAY" 12 "STOP_VEHICLE_THEN_TRY_AGAIN" 19 "ACTIVATING_HIGHWAY_DRIVING_PILOT_SYSTEM" 20 "CONTINUING_USE_OF_HIGHWAY_DRIVING_PILOT_WILL_RESULT_IN_DEVIATION_FROM_THE_NAVIGATION_ROUTE" 21 "HIGHWAY_DRIVING_PILOT_SYSTEM_DEACTIVATED_SILENT" 22 "HIGHWAY_DRIVING_PILOT_SYSTEM_NOT_APPLIED" 23 "HIGHWAY_DRIVING_PILOT_CONDITIONS_NOT_MET_SILENT";
VAL_ 353 MUTE 0 "NONE" 1 "MUTED";
VAL_ 353 SOUNDS_1 0 "NONE" 3 "FAST BEEP" 6 "CONSTANT BEEP";
VAL_ 353 SOUNDS_2 0 "NONE" 2 "SINGLE CHIME" 3 "CONSTANT CHIME" 6 "FAST BEEP";
VAL_ 353 SOUNDS_3 0 "NONE" 3 "SOFT CHIME" 5 "SINGLE CHIME";
VAL_ 353 SOUNDS_4 0 "NONE" 2 "DOUBLE CHIME";
VAL_ 353 SETSPEED_HUD 0 "HIDDEN" 1 "GRAY" 2 "GREEN" 3 "WHITE" 5 "CYAN";
VAL_ 353 DISTANCE_LEAD 0 "HIDDEN" 1 "GRAY" 2 "WHITE";
VAL_ 353 DISTANCE_CAR 0 "HIDDEN" 1 "GRAY" 2 "WHITE" 3 "CYAN A";
VAL_ 353 DISTANCE_SPACING 0 "HIDDEN" 1 "BLUE" 3 "WHITE" 5 "CYAN";
VAL_ 353 SETSPEED 0 "HIDDEN" 1 "GRAY" 2 "GREEN" 3 "WHITE" 6 "CYAN";
VAL_ 353 HDA_ICON 0 "HIDDEN" 1 "GRAY" 2 "GREEN" 3 "WHITE" 5 "CYAN HDP";
VAL_ 353 SLA_ICON 0 "HIDDEN" 1 "WHITE UP" 2 "WHITE DOWN" 3 "GREEN UP" 4 "GREEN DOWN";
VAL_ 353 NAV_ICON 0 "HIDDEN" 1 "GRAY" 2 "GREEN" 4 "WHITE";
VAL_ 353 LFA_ICON 0 "HIDDEN" 1 "GRAY" 2 "GREEN" 3 "WHITE" 5 "CYAN";
VAL_ 353 LCA_LEFT_ICON 0 "HIDDEN" 1 "GRAY" 2 "GREEN" 4 "WHITE";
VAL_ 353 LCA_RIGHT_ICON 0 "HIDDEN" 1 "GRAY" 2 "GREEN" 4 "WHITE";
VAL_ 353 BACKGROUND 0 "HIDDEN" 1 "BLUE" 3 "ORANGE" 4 "FLASHING ORANGE" 6 "FLASHING RED" 7 "GRAY";
VAL_ 353 DAW_ICON 0 "HIDDEN" 1 "ORANGE";
VAL_ 353 CAR_CIRCLE 0 "HIDDEN" 1 "GRAY" 2 "CYAN";
VAL_ 354 COUNTRY 0 "HIDDEN" 1 "SOUTH_KOREA" 4 "INTL" 5 "JAPAN" 6 "CANADA" 7 "USA" 8 "CHINA" 9 "INTL";
VAL_ 354 SPEEDLIMIT_FLASH 0 "HIDDEN" 1 "ERROR" 2 "NORMAL" 4 "RED";
VAL_ 354 SIGNS 0 "HIDDEN" 1 "PEDESTRIAN_CROSSING" 2 "SCHOOL_CROSSWALK" 8 "STOP" 9 "YIELD" 16 "DO_NOT_PASS" 19 "DO_NOT_ENTER" 24 "ROUNDABOUT" 26 "RIGHT_CURVE_AHEAD" 27 "LEFT_CURVE_AHEAD" 28 "SLIGHT_RIGHT_CURVE_AHEAD" 29 "SLIGHT_LEFT_CURVE_AHEAD";
VAL_ 354 SPEEDLIMIT_WEATHER 0 "HIDDEN" 1 "RAIN" 2 "SNOW" 3 "RAIN+SNOW" 4 "TRAILER";
VAL_ 354 VIBRATE 0 "NONE" 1 "VIBRATE";
VAL_ 354 LEAD 0 "HIDDEN" 1 "GRAY BOX" 2 "WHITE BOX" 3 "GRAY CAR" 4 "WHITE CAR" 5 "GRAY TRUCK" 6 "WHITE TRUCK" 7 "GRAY PERSON" 8 "WHITE PERSON" 9 "GRAY BICYCLE" 10 "WHITE BICYCLE" 11 "GRAY MOTORCYCLE" 12 "WHITE MOTORCYCLE" 13 "DARK CONE" 14 "ORANGE CONE";
VAL_ 354 LEAD_ALT 0 "HIDDEN" 1 "GRAY BOX" 2 "WHITE BOX" 3 "DIM CONE" 4 "ORANGE CONE";
VAL_ 354 LEAD_LEFT 0 "HIDDEN" 1 "GRAY BOX" 2 "WHITE BOX" 3 "GRAY CAR" 4 "WHITE CAR" 5 "GRAY TRUCK" 6 "WHITE TRUCK" 7 "GRAY PERSON" 8 "WHITE PERSON" 9 "GRAY BICYCLE" 10 "WHITE BICYCLE" 11 "GRAY MOTORCYCLE" 12 "WHITE MOTORCYCLE" 13 "DARK CONE" 14 "ORANGE CONE";
VAL_ 354 LEAD_RIGHT 0 "HIDDEN" 1 "GRAY BOX" 2 "WHITE BOX" 3 "GRAY CAR" 4 "WHITE CAR" 5 "GRAY TRUCK" 6 "WHITE TRUCK" 7 "GRAY PERSON" 8 "WHITE PERSON" 9 "GRAY BICYCLE" 10 "WHITE BICYCLE" 11 "GRAY MOTORCYCLE" 12 "WHITE MOTORCYCLE" 13 "DARK CONE" 14 "ORANGE CONE";
VAL_ 354 FAULT_FSS 0 "HIDDEN" 1 "CHECK_FORWARD_SAFETY_SYSTEM" 2 "FORWARD_SAFETY_SYSTEM_LIMITED_CAMERA_OBSCURED" 3 "FORWARD_SAFETY_SYSTEM_LIMITED_RADAR_BLOCKED";
VAL_ 354 FAULT_FCA 0 "HIDDEN" 1 "CHECK_FORWARD_SIDE_SAFETY_SYSTEM" 2 "FORWARD_SIDE_SAFETY_SYSTEM_LIMITED_CAMERA_OBSCURED" 3 "FORWARD_SIDE_SAFETY_SYSTEM_LIMITED_RADAR_BLOCKED";
VAL_ 354 FAULT_LSS 0 "HIDDEN" 1 "CHECK_LANE_SAFETY_SYSTEM" 2 "LANE_SAFETY_SYSTEM_DISABLED_CAMERA_OBSCURED";
VAL_ 354 FAULT_SLA 0 "HIDDEN" 1 "CHECK_SPEED_LIMIT_SYSTEM" 2 "SPEED_LIMIT_SYSTEM_DISABLED_CAMERA_OBSCURED";
VAL_ 354 FAULT_DAW 0 "HIDDEN" 1 "CHECK_INATTENTIVE_DRIVING_WARNING_SYSTEM" 2 "INATTENTIVE_DRIVING_WARNING_SYSTEM_DISABLED_CAMERA_OBSCURED";
VAL_ 354 FAULT_HBA 0 "HIDDEN" 1 "CHECK_HIGH_BEAM_ASSIST_SYSTEM";
VAL_ 354 FAULT_SCC 0 "HIDDEN" 1 "CHECK_SMART_CRUISE_CONTROL_SYSTEM" 2 "SMART_CRUISE_CONTROL_DISABLED_RADAR_BLOCKED";
VAL_ 354 FAULT_LFA 0 "HIDDEN" 1 "CHECK_LANE_FOLLOWING_SYSTEM_ASSIST_SYSTEM";
VAL_ 354 FAULT_HDA 0 "HIDDEN" 1 "CHECK_HIGHWAY_DRIVING_ASSIST_SYSTEM";
VAL_ 354 FAULT_LCA 0 "HIDDEN" 1 "CHECK_LANE_CHANGE_ASSIST_FUNCTION" 2 "LANE_CHANGE_ASSIST_FUNCTION_DISABLED_CAMERA_OBSCURED" 3 "LANE_CHANGE_ASSIST_FUNCTION_DISABLED_RADAR_BLOCKED";
VAL_ 354 FAULT_HDP 0 "HIDDEN" 1 "CHECK_HIGHWAY_DRIVING_PILOT_SYSTEM" 2 "HIGHWAY_DRIVING_PILOT_DISABLED_CAMERA_OBSCURED" 3 "HIGHWAY_DRIVING_PILOT_DISABLED_RADAR_BLOCKED" 4 "HIGHWAY_DRIVING_PILOT_DISABLED_LIDAR_BLOCKED";
VAL_ 354 FAULT_DAS 0 "HIDDEN" 1 "CHECK_DRIVER_ASSISTANCE_SYSTEM" 2 "DRIVER_ASSISTANCE_SYSTEM_LIMITED_CAMERA_OBSCURED" 3 "DRIVER_ASSISTANCE_SYSTEM_LIMITED_RADAR_BLOCKED" 4 "DRIVER_ASSISTANCE_SYSTEM_LIMITED_CAMERA_OBSCURED_AND_RADAR_BLOCKED";
VAL_ 354 FAULT_ESS 0 "HIDDEN" 1 "CHECK_EMERGENCY_STOPPING_FUNCTION" 2 "EMERGENCY_STOPPING_FUNCTION_DISABLED_CAMERA_OBSCURED" 3 "EMERGENCY_STOPPING_FUNCTION_DISABLED_RADAR_BLOCKED";
VAL_ 362 BLINKER_CONTROL 1 "hazards" 2 "hazards button backlight" 3 "left blinkers" 4 "right blinkers";
VAL_ 373 ACCEnable 0 "SCC ready" 1 "SCC temp fault" 2 "SCC permanent fault" 3 "SCC permanent fault, communication issue";
VAL_ 416 ACCMode 0 "off" 1 "enabled" 2 "driver_override" 3 "off_maybe_fault" 4 "cancelled";
VAL_ 416 SCC_ObjSta 0 "No in-path object detected" 1 "In-path object detected (uncontrollable)" 2 "In-path object detected (controllable:longitudinal)" 3 "Reserved" 4 "Reserved" 5 "Reserved" 6 "Reserved" 7 "Reserved";
VAL_ 426 CRUISE_BUTTONS 0 "none" 1 "res_accel" 2 "set_decel" 3 "gap_distance" 4 "pause_resume";
VAL_ 437 Info_LftLnQualSta 0 "Very Low Quality" 1 "Low Quality" 2 "High Quality" 3 "Very High Quality" 4 "Reserved" 5 "Reserved" 6 "Reserved" 7 "Error indicator";
VAL_ 437 Info_LftLnDptSta 0 "No Left Line Departure" 1 "Left Line Departure" 2 "Reserved" 3 "Error Indicator";
VAL_ 437 Info_RtLnQualSta 0 "Very Low Quality" 1 "Low Quality" 2 "High Quality" 3 "Very High Quality" 4 "Reserved" 5 "Reserved" 6 "Reserved" 7 "Error indicator";
VAL_ 437 Info_RtLnDptSta 0 "No Right Line Departure" 1 "Right Line Departure" 2 "Reserved" 3 "Error Indicator";
VAL_ 437 Info_RtLnCvtrVal 65534 "Reserved" 65535 "Error indicator";
VAL_ 442 BCW_LtIndSta 0 "No detection" 1 "Blind-spot warning active" 2 "Blind-spot warning + blinker, flashing" 3 "Reserved";
VAL_ 442 BCW_RtIndSta 0 "No detection" 1 "Blind-spot warning active" 2 "Blind-spot warning + blinker, flashing" 3 "Reserved";
VAL_ 463 CRUISE_BUTTONS 0 "none" 1 "res_accel" 2 "set_decel" 3 "gap_distance" 4 "pause_resume";
VAL_ 463 RIGHT_PADDLE 0 "Not Pulled" 1 "Pulled";
VAL_ 463 LEFT_PADDLE 0 "Not Pulled" 1 "Pulled";
VAL_ 506 ISLW_OptUsmSta 0 "None ISLW Option (Default)" 1 "System Disabled by USM" 2 "System Enable by USM" 3 "Invalid";
VAL_ 506 ISLW_SysSta 0 "Normal (Default)" 1 "System Fail" 2 "ISLW Temporary Unavailable" 3 "Reserved";
VAL_ 506 ISLW_NoPassingInfoDis 0 "None Display (Default)" 1 "LHD No Passing Zone Display" 2 "RHD No Passing Zone Display" 3 "Reserved" 4 "Reserved" 5 "Reserved" 6 "Reserved" 7 "Invalid";
VAL_ 506 ISLW_OvrlpSignDis 0 "None (Default)" 1 "Overlap Sign" 2 "Reserved" 3 "Error indicator";
VAL_ 506 ISLW_SpdCluMainDis 0 "No Recognition (Default)" 253 "Unlimited Speed" 254 "Reserved" 255 "Invalid";
VAL_ 506 ISLW_SpdNaviMainDis 0 "No Recognition (Default)" 253 "Unlimited Speed" 254 "Reserved" 255 "Invalid";
VAL_ 506 ISLW_SubCondinfoSta1 0 "None (Default)" 1 "Rain" 2 "Snow" 3 "Snow&Rain" 4 "Trailer" 5 "Reserved" 6 "Reserved" 7 "Reserved" 8 "Reserved" 9 "Reserved" 10 "Reserved" 11 "Reserved" 12 "Reserved" 13 "Reserved" 14 "Generic" 15 "Invalid";
VAL_ 506 ISLW_SubCondinfoSta2 0 "None (Default)" 1 "Rain" 2 "Snow" 3 "Snow&Rain" 4 "Trailer" 5 "Reserved" 6 "Reserved" 7 "Reserved" 8 "Reserved" 9 "Reserved" 10 "Reserved" 11 "Reserved" 12 "Reserved" 13 "Reserved" 14 "Generic" 15 "Invalid";
VAL_ 506 ISLW_SpdCluSubMainDis 0 "No Recognition (Default)" 253 "Unlimited Speed" 254 "Reserved" 255 "Invalid";
VAL_ 506 ISLW_SpdCluDisSubCond1 0 "No Recognition (Default)" 253 "LHD Conditional No Passing ZONE" 254 "RHD Conditional No Passing ZONE" 255 "Invalid";
VAL_ 506 ISLW_SpdCluDisSubCond2 0 "No Recognition (Default)" 253 "LHD Conditional No Passing ZONE" 254 "RHD Conditional No Passing ZONE" 255 "Invalid";
VAL_ 506 ISLW_SpdNaviSubMainDis 0 "No Recognition (Default)" 253 "Unlimited Speed" 254 "Reserved" 255 "Invalid";
VAL_ 506 ISLW_SpdNaviDisSubCond1 0 "No Recognition (Default)" 253 "LHD Conditional No Passing ZONE" 254 "RHD Conditional No Passing ZONE" 255 "Invalid";
VAL_ 506 ISLW_SpdNaviDisSubCond2 0 "No Recognition (Default)" 253 "LHD Conditional No Passing ZONE" 254 "RHD Conditional No Passing ZONE" 255 "Invalid";
VAL_ 506 ISLA_SpdwOffst 0 "No Recognition" 253 "Unlimited Speed" 254 "Reserved" 255 "Invalid";
VAL_ 506 ISLA_SwIgnoreReq 0 "Allow All Switch Inputs (default)" 1 "-(SET) Switch Input Ignore" 2 "+(SET) Switch Input Ignore" 3 "-(SET) & +(SET) Switch Inputs Ignore";
VAL_ 506 ISLA_SpdChgReq 0 "Default" 1 "Speed Change Request" 2 "Reserved" 3 "Reserved";
VAL_ 506 ISLA_SpdWrn 0 "No Warning" 1 "Warning" 2 "Reserved" 3 "Reserved";
VAL_ 506 ISLA_IcyWrn 0 "No Warning" 1 "Warning" 2 "Reserved" 3 "Reserved";
VAL_ 506 ISLA_SymFlashMod 0 "No Flasing" 1 "Flashing Sign" 2 "Flashing - Arrow Symbol" 3 "Flashing + Arrow Symbol" 4 "Flashing Auto Symbol" 5 "Reserved" 6 "Reserved" 7 "Reserved";
VAL_ 506 ISLA_Popup 0 "No Popup" 1 "MSLA Speed will Change" 2 "MSLA Speed has Changed" 3 "CC_SCC Speed will Change" 4 "CC_SCC Speed has Changed" 5 "Reserved" 6 "Reserved" 7 "Reserved";
VAL_ 506 ISLA_OptUsmSta 0 "None ISLA Option (속도 제한 메뉴 삭제)" 1 "Off" 2 "Warning" 3 "Assist" 4 "Reserved" 5 "Reserved" 6 "Reserved" 7 "Invalid (GRAY)";
VAL_ 506 ISLA_OffstUsmSta 0 "None Offset Function" 1 "-10kph or -5mph" 2 "-5kph or -3mph" 3 "0kph or 0mph" 4 "+5kph or +3mph" 5 "+10kph or +5mph" 6 "Reserved" 7 "Invalid (GRAY)";
VAL_ 506 ISLA_AutoUsmSta 0 "None Auto Function (Delete Menu)" 1 "Auto Off" 2 "Auto On" 3 "Invalid (GRAY)";
VAL_ 506 ISLA_Cntry 0 "Europe/Russia/Australia" 1 "Domestic" 2 "China" 3 "USA" 4 "Canada" 5 "Australia" 6 "Reserved" 7 "Reserved" 8 "Reserved" 9 "Reserved" 10 "Reserved" 11 "Reserved" 12 "Reserved" 13 "Reserved" 14 "Reserved" 15 "Initial Value (default)";
VAL_ 506 ISLA_AddtnlSign 0 "No Recognition (default)" 1 "School Crossing" 16 "Do Not Pass" 17 "Reserved" 18 "Reserved" 19 "Reserved" 20 "Reserved" 21 "Reserved" 22 "Reserved" 23 "Reserved" 24 "Exit" 25 "Roundabout" 26 "Right Curve" 27 "Left Curve" 28 "Winding Road" 29 "Reserved" 30 "Reserved" 31 "Reserved" 2 "Pedestrian Crossing" 3 "Bicycle Crossing" 4 "Reserved" 5 "Reserved" 6 "Reserved" 7 "Reserved" 8 "Stop" 9 "Yield" 10 "Stop Ahead" 11 "Yield Ahead" 12 "Road Construction Ahead" 13 "Lane Reduction" 14 "Reserved" 15 "Reserved";
VAL_ 506 ISLA_SchoolZone 0 "No School Zone" 1 "School Zone" 2 "Reserved" 3 "Reserved";
VAL_ 687 HOD_Dir_Status 0 "HANDS OFF" 1 "HAND TOUCH (SOFT)" 2 "HAND TOUCH (STRONG)" 3 "HAND GRIP (SOFT)" 4 "HAND GRIP (STRONG)" 5 "RESERVED" 6 "RESERVED";
VAL_ 698 IFSref_FR_CMR_Sta 0 "None Option (Default)" 1 "Normal" 2 "Blockage Status" 3 "Error Indicator";
VAL_ 698 IFSref_VehNumVal 0 "No vehicle" 1 "Number of vehicles" 2 "Number of vehicles" 3 "Number of vehicles" 4 "Number of vehicles" 5 "Number of vehicles" 6 "Number of vehicles" 7 "Number of vehicles" 8 "Number of vehicles" 9 "Number of vehicles" 10 "Number of vehicles" 11 "Over than 10 vehicles" 12 "Reserved" 13 "Reserved" 14 "Default" 15 "Error indicator";
VAL_ 698 IFSref_ILLAmbtSta 0 "Bright" 1 "Dark" 2 "Not used" 3 "Error indicator";
VAL_ 698 IFSref_VehLftAngl1Val 501 "Not used" 502 "Not used" 503 "Not used" 504 "Not used" 505 "Not used" 506 "Not used" 507 "Not used" 508 "Not used" 509 "Not used" 510 "Default" 511 "Error indicator";
VAL_ 698 IFSref_VehRtAngl1Val 501 "Not used" 502 "Not used" 503 "Not used" 504 "Not used" 505 "Not used" 506 "Not used" 507 "Not used" 508 "Not used" 509 "Not used" 510 "Default" 511 "Error indicator";
VAL_ 698 IFSref_VehLftAngl2Val 501 "Not used" 502 "Not used" 503 "Not used" 504 "Not used" 505 "Not used" 506 "Not used" 507 "Not used" 508 "Not used" 509 "Not used" 510 "Default" 511 "Error indicator";
VAL_ 698 IFSref_VehDst1Val 0 "No Value" 1 "1~10m" 2 "11~20m" 3 "21~30m" 4 "31~40m" 5 "41~50m" 6 "51~60m" 7 "61~70m" 8 "71~80m" 9 "81~90m" 10 "91~100m" 11 "101~200m" 12 "201~300m" 13 "301~400m" 14 "401m~" 15 "Error indicator";
VAL_ 698 IFSref_VehRtAngl2Val 501 "Not used" 502 "Not used" 503 "Not used" 504 "Not used" 505 "Not used" 506 "Not used" 507 "Not used" 508 "Not used" 509 "Not used" 510 "Default" 511 "Error indicator";
VAL_ 698 IFSref_VehLftAngl3Val 501 "Not used" 502 "Not used" 503 "Not used" 504 "Not used" 505 "Not used" 506 "Not used" 507 "Not used" 508 "Not used" 509 "Not used" 510 "Default" 511 "Error indicator";
VAL_ 698 IFSref_VehRtAngl3Val 501 "Not used" 502 "Not used" 503 "Not used" 504 "Not used" 505 "Not used" 506 "Not used" 507 "Not used" 508 "Not used" 509 "Not used" 510 "Default" 511 "Error indicator";
VAL_ 698 IFSref_VehLftAngl4Val 501 "Not used" 502 "Not used" 503 "Not used" 504 "Not used" 505 "Not used" 506 "Not used" 507 "Not used" 508 "Not used" 509 "Not used" 510 "Default" 511 "Error indicator";
VAL_ 698 IFSref_VehRtAngl4Val 501 "Not used" 502 "Not used" 503 "Not used" 504 "Not used" 505 "Not used" 506 "Not used" 507 "Not used" 508 "Not used" 509 "Not used" 510 "Default" 511 "Error indicator";
VAL_ 698 IFSref_VehLftAngl5Val 501 "Not used" 502 "Not used" 503 "Not used" 504 "Not used" 505 "Not used" 506 "Not used" 507 "Not used" 508 "Not used" 509 "Not used" 510 "Default" 511 "Error indicator";
VAL_ 698 IFSref_VehRtAngl5Val 501 "Not used" 502 "Not used" 503 "Not used" 504 "Not used" 505 "Not used" 506 "Not used" 507 "Not used" 508 "Not used" 509 "Not used" 510 "Default" 511 "Error indicator";
VAL_ 698 IFSref_VehLftAngl6Val 501 "Not used" 502 "Not used" 503 "Not used" 504 "Not used" 505 "Not used" 506 "Not used" 507 "Not used" 508 "Not used" 509 "Not used" 510 "Default" 511 "Error indicator";
VAL_ 698 IFSref_VehRtAngl6Val 501 "Not used" 502 "Not used" 503 "Not used" 504 "Not used" 505 "Not used" 506 "Not used" 507 "Not used" 508 "Not used" 509 "Not used" 510 "Default" 511 "Error indicator";
VAL_ 698 IFSref_VehLftAngl7Val 501 "Not used" 502 "Not used" 503 "Not used" 504 "Not used" 505 "Not used" 506 "Not used" 507 "Not used" 508 "Not used" 509 "Not used" 510 "Default" 511 "Error indicator";
VAL_ 698 IFSref_VehRtAngl7Val 501 "Not used" 502 "Not used" 503 "Not used" 504 "Not used" 505 "Not used" 506 "Not used" 507 "Not used" 508 "Not used" 509 "Not used" 510 "Default" 511 "Error indicator";
VAL_ 698 IFSref_VehLftAngl8Val 501 "Not used" 502 "Not used" 503 "Not used" 504 "Not used" 505 "Not used" 506 "Not used" 507 "Not used" 508 "Not used" 509 "Not used" 510 "Default" 511 "Error indicator";
VAL_ 698 IFSref_VehRtAngl8Val 501 "Not used" 502 "Not used" 503 "Not used" 504 "Not used" 505 "Not used" 506 "Not used" 507 "Not used" 508 "Not used" 509 "Not used" 510 "Default" 511 "Error indicator";
VAL_ 698 IFSref_VehLftAngl9Val 501 "Not used" 502 "Not used" 503 "Not used" 504 "Not used" 505 "Not used" 506 "Not used" 507 "Not used" 508 "Not used" 509 "Not used" 510 "Default" 511 "Error indicator";
VAL_ 698 IFSref_VehRtAngl9Val 501 "Not used" 502 "Not used" 503 "Not used" 504 "Not used" 505 "Not used" 506 "Not used" 507 "Not used" 508 "Not used" 509 "Not used" 510 "Default" 511 "Error indicator";
VAL_ 698 IFSref_VehLftAngl10Val 501 "Not used" 502 "Not used" 503 "Not used" 504 "Not used" 505 "Not used" 506 "Not used" 507 "Not used" 508 "Not used" 509 "Not used" 510 "Default" 511 "Error indicator";
VAL_ 698 IFSref_VehRtAngl10Val 501 "Not used" 502 "Not used" 503 "Not used" 504 "Not used" 505 "Not used" 506 "Not used" 507 "Not used" 508 "Not used" 509 "Not used" 510 "Default" 511 "Error indicator";
VAL_ 698 IFSref_VehDst2Val 0 "No Value" 1 "1~10m" 2 "11~20m" 3 "21~30m" 4 "31~40m" 5 "41~50m" 6 "51~60m" 7 "61~70m" 8 "71~80m" 9 "81~90m" 10 "91~100m" 11 "101~200m" 12 "201~300m" 13 "301~400m" 14 "401m~" 15 "Error indicator";
VAL_ 698 IFSref_VehDst3Val 0 "No Value" 1 "1~10m" 2 "11~20m" 3 "21~30m" 4 "31~40m" 5 "41~50m" 6 "51~60m" 7 "61~70m" 8 "71~80m" 9 "81~90m" 10 "91~100m" 11 "101~200m" 12 "201~300m" 13 "301~400m" 14 "401m~" 15 "Error indicator";
VAL_ 698 IFSref_VehDst4Val 0 "No Value" 1 "1~10m" 2 "11~20m" 3 "21~30m" 4 "31~40m" 5 "41~50m" 6 "51~60m" 7 "61~70m" 8 "71~80m" 9 "81~90m" 10 "91~100m" 11 "101~200m" 12 "201~300m" 13 "301~400m" 14 "401m~" 15 "Error indicator";
VAL_ 698 IFSref_VehDst5Val 0 "No Value" 1 "1~10m" 2 "11~20m" 3 "21~30m" 4 "31~40m" 5 "41~50m" 6 "51~60m" 7 "61~70m" 8 "71~80m" 9 "81~90m" 10 "91~100m" 11 "101~200m" 12 "201~300m" 13 "301~400m" 14 "401m~" 15 "Error indicator";
VAL_ 698 IFSref_VehDst6Val 0 "No Value" 1 "1~10m" 2 "11~20m" 3 "21~30m" 4 "31~40m" 5 "41~50m" 6 "51~60m" 7 "61~70m" 8 "71~80m" 9 "81~90m" 10 "91~100m" 11 "101~200m" 12 "201~300m" 13 "301~400m" 14 "401m~" 15 "Error indicator";
VAL_ 698 IFSref_VehDst7Val 0 "No Value" 1 "1~10m" 2 "11~20m" 3 "21~30m" 4 "31~40m" 5 "41~50m" 6 "51~60m" 7 "61~70m" 8 "71~80m" 9 "81~90m" 10 "91~100m" 11 "101~200m" 12 "201~300m" 13 "301~400m" 14 "401m~" 15 "Error indicator";
VAL_ 698 IFSref_VehDst8Val 0 "No Value" 1 "1~10m" 2 "11~20m" 3 "21~30m" 4 "31~40m" 5 "41~50m" 6 "51~60m" 7 "61~70m" 8 "71~80m" 9 "81~90m" 10 "91~100m" 11 "101~200m" 12 "201~300m" 13 "301~400m" 14 "401m~" 15 "Error indicator";
VAL_ 698 IFSref_VehDst9Val 0 "No Value" 1 "1~10m" 2 "11~20m" 3 "21~30m" 4 "31~40m" 5 "41~50m" 6 "51~60m" 7 "61~70m" 8 "71~80m" 9 "81~90m" 10 "91~100m" 11 "101~200m" 12 "201~300m" 13 "301~400m" 14 "401m~" 15 "Error indicator";
VAL_ 698 IFSref_VehDst10Val 0 "No Value" 1 "1~10m" 2 "11~20m" 3 "21~30m" 4 "31~40m" 5 "41~50m" 6 "51~60m" 7 "61~70m" 8 "71~80m" 9 "81~90m" 10 "91~100m" 11 "101~200m" 12 "201~300m" 13 "301~400m" 14 "401m~" 15 "Error indicator";
VAL_ 736 MSLA_STATUS 0 "disabled" 1 "active" 2 "paused";
VAL_ 866 LEFT_LANE_LINE 0 "Not Detected" 1 "Low Confidence" 2 "Medium Confidence" 3 "High Confidence";
VAL_ 866 RIGHT_LANE_LINE 0 "Not Detected" 1 "Low Confidence" 2 "Medium Confidence" 3 "High Confidence";
VAL_ 1041 DRIVER_DOOR 0 "Closed" 1 "Opened";
VAL_ 1041 PASSENGER_DOOR 0 "Closed" 1 "Opened";
VAL_ 1041 PASSENGER_SEATBELT 0 "Unlatched" 1 "Latched";
VAL_ 1041 DRIVER_SEATBELT 0 "Unlatched" 1 "Latched";
VAL_ 1041 DRIVER_REAR_DOOR 0 "Closed" 1 "Opened";
VAL_ 1041 PASSENGER_REAR_DOOR 0 "Closed" 1 "Opened";
VAL_ 1144 DRIVE_MODE2 3 "Set Sport" 1 "Set Normal" 2 "Set Eco";
VAL_ 1240 DISTANCE_UNIT 1 "Miles" 0 "Kilometers";
VAL_ 298 LKA_OnOffEquip2Sta 0 "Off" 1 "LFA" 2 "LKA only" 3 "Fault";
VAL_ 480 LFA_ICON 0 "HIDDEN" 1 "GRAY" 2 "GREEN" 3 "WHITE";
VAL_ 480 NEW_SIGNAL_1 0 "None" 5 "Hands-off warning 1" 6 "Hands-off warning 2";
VAL_ 480 CAM_FAULT 0 "OK" 1 "Camera fault";
VAL_ 480 LFA_HANDSOFF_CANCEL 0 "None" 1 "LFA cancelled for hands-off";
